VERSION "HNNBNNNYNNNNNNNNNNNNNNNNNNNNNNNNNNNNNNNNNN/4/%%%/4/'%**4NNN///"

NS_ :

BS_:

BU_: AWC BAP_Tester BMC_MLBevo BMS_MV BMS_NV DCDC_800V_PAG DCDC_HV DCDC_HV_02 DCDC_IHEV FCU_MLBevo_FCEV Gateway Gateway_PAG Ladegeraet_2 Ladegeraet_Konzern LE1 LE2 LE2_3_MLBevo_LB LE_MLBevo LE_MLBevo_LB Sub_Gateway TME

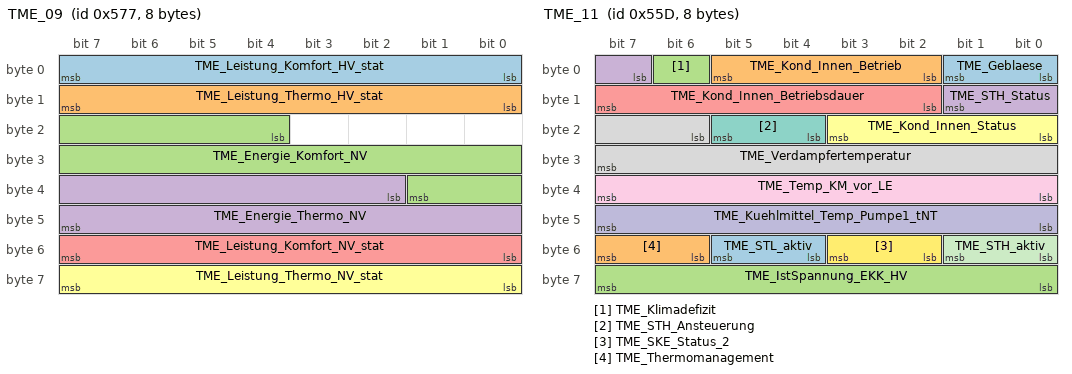
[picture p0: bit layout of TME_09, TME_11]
BO_ 1399 TME_09: 8 TME
 SG_ TME_Leistung_Komfort_HV_stat : 0|8@1+ (50,0) [0|12650] "Unit_Watt"  Ladegeraet_Konzern
 SG_ TME_Leistung_Thermo_HV_stat : 8|8@1+ (50,0) [0|12650] "Unit_Watt"  Ladegeraet_Konzern
 SG_ TME_Energie_Komfort_NV : 20|14@1+ (5,0) [0|63250] "Unit_WattHour"  Ladegeraet_Konzern
 SG_ TME_Energie_Thermo_NV : 34|14@1+ (5,0) [0|63250] "Unit_WattHour"  Ladegeraet_Konzern
 SG_ TME_Leistung_Komfort_NV_stat : 48|8@1+ (10,0) [0|2530] "Unit_Watt"  Ladegeraet_Konzern
 SG_ TME_Leistung_Thermo_NV_stat : 56|8@1+ (10,0) [0|2530] "Unit_Watt"  Ladegeraet_Konzern

BO_ 1375 TME_10: 8 TME
 SG_ TME_VoKo_Strategie_Anzeige : 2|4@1+ (1,0) [0|15] ""  Gateway,Gateway_PAG,Ladegeraet_Konzern
 SG_ TME_Zuheizer_Freigabe : 6|1@1+ (1,0) [0|1] ""  Gateway,Gateway_PAG
 SG_ TME_AC_LED : 7|1@1+ (1,0) [0|1] ""  Gateway,Gateway_PAG
 SG_ TME_Heizstrategie : 8|4@1+ (1,0) [0|15] ""  Gateway,Gateway_PAG,Ladegeraet_Konzern
 SG_ TME_Systemstatus : 12|2@1+ (1,0) [0|3] ""  Gateway,Gateway_PAG
 SG_ TME_Kbr_Innenraum : 14|1@1+ (1,0) [0|1] ""  Gateway,Gateway_PAG
 SG_ TME_Freigabe_Vorkond : 15|1@1+ (1,0) [0|1] ""  Gateway,Gateway_PAG,Ladegeraet_Konzern
 SG_ TME_Verdampfer_Status : 16|1@1+ (1,0) [0|1] ""  Gateway,Gateway_PAG
 SG_ TME_Kuehlmittel_Sensor : 17|1@1+ (1,0) [0|1] ""  BMC_MLBevo,Gateway,Gateway_PAG
 SG_ TME_AC_Rueckmeldung : 18|2@1+ (1,0) [0|3] ""  Gateway,Gateway_PAG
 SG_ TME_Heizungspumpen_Anst : 20|4@1+ (10,0) [0|100] "Unit_PerCent"  FCU_MLBevo_FCEV,Gateway,Gateway_PAG
 SG_ TME_Frischluftklappe_Soll : 24|7@1+ (1,0) [0|100] "Unit_PerCent"  Gateway,Gateway_PAG
 SG_ TME_Freigabe_Luft_PTC : 31|1@1+ (1,0) [0|1] ""  Gateway,Gateway_PAG
 SG_ TME_Umluftklappe_Soll : 32|7@1+ (1,0) [0|100] "Unit_PerCent"  Gateway,Gateway_PAG
 SG_ TME_Waermepumpe_aktiv : 39|1@1+ (1,0) [0|1] ""  Gateway,Gateway_PAG
 SG_ TME_Nachlaufzeit_Heizp : 40|6@1+ (15,0) [0|945] "Unit_Secon"  Gateway,Gateway_PAG
 SG_ TME_Absperrventil1_oeffnen : 46|2@1+ (1,0) [0|3] ""  Gateway,Gateway_PAG
 SG_ TME_Klima_Defizit : 48|8@1+ (40,0) [0|10000] "Unit_Watt"  Gateway,Gateway_PAG
 SG_ TME_Temp_KM_vor_HWT : 56|8@1+ (0.75,-40) [-40|149.75] "Unit_DegreCelsi"  Gateway,Gateway_PAG

BO_ 1373 TME_11: 8 TME
 SG_ TME_Geblaese : 0|2@1+ (1,0) [0|3] ""  Gateway,Gateway_PAG
 SG_ TME_Kond_Innen_Betrieb : 2|4@1+ (1,0) [0|15] ""  Gateway,Gateway_PAG,Ladegeraet_Konzern
 SG_ TME_Klimadefizit : 6|1@1+ (1,0) [0|1] ""  Gateway,Gateway_PAG
 SG_ TME_STH_Status : 7|3@1+ (1,0) [0|7] ""  Gateway,Gateway_PAG,Ladegeraet_Konzern
 SG_ TME_Kond_Innen_Betriebsdauer : 10|6@1+ (1,0) [0|60] "Unit_Minut"  Gateway,Gateway_PAG,Ladegeraet_Konzern
 SG_ TME_Kond_Innen_Status : 16|4@1+ (1,0) [0|15] ""  Gateway,Gateway_PAG,Ladegeraet_Konzern
 SG_ TME_STH_Ansteuerung : 20|2@1+ (1,0) [0|3] ""  Gateway,Gateway_PAG
 SG_ TME_Verdampfertemperatur : 22|10@1+ (0.1,-20) [-20|70] "Unit_DegreCelsi"  Gateway,Gateway_PAG
 SG_ TME_Temp_KM_vor_LE : 32|8@1+ (0.75,-48) [-48|141.75] "Unit_DegreCelsi"  Gateway,Gateway_PAG,LE1,LE2,LE_MLBevo
 SG_ TME_Kuehlmittel_Temp_Pumpe1_tNT : 40|8@1+ (1,-40) [-40|213] "Unit_DegreCelsi"  BMC_MLBevo,Gateway,Gateway_PAG
 SG_ TME_STH_aktiv : 48|2@1+ (1,0) [0|3] ""  Gateway,Gateway_PAG
 SG_ TME_SKE_Status_2 : 50|2@1+ (1,0) [0|3] ""  Gateway,Gateway_PAG
 SG_ TME_STL_aktiv : 52|2@1+ (1,0) [0|3] ""  Gateway,Gateway_PAG
 SG_ TME_Thermomanagement : 54|2@1+ (1,0) [0|3] ""  Gateway,Gateway_PAG
 SG_ TME_IstSpannung_EKK_HV : 56|8@1+ (2,0) [0|508] "Unit_Volt"  BMC_MLBevo,DCDC_800V_PAG,Gateway,Gateway_PAG

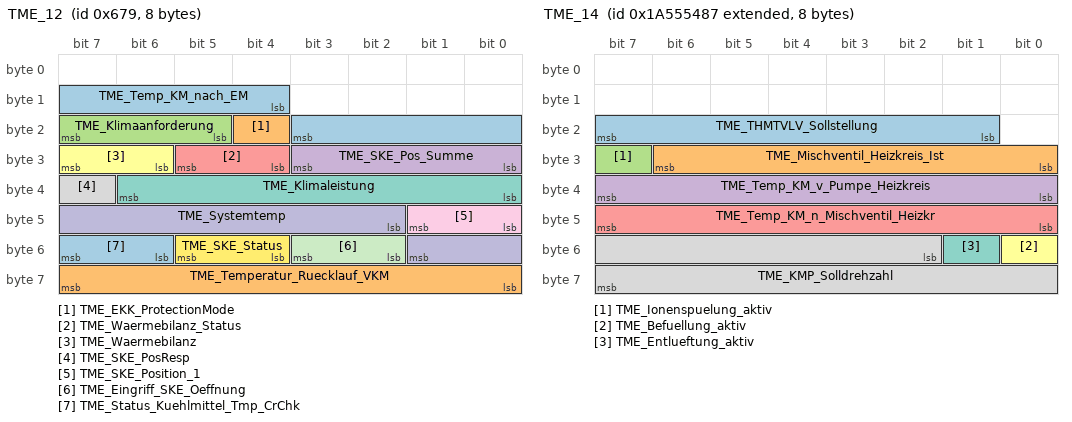
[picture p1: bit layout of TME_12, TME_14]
BO_ 1657 TME_12: 8 TME
 SG_ TME_Temp_KM_nach_EM : 12|8@1+ (0.75,-48) [-48|141] "Unit_DegreCelsi"  Gateway,Gateway_PAG
 SG_ TME_EKK_ProtectionMode : 20|1@1+ (1,0) [0|1] ""  Gateway,Gateway_PAG
 SG_ TME_Klimaanforderung : 21|3@1+ (1,0) [0|7] ""  Gateway,Gateway_PAG
 SG_ TME_SKE_Pos_Summe : 24|4@1+ (10,0) [0|100] "Unit_PerCent"  Gateway,Gateway_PAG
 SG_ TME_Waermebilanz_Status : 28|2@1+ (1,0) [0|3] ""  Gateway,Gateway_PAG
 SG_ TME_Waermebilanz : 30|2@1+ (1,0) [0|3] ""  Gateway,Gateway_PAG
 SG_ TME_Klimaleistung : 32|7@1+ (0.04,0) [0|5] "Unit_KiloWatt"  Gateway,Gateway_PAG
 SG_ TME_SKE_PosResp : 39|1@1+ (1,0) [0|1] ""  Gateway,Gateway_PAG
 SG_ TME_SKE_Position_1 : 40|2@1+ (1,0) [0|3] ""  Gateway,Gateway_PAG
 SG_ TME_Systemtemp : 42|8@1+ (0.75,-48) [-48|141.75] "Unit_DegreCelsi"  Gateway,Gateway_PAG
 SG_ TME_Eingriff_SKE_Oeffnung : 50|2@1+ (1,0) [0|3] ""  Gateway,Gateway_PAG
 SG_ TME_SKE_Status : 52|2@1+ (1,0) [0|3] ""  Gateway,Gateway_PAG
 SG_ TME_Status_Kuehlmittel_Tmp_CrChk : 54|2@1+ (1,0) [0|3] ""  Gateway,Gateway_PAG
 SG_ TME_Temperatur_Ruecklauf_VKM : 56|8@1+ (0.75,-40) [-40|149.75] "Unit_DegreCelsi"  Gateway,Gateway_PAG

BO_ 2463978655 TME_13: 8 TME
 SG_ TME_Senkenleistung_verfuegbar : 55|9@1+ (0.1,0) [0|50.9] "Unit_KiloWatt"  FCU_MLBevo_FCEV,Gateway

BO_ 2589283463 TME_14: 8 TME
 SG_ TME_THMTVLV_Sollstellung : 17|7@1+ (1,0) [0|100] "Unit_PerCent"  FCU_MLBevo_FCEV
 SG_ TME_Mischventil_Heizkreis_Ist : 24|7@1+ (1,0) [0|100] "Unit_PerCent"  FCU_MLBevo_FCEV
 SG_ TME_Ionenspuelung_aktiv : 31|1@1+ (1,0) [0|1] ""  FCU_MLBevo_FCEV
 SG_ TME_Temp_KM_v_Pumpe_Heizkreis : 32|8@1+ (0.75,-48) [-48|141.75] "Unit_DegreCelsi"  FCU_MLBevo_FCEV
 SG_ TME_Temp_KM_n_Mischventil_Heizkr : 40|8@1+ (0.75,-48) [-48|141.75] "Unit_DegreCelsi"  FCU_MLBevo_FCEV
 SG_ TME_Befuellung_aktiv : 48|1@1+ (1,0) [0|1] ""  FCU_MLBevo_FCEV
 SG_ TME_Entlueftung_aktiv : 49|1@1+ (1,0) [0|1] ""  FCU_MLBevo_FCEV
 SG_ TME_KMP_Solldrehzahl : 50|14@1+ (1,0) [0|16381] "Unit_RevPerMinute"  FCU_MLBevo_FCEV

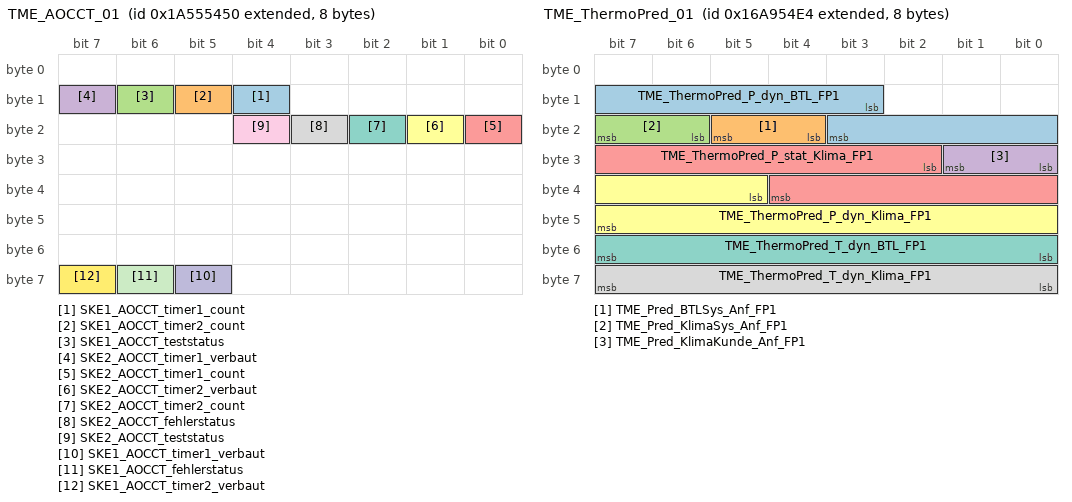
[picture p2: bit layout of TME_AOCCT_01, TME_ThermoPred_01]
BO_ 2589283408 TME_AOCCT_01: 8 TME
 SG_ SKE1_AOCCT_timer1_count : 12|1@1+ (1,0) [0|1] ""  Gateway,Gateway_PAG
 SG_ SKE1_AOCCT_timer2_count : 13|1@1+ (1,0) [0|1] ""  Gateway,Gateway_PAG
 SG_ SKE1_AOCCT_teststatus : 14|1@1+ (1,0) [0|1] ""  Gateway,Gateway_PAG
 SG_ SKE2_AOCCT_timer1_verbaut : 15|1@1+ (1,0) [0|1] ""  Gateway,Gateway_PAG
 SG_ SKE2_AOCCT_timer1_count : 16|1@1+ (1,0) [0|1] ""  Gateway,Gateway_PAG
 SG_ SKE2_AOCCT_timer2_verbaut : 17|1@1+ (1,0) [0|1] ""  Gateway,Gateway_PAG
 SG_ SKE2_AOCCT_timer2_count : 18|1@1+ (1,0) [0|1] ""  Gateway,Gateway_PAG
 SG_ SKE2_AOCCT_fehlerstatus : 19|1@1+ (1,0) [0|1] ""  Gateway,Gateway_PAG
 SG_ SKE2_AOCCT_teststatus : 20|1@1+ (1,0) [0|1] ""  Gateway,Gateway_PAG
 SG_ SKE1_AOCCT_timer1_verbaut : 61|1@1+ (1,0) [0|1] ""  Gateway,Gateway_PAG
 SG_ SKE1_AOCCT_fehlerstatus : 62|1@1+ (1,0) [0|1] ""  Gateway,Gateway_PAG
 SG_ SKE1_AOCCT_timer2_verbaut : 63|1@1+ (1,0) [0|1] ""  Gateway,Gateway_PAG

BO_ 2527679716 TME_ThermoPred_01: 8 TME
 SG_ TME_ThermoPred_P_dyn_BTL_FP1 : 11|9@1+ (50,0) [0|20450] "Unit_Watt"  Gateway,Gateway_PAG
 SG_ TME_Pred_BTLSys_Anf_FP1 : 20|2@1+ (1,0) [0|3] ""  Gateway,Gateway_PAG
 SG_ TME_Pred_KlimaSys_Anf_FP1 : 22|2@1+ (1,0) [0|3] ""  Gateway,Gateway_PAG
 SG_ TME_Pred_KlimaKunde_Anf_FP1 : 24|2@1+ (1,0) [0|3] ""  Gateway,Gateway_PAG
 SG_ TME_ThermoPred_P_stat_Klima_FP1 : 26|11@1+ (10,0) [0|20450] "Unit_Watt"  Gateway,Gateway_PAG
 SG_ TME_ThermoPred_P_dyn_Klima_FP1 : 37|11@1+ (10,0) [0|20450] "Unit_Watt"  Gateway,Gateway_PAG
 SG_ TME_ThermoPred_T_dyn_BTL_FP1 : 48|8@1+ (1,0) [0|253] "Unit_Minut"  Gateway,Gateway_PAG
 SG_ TME_ThermoPred_T_dyn_Klima_FP1 : 56|8@1+ (1,0) [0|253] "Unit_Minut"  Gateway,Gateway_PAG

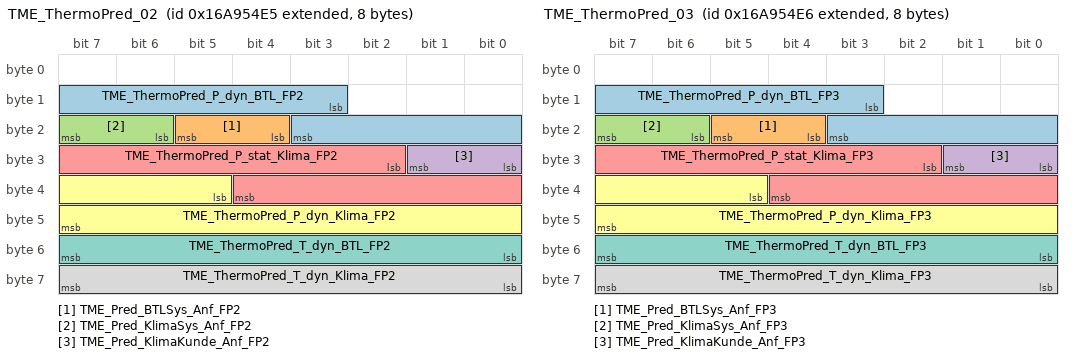
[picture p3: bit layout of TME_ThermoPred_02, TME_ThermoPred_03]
BO_ 2527679717 TME_ThermoPred_02: 8 TME
 SG_ TME_ThermoPred_P_dyn_BTL_FP2 : 11|9@1+ (50,0) [0|20450] "Unit_Watt"  Gateway,Gateway_PAG
 SG_ TME_Pred_BTLSys_Anf_FP2 : 20|2@1+ (1,0) [0|3] ""  Gateway,Gateway_PAG
 SG_ TME_Pred_KlimaSys_Anf_FP2 : 22|2@1+ (1,0) [0|3] ""  Gateway,Gateway_PAG
 SG_ TME_Pred_KlimaKunde_Anf_FP2 : 24|2@1+ (1,0) [0|3] ""  Gateway,Gateway_PAG
 SG_ TME_ThermoPred_P_stat_Klima_FP2 : 26|11@1+ (10,0) [0|20450] "Unit_Watt"  Gateway,Gateway_PAG
 SG_ TME_ThermoPred_P_dyn_Klima_FP2 : 37|11@1+ (10,0) [0|20450] "Unit_Watt"  Gateway,Gateway_PAG
 SG_ TME_ThermoPred_T_dyn_BTL_FP2 : 48|8@1+ (1,0) [0|253] "Unit_Minut"  Gateway,Gateway_PAG
 SG_ TME_ThermoPred_T_dyn_Klima_FP2 : 56|8@1+ (1,0) [0|253] "Unit_Minut"  Gateway,Gateway_PAG

BO_ 2527679718 TME_ThermoPred_03: 8 TME
 SG_ TME_ThermoPred_P_dyn_BTL_FP3 : 11|9@1+ (50,0) [0|20450] "Unit_Watt"  Gateway,Gateway_PAG
 SG_ TME_Pred_BTLSys_Anf_FP3 : 20|2@1+ (1,0) [0|3] ""  Gateway,Gateway_PAG
 SG_ TME_Pred_KlimaSys_Anf_FP3 : 22|2@1+ (1,0) [0|3] ""  Gateway,Gateway_PAG
 SG_ TME_Pred_KlimaKunde_Anf_FP3 : 24|2@1+ (1,0) [0|3] ""  Gateway,Gateway_PAG
 SG_ TME_ThermoPred_P_stat_Klima_FP3 : 26|11@1+ (10,0) [0|20450] "Unit_Watt"  Gateway,Gateway_PAG
 SG_ TME_ThermoPred_P_dyn_Klima_FP3 : 37|11@1+ (10,0) [0|20450] "Unit_Watt"  Gateway,Gateway_PAG
 SG_ TME_ThermoPred_T_dyn_BTL_FP3 : 48|8@1+ (1,0) [0|253] "Unit_Minut"  Gateway,Gateway_PAG
 SG_ TME_ThermoPred_T_dyn_Klima_FP3 : 56|8@1+ (1,0) [0|253] "Unit_Minut"  Gateway,Gateway_PAG

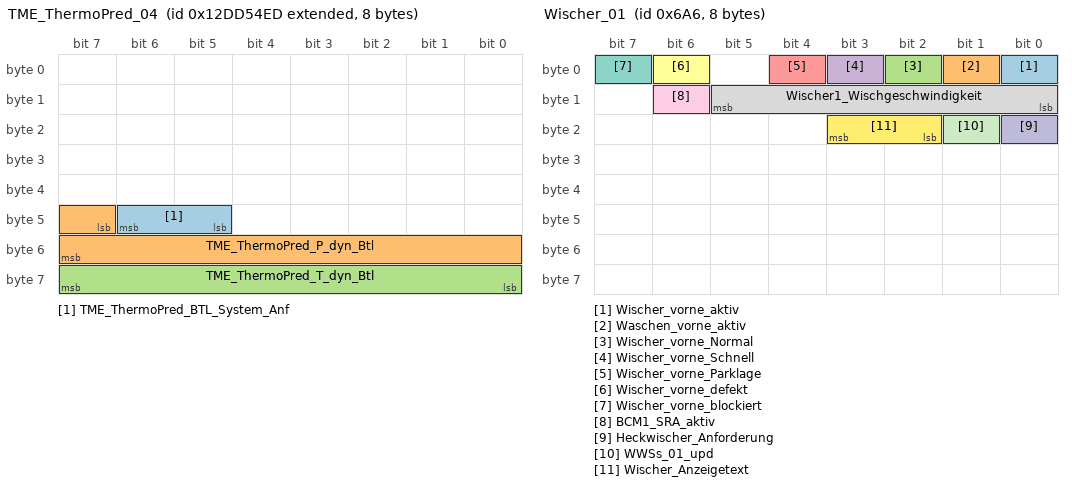
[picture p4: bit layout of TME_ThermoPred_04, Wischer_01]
BO_ 2463978733 TME_ThermoPred_04: 8 TME
 SG_ TME_ThermoPred_BTL_System_Anf : 45|2@1+ (1,0) [0|3] ""  Gateway,Gateway_PAG
 SG_ TME_ThermoPred_P_dyn_Btl : 47|9@1+ (50,0) [0|20450] "Unit_Watt"  Gateway,Gateway_PAG
 SG_ TME_ThermoPred_T_dyn_Btl : 56|8@1+ (1,0) [0|255] ""  Gateway,Gateway_PAG

BO_ 977 TSG_BT_01: 8 Gateway
 SG_ BT_Tuer_geoeffnet : 0|1@1+ (1,0) [0|1] ""  Ladegeraet_Konzern,TME
 SG_ BT_verriegelt : 1|1@1+ (1,0) [0|1] "" Vector__XXX
 SG_ BT_gesafet : 2|1@1+ (1,0) [0|1] "" Vector__XXX
 SG_ BT_Schluesselschalter_auf : 3|1@1+ (1,0) [0|1] "" Vector__XXX
 SG_ BT_Schluesselschalter_zu : 4|1@1+ (1,0) [0|1] "" Vector__XXX
 SG_ BT_Unlock_Taster : 5|1@1+ (1,0) [0|1] "" Vector__XXX
 SG_ BT_Lock_Taster : 6|1@1+ (1,0) [0|1] "" Vector__XXX
 SG_ BT_Sperrklinke : 7|1@1+ (1,0) [0|1] "" Vector__XXX
 SG_ BT_TAG_betaetigt : 8|1@1+ (1,0) [0|1] "" Vector__XXX
 SG_ BT_TIG_betaetigt : 9|1@1+ (1,0) [0|1] "" Vector__XXX
 SG_ BT_EC_Spiegel_Helligkeit : 10|5@1+ (3.125,0) [0|96.875] "Unit_PerCent" Vector__XXX
 SG_ BT_Sp_Heizung_Anf : 15|1@1+ (100,0) [0|100] "Unit_PerCent" Vector__XXX
 SG_ BT_Tuer_Status : 16|2@1+ (1,0) [0|3] "" Vector__XXX
 SG_ BT_TSG_hinten_verbaut : 18|1@1+ (1,0) [0|1] "" Vector__XXX
 SG_ BT_Sp_Blk_def : 19|1@1+ (1,0) [0|1] "" Vector__XXX
 SG_ BT_FH_S_ManHoch : 20|1@1+ (1,0) [0|1] "" Vector__XXX
 SG_ BT_FH_S_AutoHoch : 21|1@1+ (1,0) [0|1] "" Vector__XXX
 SG_ BT_FH_S_ManTief : 22|1@1+ (1,0) [0|1] "" Vector__XXX
 SG_ BT_FH_S_AutoTief : 23|1@1+ (1,0) [0|1] "" Vector__XXX
 SG_ BT_FH_Oeffnung : 24|8@1+ (0.5,0) [0|100] "Unit_PerCent"  TME
 SG_ BT_FH_Bew_hoch : 32|1@1+ (1,0) [0|1] "" Vector__XXX
 SG_ BT_FH_Bew_tief : 33|1@1+ (1,0) [0|1] "" Vector__XXX
 SG_ BT_FH_Fang : 34|1@1+ (1,0) [0|1] "" Vector__XXX
 SG_ BT_FH_Block : 35|1@1+ (1,0) [0|1] "" Vector__XXX
 SG_ BT_FH_Thermo : 36|1@1+ (1,0) [0|1] "" Vector__XXX
 SG_ BT_UEKB_aktiviert : 37|1@1+ (1,0) [0|1] "" Vector__XXX
 SG_ BT_Kisi_Fehler : 38|1@1+ (1,0) [0|1] "" Vector__XXX
 SG_ BT_FH_normiert : 39|1@1+ (1,0) [0|1] "" Vector__XXX
 SG_ BT_Schliesstaster : 40|1@1+ (1,0) [0|1] "" Vector__XXX
 SG_ BT_Zuziehhilfe_aktiv : 41|1@1+ (1,0) [0|1] "" Vector__XXX
 SG_ BT_SP_ausgerastet : 42|1@1+ (1,0) [0|1] "" Vector__XXX
 SG_ BT_SP_lr_aktiv : 43|1@1+ (1,0) [0|1] "" Vector__XXX
 SG_ BT_SP_ht_aktiv : 44|1@1+ (1,0) [0|1] "" Vector__XXX
 SG_ BT_SP_Heizung_aktiv : 45|1@1+ (1,0) [0|1] "" Vector__XXX
 SG_ BT_Oben_Block_erw : 46|1@1+ (1,0) [0|1] "" Vector__XXX
 SG_ BT_Unten_Block_erw : 47|1@1+ (1,0) [0|1] "" Vector__XXX
 SG_ BT_Tuer_Status_QBit : 48|1@1+ (1,0) [0|1] "" Vector__XXX
 SG_ BFS_Status_eTAG : 49|2@1+ (1,0) [0|3] "" Vector__XXX
 SG_ BT_TCR_Mode_aktiv : 51|1@1+ (1,0) [0|1] "" Vector__XXX
 SG_ BT_SP_Heizung_Status : 55|1@1+ (1,0) [0|1] "" Vector__XXX
 SG_ ASW_Warnung_aktiv_BFS : 56|1@1+ (1,0) [0|1] "" Vector__XXX
 SG_ BT_FH_Pos_oben : 57|1@1+ (1,0) [0|1] "" Vector__XXX
 SG_ BT_Tuerschloss_defekt : 58|1@1+ (1,0) [0|1] "" Vector__XXX
 SG_ BT_Tueroeffnen_Warnung : 59|1@1+ (1,0) [0|1] "" Vector__XXX
 SG_ BT_Lock_Taster_inv : 60|1@1+ (1,0) [0|1] "" Vector__XXX
 SG_ BT_Schluesselschalter_zu_inv : 61|1@1+ (1,0) [0|1] "" Vector__XXX
 SG_ BT_SWA_HMI_defekt : 62|1@1+ (1,0) [0|1] "" Vector__XXX
 SG_ BT_ASW_HMI_defekt : 63|1@1+ (1,0) [0|1] "" Vector__XXX

BO_ 976 TSG_FT_01: 8 Gateway
 SG_ FT_Tuer_geoeffnet : 0|1@1+ (1,0) [0|1] ""  Ladegeraet_Konzern,TME
 SG_ FT_verriegelt : 1|1@1+ (1,0) [0|1] "" Vector__XXX
 SG_ FT_gesafet : 2|1@1+ (1,0) [0|1] "" Vector__XXX
 SG_ FT_Schluesselschalter_auf : 3|1@1+ (1,0) [0|1] ""  FCU_MLBevo_FCEV
 SG_ FT_Schluesselschalter_zu : 4|1@1+ (1,0) [0|1] ""  FCU_MLBevo_FCEV
 SG_ FT_Unlock_Taster : 5|1@1+ (1,0) [0|1] "" Vector__XXX
 SG_ FT_Lock_Taster : 6|1@1+ (1,0) [0|1] "" Vector__XXX
 SG_ FT_Sperrklinke : 7|1@1+ (1,0) [0|1] "" Vector__XXX
 SG_ FT_TAG_betaetigt : 8|1@1+ (1,0) [0|1] "" Vector__XXX
 SG_ FT_TIG_betaetigt : 9|1@1+ (1,0) [0|1] "" Vector__XXX
 SG_ FT_IRUE_Taste : 10|1@1+ (1,0) [0|1] "" Vector__XXX
 SG_ FT_HD_Taste : 11|1@1+ (1,0) [0|1] "" Vector__XXX
 SG_ FT_TD_Taste_Fehler : 12|1@1+ (1,0) [0|1] ""  Ladegeraet_Konzern
 SG_ FT_TD_Taste : 13|1@1+ (1,0) [0|1] ""  FCU_MLBevo_FCEV,Ladegeraet_Konzern
 SG_ SSR_Temp_Freigabe : 14|1@1+ (1,0) [0|1] "" Vector__XXX
 SG_ FT_Sp_Heizung_Anf : 15|1@1+ (100,0) [0|100] "Unit_PerCent" Vector__XXX
 SG_ FT_HD_Taste_2 : 16|1@1+ (1,0) [0|1] "" Vector__XXX
 SG_ FT_TSG_hinten_verbaut : 18|1@1+ (1,0) [0|1] "" Vector__XXX
 SG_ FT_Sp_Blk_def : 19|1@1+ (1,0) [0|1] "" Vector__XXX
 SG_ FT_FH_S_ManHoch : 20|1@1+ (1,0) [0|1] "" Vector__XXX
 SG_ FT_FH_S_AutoHoch : 21|1@1+ (1,0) [0|1] "" Vector__XXX
 SG_ FT_FH_S_ManTief : 22|1@1+ (1,0) [0|1] "" Vector__XXX
 SG_ FT_FH_S_AutoTief : 23|1@1+ (1,0) [0|1] "" Vector__XXX
 SG_ FT_FH_Oeffnung : 24|8@1+ (0.5,0) [0|100] "Unit_PerCent"  TME
 SG_ FT_FH_Bew_hoch : 32|1@1+ (1,0) [0|1] "" Vector__XXX
 SG_ FT_FH_Bew_tief : 33|1@1+ (1,0) [0|1] "" Vector__XXX
 SG_ FT_FH_Fang : 34|1@1+ (1,0) [0|1] "" Vector__XXX
 SG_ FT_FH_Block : 35|1@1+ (1,0) [0|1] "" Vector__XXX
 SG_ FT_FH_Thermo : 36|1@1+ (1,0) [0|1] "" Vector__XXX
 SG_ FT_UEKB_aktiviert : 37|1@1+ (1,0) [0|1] "" Vector__XXX
 SG_ ASW_HMI_defekt : 38|1@1+ (1,0) [0|1] "" Vector__XXX
 SG_ FT_FH_normiert : 39|1@1+ (1,0) [0|1] "" Vector__XXX
 SG_ FT_Schliesstaster : 40|1@1+ (1,0) [0|1] "" Vector__XXX
 SG_ FT_Zuziehhilfe_aktiv : 41|1@1+ (1,0) [0|1] "" Vector__XXX
 SG_ FT_SP_ausgerastet : 42|1@1+ (1,0) [0|1] "" Vector__XXX
 SG_ FT_SP_lr_aktiv : 43|1@1+ (1,0) [0|1] "" Vector__XXX
 SG_ FT_SP_ht_aktiv : 44|1@1+ (1,0) [0|1] "" Vector__XXX
 SG_ ASW_wakeup : 45|1@1+ (1,0) [0|1] "" Vector__XXX
 SG_ FT_Oben_Block_erw : 46|1@1+ (1,0) [0|1] "" Vector__XXX
 SG_ FT_Unten_Block_erw : 47|1@1+ (1,0) [0|1] "" Vector__XXX
 SG_ FT_Kisi_li_aktiv : 48|1@1+ (1,0) [0|1] "" Vector__XXX
 SG_ FT_Kisi_re_aktiv : 49|1@1+ (1,0) [0|1] "" Vector__XXX
 SG_ FT_Kisi_Taster_li : 50|1@1+ (1,0) [0|1] "" Vector__XXX
 SG_ FT_Kisi_Taster_re : 51|1@1+ (1,0) [0|1] "" Vector__XXX
 SG_ FT_BFS_Fond_Freigabe : 52|1@1+ (1,0) [0|1] "" Vector__XXX
 SG_ FT_Kisi_Fehler : 53|1@1+ (1,0) [0|1] "" Vector__XXX
 SG_ FT_Daemmglas : 54|1@1+ (1,0) [0|1] "" Vector__XXX
 SG_ FT_SP_Heizung_Status : 55|1@1+ (1,0) [0|1] "" Vector__XXX
 SG_ ASW_Warnung_aktiv_FS : 56|1@1+ (1,0) [0|1] "" Vector__XXX
 SG_ FT_FH_Pos_oben : 57|1@1+ (1,0) [0|1] "" Vector__XXX
 SG_ FT_Tuerschloss_defekt : 58|1@1+ (1,0) [0|1] "" Vector__XXX
 SG_ FT_SWA_Taster : 59|1@1+ (1,0) [0|1] "" Vector__XXX
 SG_ SWA_HMI_Diagnose : 60|2@1+ (1,0) [0|3] "" Vector__XXX
 SG_ FS_Status_eTAG : 62|2@1+ (1,0) [0|3] "" Vector__XXX

BO_ 975 TSG_HBFS_01: 8 Gateway
 SG_ HBFS_Tuer_geoeffnet : 0|1@1+ (1,0) [0|1] "" Vector__XXX
 SG_ HBFS_verriegelt : 1|1@1+ (1,0) [0|1] "" Vector__XXX
 SG_ HBFS_gesafet : 2|1@1+ (1,0) [0|1] "" Vector__XXX
 SG_ HBFS_Heckrollotaster_betaetigt : 3|1@1+ (1,0) [0|1] "" Vector__XXX
 SG_ HBFS_Tuerschloss_defekt : 4|1@1+ (1,0) [0|1] "" Vector__XXX
 SG_ HBFS_Unlock_Taster : 5|1@1+ (1,0) [0|1] "" Vector__XXX
 SG_ HBFS_Lock_Taster : 6|1@1+ (1,0) [0|1] "" Vector__XXX
 SG_ HBFS_Sperrklinke : 7|1@1+ (1,0) [0|1] "" Vector__XXX
 SG_ HBFS_TAG_betaetigt : 8|1@1+ (1,0) [0|1] "" Vector__XXX
 SG_ HBFS_TIG_betaetigt : 9|1@1+ (1,0) [0|1] "" Vector__XXX
 SG_ HBFS_FH_S_HFS_AutoHoch : 10|1@1+ (1,0) [0|1] "" Vector__XXX
 SG_ HBFS_FH_S_HFS_AutoTief : 11|1@1+ (1,0) [0|1] "" Vector__XXX
 SG_ HBFS_FH_S_HFS_ManHoch : 12|1@1+ (1,0) [0|1] "" Vector__XXX
 SG_ HBFS_FH_S_HFS_ManTief : 13|1@1+ (1,0) [0|1] "" Vector__XXX
 SG_ HBFS_Tuer_Status : 14|2@1+ (1,0) [0|3] "" Vector__XXX
 SG_ HBFS_SAD_Schalter : 16|4@1+ (1,0) [0|15] "" Vector__XXX
 SG_ HBFS_FH_S_ManHoch : 20|1@1+ (1,0) [0|1] "" Vector__XXX
 SG_ HBFS_FH_S_AutoHoch : 21|1@1+ (1,0) [0|1] "" Vector__XXX
 SG_ HBFS_FH_S_ManTief : 22|1@1+ (1,0) [0|1] "" Vector__XXX
 SG_ HBFS_FH_S_AutoTief : 23|1@1+ (1,0) [0|1] "" Vector__XXX
 SG_ HBFS_FH_Oeffnung : 24|8@1+ (0.5,0) [0|100] "Unit_PerCent" Vector__XXX
 SG_ HBFS_FH_Bew_hoch : 32|1@1+ (1,0) [0|1] "" Vector__XXX
 SG_ HBFS_FH_Bew_tief : 33|1@1+ (1,0) [0|1] "" Vector__XXX
 SG_ HBFS_FH_Fang : 34|1@1+ (1,0) [0|1] "" Vector__XXX
 SG_ HBFS_FH_Block : 35|1@1+ (1,0) [0|1] "" Vector__XXX
 SG_ HBFS_FH_Thermo : 36|1@1+ (1,0) [0|1] "" Vector__XXX
 SG_ HBFS_UEKB_aktiviert : 37|1@1+ (1,0) [0|1] "" Vector__XXX
 SG_ HBFS_Tueroeffnen_Warnung : 38|1@1+ (1,0) [0|1] "" Vector__XXX
 SG_ HBFS_FH_normiert : 39|1@1+ (1,0) [0|1] "" Vector__XXX
 SG_ ASW_Warnung_aktiv_HBFS : 40|1@1+ (1,0) [0|1] "" Vector__XXX
 SG_ HBFS_Zuziehhilfe_aktiv : 41|1@1+ (1,0) [0|1] "" Vector__XXX
 SG_ HBFS_Seitenrollo_hoch : 42|1@1+ (1,0) [0|1] ""  TME
 SG_ HBFS_Seitenrollo_tief : 43|1@1+ (1,0) [0|1] ""  TME
 SG_ HBFS_Status_KiSi : 44|1@1+ (1,0) [0|1] "" Vector__XXX
 SG_ SSR_HBFS_Pos_Unten : 45|1@1+ (1,0) [0|1] "" Vector__XXX
 SG_ HBFS_Oben_Block_erw : 46|1@1+ (1,0) [0|1] "" Vector__XXX
 SG_ HBFS_Unten_Block_erw : 47|1@1+ (1,0) [0|1] "" Vector__XXX
 SG_ MTHBFS_M_Taste : 48|1@1+ (1,0) [0|1] "" Vector__XXX
 SG_ MTHBFS_Pos1 : 49|1@1+ (1,0) [0|1] "" Vector__XXX
 SG_ MTHBFS_Pos2 : 50|1@1+ (1,0) [0|1] "" Vector__XXX
 SG_ MTHBFS_Pos3 : 51|1@1+ (1,0) [0|1] "" Vector__XXX
 SG_ HBFS_MRollo_Schalter : 52|3@1+ (1,0) [0|7] "" Vector__XXX
 SG_ HBFS_Lock_Taster_inv : 55|1@1+ (1,0) [0|1] "" Vector__XXX
 SG_ HBFS_Status_KiSi_inv : 56|1@1+ (1,0) [0|1] "" Vector__XXX
 SG_ HBFS_Status_eTAG : 57|2@1+ (1,0) [0|3] "" Vector__XXX
 SG_ HBFS_Tuer_Status_QBit : 59|1@1+ (1,0) [0|1] "" Vector__XXX
 SG_ HBFS_TIG_betaetigt_schliessen : 60|1@1+ (1,0) [0|1] "" Vector__XXX

BO_ 974 TSG_HFS_01: 8 Gateway
 SG_ HFS_Tuer_geoeffnet : 0|1@1+ (1,0) [0|1] "" Vector__XXX
 SG_ HFS_verriegelt : 1|1@1+ (1,0) [0|1] "" Vector__XXX
 SG_ HFS_gesafet : 2|1@1+ (1,0) [0|1] "" Vector__XXX
 SG_ HFS_Heckrollotaster_betaetigt : 3|1@1+ (1,0) [0|1] "" Vector__XXX
 SG_ HFS_Tuerschloss_defekt : 4|1@1+ (1,0) [0|1] "" Vector__XXX
 SG_ HFS_Unlock_Taster : 5|1@1+ (1,0) [0|1] "" Vector__XXX
 SG_ HFS_Lock_Taster : 6|1@1+ (1,0) [0|1] "" Vector__XXX
 SG_ HFS_Sperrklinke : 7|1@1+ (1,0) [0|1] "" Vector__XXX
 SG_ HFS_TAG_betaetigt : 8|1@1+ (1,0) [0|1] "" Vector__XXX
 SG_ HFS_TIG_betaetigt : 9|1@1+ (1,0) [0|1] "" Vector__XXX
 SG_ HFS_FH_S_HBFS_AutoHoch : 10|1@1+ (1,0) [0|1] "" Vector__XXX
 SG_ HFS_FH_S_HBFS_AutoTief : 11|1@1+ (1,0) [0|1] "" Vector__XXX
 SG_ HFS_FH_S_HBFS_ManHoch : 12|1@1+ (1,0) [0|1] "" Vector__XXX
 SG_ HFS_FH_S_HBFS_ManTief : 13|1@1+ (1,0) [0|1] "" Vector__XXX
 SG_ HFS_Tuer_Status : 14|2@1+ (1,0) [0|3] "" Vector__XXX
 SG_ HFS_SAD_Schalter : 16|4@1+ (1,0) [0|15] "" Vector__XXX
 SG_ HFS_FH_S_ManHoch : 20|1@1+ (1,0) [0|1] "" Vector__XXX
 SG_ HFS_FH_S_AutoHoch : 21|1@1+ (1,0) [0|1] "" Vector__XXX
 SG_ HFS_FH_S_ManTief : 22|1@1+ (1,0) [0|1] "" Vector__XXX
 SG_ HFS_FH_S_AutoTief : 23|1@1+ (1,0) [0|1] "" Vector__XXX
 SG_ HFS_FH_Oeffnung : 24|8@1+ (0.5,0) [0|100] "Unit_PerCent" Vector__XXX
 SG_ HFS_FH_Bew_hoch : 32|1@1+ (1,0) [0|1] "" Vector__XXX
 SG_ HFS_FH_Bew_tief : 33|1@1+ (1,0) [0|1] "" Vector__XXX
 SG_ HFS_FH_Fang : 34|1@1+ (1,0) [0|1] "" Vector__XXX
 SG_ HFS_FH_Block : 35|1@1+ (1,0) [0|1] "" Vector__XXX
 SG_ HFS_FH_Thermo : 36|1@1+ (1,0) [0|1] "" Vector__XXX
 SG_ HFS_UEKB_aktiviert : 37|1@1+ (1,0) [0|1] "" Vector__XXX
 SG_ HFS_Tueroeffnen_Warnung : 38|1@1+ (1,0) [0|1] "" Vector__XXX
 SG_ HFS_FH_normiert : 39|1@1+ (1,0) [0|1] "" Vector__XXX
 SG_ ASW_Warnung_aktiv_HFS : 40|1@1+ (1,0) [0|1] "" Vector__XXX
 SG_ HFS_Zuziehhilfe_aktiv : 41|1@1+ (1,0) [0|1] "" Vector__XXX
 SG_ HFS_Seitenrollo_hoch : 42|1@1+ (1,0) [0|1] ""  TME
 SG_ HFS_Seitenrollo_tief : 43|1@1+ (1,0) [0|1] ""  TME
 SG_ HFS_Status_KiSi : 44|1@1+ (1,0) [0|1] "" Vector__XXX
 SG_ SSR_HFS_Pos_Unten : 45|1@1+ (1,0) [0|1] "" Vector__XXX
 SG_ HFS_Oben_Block_erw : 46|1@1+ (1,0) [0|1] "" Vector__XXX
 SG_ HFS_Unten_Block_erw : 47|1@1+ (1,0) [0|1] "" Vector__XXX
 SG_ MTHFS_M_Taste : 48|1@1+ (1,0) [0|1] "" Vector__XXX
 SG_ MTHFS_Pos1 : 49|1@1+ (1,0) [0|1] "" Vector__XXX
 SG_ MTHFS_Pos2 : 50|1@1+ (1,0) [0|1] "" Vector__XXX
 SG_ MTHFS_Pos3 : 51|1@1+ (1,0) [0|1] "" Vector__XXX
 SG_ HFS_MRollo_Schalter : 52|3@1+ (1,0) [0|7] "" Vector__XXX
 SG_ HFS_Lock_Taster_inv : 55|1@1+ (1,0) [0|1] "" Vector__XXX
 SG_ HFS_Status_eTAG : 56|2@1+ (1,0) [0|3] "" Vector__XXX
 SG_ HFS_Tuer_Status_QBit : 58|1@1+ (1,0) [0|1] "" Vector__XXX
 SG_ HFS_TCR_Mode_aktiv : 59|1@1+ (1,0) [0|1] "" Vector__XXX

BO_ 1716 VIN_01: 8 Gateway
 SG_ VIN_01_MUX M : 0|2@1+ (1,0) [0|3] ""  AWC,Ladegeraet_Konzern,Sub_Gateway,TME
 SG_ KS_Geheimnis_1 m0 : 8|8@1+ (1,0) [0|255] ""  Sub_Gateway
 SG_ VIN_4 m1 : 8|8@1+ (1,0) [0|255] ""  AWC,Ladegeraet_Konzern,Sub_Gateway,TME
 SG_ VIN_11 m2 : 8|8@1+ (1,0) [0|255] ""  AWC,Ladegeraet_Konzern,Sub_Gateway,TME
 SG_ KS_Geheimnis_2 m0 : 16|8@1+ (1,0) [0|255] ""  Sub_Gateway
 SG_ VIN_5 m1 : 16|8@1+ (1,0) [0|255] ""  AWC,Ladegeraet_Konzern,Sub_Gateway,TME
 SG_ VIN_12 m2 : 16|8@1+ (1,0) [0|255] ""  AWC,Ladegeraet_Konzern,Sub_Gateway,TME
 SG_ KS_Geheimnis_3 m0 : 24|8@1+ (1,0) [0|255] ""  Sub_Gateway
 SG_ VIN_6 m1 : 24|8@1+ (1,0) [0|255] ""  AWC,Ladegeraet_Konzern,Sub_Gateway,TME
 SG_ VIN_13 m2 : 24|8@1+ (1,0) [0|255] ""  AWC,Ladegeraet_Konzern,Sub_Gateway,TME
 SG_ KS_Geheimnis_4 m0 : 32|8@1+ (1,0) [0|255] ""  Sub_Gateway
 SG_ VIN_7 m1 : 32|8@1+ (1,0) [0|255] ""  AWC,Ladegeraet_Konzern,Sub_Gateway,TME
 SG_ VIN_14 m2 : 32|8@1+ (1,0) [0|255] ""  AWC,Ladegeraet_Konzern,Sub_Gateway,TME
 SG_ VIN_1 m0 : 40|8@1+ (1,0) [0|255] ""  AWC,Ladegeraet_Konzern,Sub_Gateway,TME
 SG_ VIN_8 m1 : 40|8@1+ (1,0) [0|255] ""  AWC,Ladegeraet_Konzern,Sub_Gateway,TME
 SG_ VIN_15 m2 : 40|8@1+ (1,0) [0|255] ""  AWC,Ladegeraet_Konzern,Sub_Gateway,TME
 SG_ VIN_2 m0 : 48|8@1+ (1,0) [0|255] ""  AWC,Ladegeraet_Konzern,Sub_Gateway,TME
 SG_ VIN_9 m1 : 48|8@1+ (1,0) [0|255] ""  AWC,Ladegeraet_Konzern,Sub_Gateway,TME
 SG_ VIN_16 m2 : 48|8@1+ (1,0) [0|255] ""  AWC,Ladegeraet_Konzern,Sub_Gateway,TME
 SG_ VIN_3 m0 : 56|8@1+ (1,0) [0|255] ""  AWC,Ladegeraet_Konzern,Sub_Gateway,TME
 SG_ VIN_10 m1 : 56|8@1+ (1,0) [0|255] ""  AWC,Ladegeraet_Konzern,Sub_Gateway,TME
 SG_ VIN_17 m2 : 56|8@1+ (1,0) [0|255] ""  AWC,Ladegeraet_Konzern,Sub_Gateway,TME

BO_ 916 WBA_03: 8 Gateway
 SG_ WBA_03_CRC : 0|8@1+ (1,0) [0|255] ""  Sub_Gateway
 SG_ WBA_03_BZ : 8|4@1+ (1,0) [0|15] ""  Sub_Gateway
 SG_ WBA_Fahrstufe_02 : 12|4@1+ (1,0) [0|15] ""  Sub_Gateway
 SG_ WBA_ZielFahrstufe : 16|4@1+ (1,0) [0|15] ""  Sub_Gateway
 SG_ WBA_GE_Warnung_02 : 20|4@1+ (1,0) [0|15] ""  Sub_Gateway
 SG_ WBA_eing_Gang_02 : 24|4@1+ (1,0) [0|15] ""  Sub_Gateway
 SG_ WBA_GE_Texte : 28|3@1+ (1,0) [0|7] ""  Sub_Gateway
 SG_ WBA_Segeln_aktiv : 31|1@1+ (1,0) [0|1] ""  Sub_Gateway
 SG_ WBA_Schaltschema : 32|5@1+ (1,0) [0|31] ""  Sub_Gateway
 SG_ WBA_GE_Zusatzwarnungen : 37|3@1+ (1,0) [0|7] ""  Sub_Gateway
 SG_ GE_Sollgang : 40|4@1+ (1,0) [0|15] ""  Sub_Gateway
 SG_ GE_Tipschaltempf_verfuegbar : 44|1@1+ (1,0) [0|1] ""  Sub_Gateway
 SG_ WBA_GE_Texte_02 : 45|3@1+ (1,0) [0|7] ""  Sub_Gateway
 SG_ WBA_GE_Texte_03 : 48|4@1+ (1,0) [0|15] ""  Sub_Gateway
 SG_ WBA_Blinken : 54|1@1+ (1,0) [0|1] ""  Sub_Gateway
 SG_ GE_Wiederstart_Anz_Std : 55|1@1+ (1,0) [0|1] ""  Sub_Gateway
 SG_ GE_Stoppverbot_Anz_01 : 56|1@1+ (1,0) [0|1] ""  Sub_Gateway
 SG_ GE_Stoppverbot_Anz_02 : 57|1@1+ (1,0) [0|1] ""  Sub_Gateway
 SG_ GE_Stoppverbot_Anz_03 : 58|1@1+ (1,0) [0|1] ""  Sub_Gateway
 SG_ GE_Stoppverbot_Anz_04 : 59|1@1+ (1,0) [0|1] ""  Sub_Gateway
 SG_ GE_Stoppverbot_Anz_05 : 60|1@1+ (1,0) [0|1] ""  Sub_Gateway
 SG_ GE_Stoppverbot_Anz_06 : 61|1@1+ (1,0) [0|1] ""  Sub_Gateway
 SG_ GE_Stoppverbot_Anz_07 : 62|1@1+ (1,0) [0|1] ""  Sub_Gateway
 SG_ GE_Stoppverbot_Anz_Std : 63|1@1+ (1,0) [0|1] ""  Sub_Gateway

BO_ 1702 Wischer_01: 8 Gateway
 SG_ Wischer_vorne_aktiv : 0|1@1+ (1,0) [0|1] ""  TME
 SG_ Waschen_vorne_aktiv : 1|1@1+ (1,0) [0|1] ""  TME
 SG_ Wischer_vorne_Normal : 2|1@1+ (1,0) [0|1] "" Vector__XXX
 SG_ Wischer_vorne_Schnell : 3|1@1+ (1,0) [0|1] "" Vector__XXX
 SG_ Wischer_vorne_Parklage : 4|1@1+ (1,0) [0|1] "" Vector__XXX
 SG_ Wischer_vorne_defekt : 6|1@1+ (1,0) [0|1] "" Vector__XXX
 SG_ Wischer_vorne_blockiert : 7|1@1+ (1,0) [0|1] "" Vector__XXX
 SG_ Wischer1_Wischgeschwindigkeit : 8|6@1+ (1,9) [10|70] "Unit_MinutInver" Vector__XXX
 SG_ BCM1_SRA_aktiv : 14|1@1+ (1,0) [0|1] "" Vector__XXX
 SG_ Heckwischer_Anforderung : 16|1@1+ (1,0) [0|1] "" Vector__XXX
 SG_ WWSs_01_upd : 17|1@1+ (1,0) [0|1] "" Vector__XXX
 SG_ Wischer_Anzeigetext : 18|2@1+ (1,0) [0|3] "" Vector__XXX

BO_ 2617016064 XCP_AWC_CRO_01: 8 Vector__XXX
 SG_ XCP_AWC_CRO_01_Data : 0|64@1+ (1,0) [0|1] ""  AWC

BO_ 2617016065 XCP_AWC_DTO_01: 8 AWC
 SG_ XCP_AWC_DTO_01_Data : 0|64@1+ (1,0) [0|1] "" Vector__XXX

BO_ 2617079552 XCP_BattRegelung_CRO_01: 8 Vector__XXX
 SG_ XCP_BattRegelung_CRO_01_Data : 0|64@1+ (1,0) [0|1] ""  BMS_NV

BO_ 2617079553 XCP_BattRegelung_DTO_01: 8 BMS_NV
 SG_ XCP_BattRegelung_DTO_01_Data : 0|64@1+ (1,0) [0|1] "" Vector__XXX

BO_ 2617042689 XCP_BMS_MV_DTO_01: 8 Vector__XXX
 SG_ XCP_BMS_MV_DTO_01_Data : 0|64@1+ (1,0) [0|1] "" Vector__XXX

BO_ 2617118208 XCP_DCDC_CRO_01: 8 Vector__XXX
 SG_ XCP_DCDC_CRO_01_Data : 0|64@1+ (1,0) [0|1.84467440737096E+019] ""  DCDC_IHEV

BO_ 2617118209 XCP_DCDC_DTO_01: 8 DCDC_IHEV
 SG_ XCP_DCDC_DTO_01_Data : 0|64@1+ (1,0) [0|1.84467440737096E+019] "" Vector__XXX

BO_ 2617097984 XCP_DCDC_HV_CRO_01: 8 Vector__XXX
 SG_ XCP_DCDC_HV_CRO_01_Data : 0|64@1+ (1,0) [0|1.84467440737096E+019] ""  DCDC_800V_PAG,DCDC_HV

BO_ 2617097985 XCP_DCDC_HV_DTO_01: 8 DCDC_800V_PAG
 SG_ XCP_DCDC_HV_DTO_01_Data : 0|64@1+ (1,0) [0|1.84467440737096E+019] "" Vector__XXX

BO_ 2617093888 XCP_FCU_CRO_01: 8 Vector__XXX
 SG_ XCP_FCU_CRO_01_Data : 0|64@1+ (1,0) [0|1.84467440737096E+019] ""  FCU_MLBevo_FCEV

BO_ 2617093889 XCP_FCU_DTO_01: 8 FCU_MLBevo_FCEV
 SG_ XCP_FCU_DTO_01_Data : 0|64@1+ (1,0) [0|1.84467440737096E+019] "" Vector__XXX

BO_ 2617120256 XCP_TME_CRO_01: 8 Vector__XXX
 SG_ XCP_TME_CRO_01_Data : 0|64@1+ (1,0) [0|1] ""  TME

BO_ 2617120257 XCP_TME_DTO_01: 8 TME
 SG_ XCP_TME_DTO_01_Data : 0|64@1+ (1,0) [0|1] "" Vector__XXX

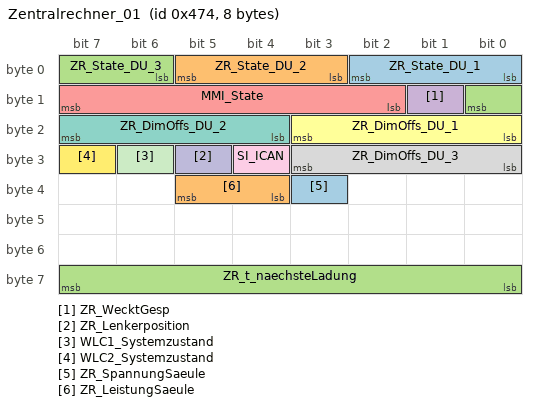
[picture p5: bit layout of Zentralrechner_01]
BO_ 1140 Zentralrechner_01: 8 Gateway
 SG_ ZR_State_DU_1 : 0|3@1+ (1,0) [0|7] "" Vector__XXX
 SG_ ZR_State_DU_2 : 3|3@1+ (1,0) [0|7] "" Vector__XXX
 SG_ ZR_State_DU_3 : 6|3@1+ (1,0) [0|7] "" Vector__XXX
 SG_ ZR_WecktGesp : 9|1@1+ (1,0) [0|1] "" Vector__XXX
 SG_ MMI_State : 10|6@1+ (1,0) [0|63] "" Vector__XXX
 SG_ ZR_DimOffs_DU_1 : 16|4@1+ (1,-5) [-5|5] "Unit_None" Vector__XXX
 SG_ ZR_DimOffs_DU_2 : 20|4@1+ (1,-5) [-5|5] "Unit_None" Vector__XXX
 SG_ ZR_DimOffs_DU_3 : 24|4@1+ (1,-5) [-5|5] "Unit_None" Vector__XXX
 SG_ SI_ICAN : 28|1@1+ (1,0) [0|1] "" Vector__XXX
 SG_ ZR_Lenkerposition : 29|1@1+ (1,0) [0|1] "" Vector__XXX
 SG_ WLC1_Systemzustand : 30|1@1+ (1,0) [0|1] "" Vector__XXX
 SG_ WLC2_Systemzustand : 31|1@1+ (1,0) [0|1] "" Vector__XXX
 SG_ ZR_SpannungSaeule : 35|1@1+ (1,0) [0|1] ""  TME
 SG_ ZR_LeistungSaeule : 36|2@1+ (1,0) [0|3] ""  TME
 SG_ ZR_t_naechsteLadung : 56|8@1+ (1,0) [0|255] "Unit_Minut"  TME

BO_ 388 ZV_01: 8 Gateway
 SG_ ZV_01_CRC : 0|8@1+ (1,0) [0|255] "" Vector__XXX
 SG_ ZV_01_BZ : 8|4@1+ (1,0) [0|15] "" Vector__XXX
 SG_ ZV_FT_verriegeln : 12|1@1+ (1,0) [0|1] ""  Ladegeraet_Konzern
 SG_ ZV_FT_entriegeln : 13|1@1+ (1,0) [0|1] ""  FCU_MLBevo_FCEV,Ladegeraet_Konzern
 SG_ ZV_BT_verriegeln : 14|1@1+ (1,0) [0|1] ""  Ladegeraet_Konzern
 SG_ ZV_BT_entriegeln : 15|1@1+ (1,0) [0|1] ""  Ladegeraet_Konzern
 SG_ ZV_HFS_verriegeln : 16|1@1+ (1,0) [0|1] "" Vector__XXX
 SG_ ZV_HFS_entriegeln : 17|1@1+ (1,0) [0|1] "" Vector__XXX
 SG_ ZV_HBFS_verriegeln : 18|1@1+ (1,0) [0|1] "" Vector__XXX
 SG_ ZV_HBFS_entriegeln : 19|1@1+ (1,0) [0|1] "" Vector__XXX
 SG_ ZV_zentral_safen : 20|1@1+ (1,0) [0|1] "" Vector__XXX
 SG_ ZV_zentral_entsafen : 21|1@1+ (1,0) [0|1] "" Vector__XXX
 SG_ ZV_Spg_Anklappen : 22|1@1+ (1,0) [0|1] "" Vector__XXX
 SG_ ZV_Softtouch_betaetigt : 23|1@1+ (1,0) [0|1] "" Vector__XXX
 SG_ ZV_LED_Steuerung : 24|1@1+ (1,0) [0|1] "" Vector__XXX
 SG_ ZV_LED_Uebernahme : 25|1@1+ (1,0) [0|1] "" Vector__XXX
 SG_ ZV_auf_FT : 26|1@1+ (1,0) [0|1] "" Vector__XXX
 SG_ ZV_zu_FT : 27|1@1+ (1,0) [0|1] "" Vector__XXX
 SG_ ZV_auf_BT : 28|1@1+ (1,0) [0|1] "" Vector__XXX
 SG_ ZV_zu_BT : 29|1@1+ (1,0) [0|1] "" Vector__XXX
 SG_ ZV_auf_Kessy : 30|1@1+ (1,0) [0|1] "" Vector__XXX
 SG_ ZV_zu_Kessy : 31|1@1+ (1,0) [0|1] "" Vector__XXX
 SG_ ZV_auf_Funk : 32|1@1+ (1,0) [0|1] "" Vector__XXX
 SG_ ZV_zu_Funk : 33|1@1+ (1,0) [0|1] "" Vector__XXX
 SG_ VIP_Sensor_betaetigt : 34|1@1+ (1,0) [0|1] "" Vector__XXX
 SG_ VIP_Freigabe : 35|1@1+ (1,0) [0|1] "" Vector__XXX
 SG_ ZV_zu_Zeitl_Nachverr : 36|1@1+ (1,0) [0|1] "" Vector__XXX
 SG_ ZV_HSK_entriegeln : 37|1@1+ (1,0) [0|1] "" Vector__XXX
 SG_ ZV_HSK_verriegeln : 38|1@1+ (1,0) [0|1] "" Vector__XXX
 SG_ ZV_Verdeck_zu : 39|1@1+ (1,0) [0|1] "" Vector__XXX
 SG_ ZV_Verdeck_auf : 40|1@1+ (1,0) [0|1] "" Vector__XXX
 SG_ FH_FT_hoch : 41|1@1+ (1,0) [0|1] "" Vector__XXX
 SG_ FH_FT_tief : 42|1@1+ (1,0) [0|1] "" Vector__XXX
 SG_ FH_BT_hoch : 43|1@1+ (1,0) [0|1] "" Vector__XXX
 SG_ FH_BT_tief : 44|1@1+ (1,0) [0|1] "" Vector__XXX
 SG_ FH_HFS_hoch : 45|1@1+ (1,0) [0|1] "" Vector__XXX
 SG_ FH_HFS_tief : 46|1@1+ (1,0) [0|1] "" Vector__XXX
 SG_ FH_HBFS_hoch : 47|1@1+ (1,0) [0|1] "" Vector__XXX
 SG_ FH_HBFS_tief : 48|1@1+ (1,0) [0|1] "" Vector__XXX
 SG_ BCM_Spg_Synchron : 49|1@1+ (1,0) [0|1] "" Vector__XXX
 SG_ BCM_BF_Spg_Absenkung : 50|1@1+ (1,0) [0|1] "" Vector__XXX
 SG_ ZV_Signatur : 51|11@1+ (1,0) [0|2047] "" Vector__XXX
 SG_ ZV_entriegeln_Anf : 62|1@1+ (1,0) [0|1] "" Vector__XXX
 SG_ ZV_auto_Ansteuerung : 63|1@1+ (1,0) [0|1] "" Vector__XXX

BO_ 1411 ZV_02: 8 Gateway
 SG_ BCM_FH_Freigabe : 12|1@1+ (1,0) [0|1] "" Vector__XXX
 SG_ BCM_Komfortfkt_Freigabe : 13|1@1+ (1,0) [0|1] "" Vector__XXX
 SG_ BCM_HSK_Freigabe : 14|1@1+ (1,0) [0|1] "" Vector__XXX
 SG_ BCM_Verdeck_Freigabe : 15|1@1+ (1,0) [0|1] "" Vector__XXX
 SG_ ZV_verriegelt_intern_ist : 16|1@1+ (1,0) [0|1] ""  Ladegeraet_Konzern
 SG_ ZV_verriegelt_extern_ist : 17|1@1+ (1,0) [0|1] ""  Ladegeraet_Konzern
 SG_ ZV_verriegelt_intern_soll : 18|1@1+ (1,0) [0|1] ""  Ladegeraet_Konzern
 SG_ ZV_verriegelt_extern_soll : 19|1@1+ (1,0) [0|1] ""  Ladegeraet_Konzern
 SG_ ZV_gesafet_extern_ist : 20|1@1+ (1,0) [0|1] "" Vector__XXX
 SG_ ZV_gesafet_extern_soll : 21|1@1+ (1,0) [0|1] "" Vector__XXX
 SG_ ZV_Einzeltuerentriegelung : 22|1@1+ (1,0) [0|1] "" Vector__XXX
 SG_ ZV_Heckeinzelentriegelung : 23|1@1+ (1,0) [0|1] "" Vector__XXX
 SG_ ZV_FT_offen : 24|1@1+ (1,0) [0|1] "" Vector__XXX
 SG_ ZV_BT_offen : 25|1@1+ (1,0) [0|1] "" Vector__XXX
 SG_ ZV_HFS_offen : 26|1@1+ (1,0) [0|1] "" Vector__XXX
 SG_ ZV_HBFS_offen : 27|1@1+ (1,0) [0|1] "" Vector__XXX
 SG_ ZV_HD_offen : 28|1@1+ (1,0) [0|1] "" Vector__XXX
 SG_ ZV_HS_offen : 29|1@1+ (1,0) [0|1] "" Vector__XXX
 SG_ IRUE_aktiv : 30|1@1+ (1,0) [0|1] "" Vector__XXX
 SG_ DWA_aktiv : 31|1@1+ (1,0) [0|1] "" Vector__XXX
 SG_ HD_Hauptraste : 32|1@1+ (1,0) [0|1] "" Vector__XXX
 SG_ HD_Vorraste : 33|1@1+ (1,0) [0|1] "" Vector__XXX
 SG_ FFB_CarFinder : 38|1@1+ (1,0) [0|1] "" Vector__XXX
 SG_ FFB_Komfortoeffnen : 39|1@1+ (1,0) [0|1] "" Vector__XXX
 SG_ FFB_Komfortschliessen : 40|1@1+ (1,0) [0|1] "" Vector__XXX
 SG_ ZV_Schluessel_Zugang : 42|4@1+ (1,0) [0|15] "" Vector__XXX
 SG_ ZV_SafeFunktion_aktiv : 46|1@1+ (1,0) [0|1] "" Vector__XXX
 SG_ FBS_Warn_Schluessel_Batt : 47|1@1+ (1,0) [0|1] "" Vector__XXX
 SG_ ZV_Oeffnungsmodus : 48|2@1+ (1,0) [0|3] "" Vector__XXX
 SG_ HFS_verriegelt : 50|1@1+ (1,0) [0|1] "" Vector__XXX
 SG_ HFS_gesafet : 51|1@1+ (1,0) [0|1] "" Vector__XXX
 SG_ HBFS_verriegelt : 52|1@1+ (1,0) [0|1] "" Vector__XXX
 SG_ HBFS_gesafet : 53|1@1+ (1,0) [0|1] "" Vector__XXX
 SG_ ZV_ist_Zustand_verfuegbar : 54|1@1+ (1,0) [0|1] "" Vector__XXX
 SG_ IRUE_Taster_Fkts_LED : 55|1@1+ (1,0) [0|1] "" Vector__XXX
 SG_ ZV_Tankklappe_offen : 56|1@1+ (1,0) [0|1] "" Vector__XXX
 SG_ ZV_Rollo_auf : 57|1@1+ (1,0) [0|1] "" Vector__XXX
 SG_ ZV_Rollo_zu : 58|1@1+ (1,0) [0|1] "" Vector__XXX
 SG_ ZV_SAD_auf : 59|1@1+ (1,0) [0|1] "" Vector__XXX
 SG_ ZV_SAD_zu : 60|1@1+ (1,0) [0|1] "" Vector__XXX
 SG_ BCM_Tankklappensteller_Fehler : 61|1@1+ (1,0) [0|1] "" Vector__XXX
 SG_ ZV_verriegelt_soll : 62|2@1+ (1,0) [0|3] "" Vector__XXX

BO_TX_BU_ 977 : Gateway,Gateway_PAG;
BO_TX_BU_ 976 : Gateway,Gateway_PAG;
BO_TX_BU_ 975 : Gateway,Gateway_PAG;
BO_TX_BU_ 974 : Gateway,Gateway_PAG;
BO_TX_BU_ 1716 : Gateway,Gateway_PAG;
BO_TX_BU_ 916 : Gateway,Gateway_PAG;
BO_TX_BU_ 1702 : Gateway,Gateway_PAG;
BO_TX_BU_ 2617097985 : DCDC_800V_PAG,DCDC_HV;
BO_TX_BU_ 1140 : Gateway,Gateway_PAG;
BO_TX_BU_ 388 : Gateway,Gateway_PAG;
BO_TX_BU_ 1411 : Gateway,Gateway_PAG;
CM_ SG_ 1399 TME_Leistung_Komfort_HV_stat "HV-Leistungsaufnahme Thermomanagement im stationären Fall für die Innenraumklimatisierung";
CM_ SG_ 1399 TME_Leistung_Thermo_HV_stat "HV-Leistungsaufnahme Thermomanagement im stationären Fall für das Kühlen/Heizen von Bauteilen";
CM_ SG_ 1399 TME_Energie_Komfort_NV "Energieverbrauch/-bedarf der 12V-Komponenten für die Innenraumklimatisierung ";
CM_ SG_ 1399 TME_Energie_Thermo_NV "Energieverbrauch/-bedarf der 12V-Komponenten für das Kühlen/Heizen von der Batterie";
CM_ SG_ 1399 TME_Leistung_Komfort_NV_stat "12V-Leistungsaufnahme Thermomanagement im stationären Fall für die Innenraumklimatisierung";
CM_ SG_ 1399 TME_Leistung_Thermo_NV_stat "12V-Leistungsaufnahme Thermomanagement im stationären Fall für das Kühlen/Heizen von Bauteilen";
CM_ SG_ 1375 TME_VoKo_Strategie_Anzeige "rueckgemeldete VoKo-Strategie fuer Anzeige
";
CM_ SG_ 1375 TME_Zuheizer_Freigabe "Freigabe-Signal für Verbrennungszuheizfunktion";
CM_ SG_ 1375 TME_AC_LED "Steuerung der LED in der AC-Taste des KBTs";
CM_ SG_ 1375 TME_Heizstrategie "Info über aktuelle Heizstrategie an KBT";
CM_ SG_ 1375 TME_Systemstatus "Systemstatus der TME";
CM_ SG_ 1375 TME_Kbr_Innenraum "Vorhandensein der Klimabereitschaft für Innenraum";
CM_ SG_ 1375 TME_Freigabe_Vorkond "Freigabe an das KBT, mit dem Innenraumkonditionieren zu beginnen.";
CM_ SG_ 1375 TME_Verdampfer_Status "Verdampfer wird vom Kältemittel durchströmt";
CM_ SG_ 1375 TME_Kuehlmittel_Sensor "Signal der Sensorelektroden für die Kühlmittelreserve aktuell, entstört, bewertet (OK/Mangel)
Signalaenderung BEV: Zusaetzlich zum Kuehlmittelsensor werden Fehler an Wasserpumpe des Kuehlsystems auf das Fehlerbit gemappt.";
CM_ SG_ 1375 TME_AC_Rueckmeldung "Status des Elektrischen Klimakompressors";
CM_ SG_ 1375 TME_Heizungspumpen_Anst "Anforderung Heizungspumpenansteuerung";
CM_ SG_ 1375 TME_Frischluftklappe_Soll "Sollvorgabe der Frischluftklappenstellung bei speziellem Heizbetrieb, z.B. Wärmepumpe";
CM_ SG_ 1375 TME_Freigabe_Luft_PTC "Freigabe des Zuheizers im Klimagerät";
CM_ SG_ 1375 TME_Umluftklappe_Soll "Sollvorgabe der Umluftklappenstellung bei speziellem Heizbetrieb, z.B. Wärmepumpe";
CM_ SG_ 1375 TME_Waermepumpe_aktiv "Aktivierungszustand der Wärmepumpe für Innenraumheizen";
CM_ SG_ 1375 TME_Nachlaufzeit_Heizp "Nachlaufzeit für Heizungspumpe";
CM_ SG_ 1375 TME_Absperrventil1_oeffnen "Signal an Standheizungs-SG das Absperrrventil anzusteuern";
CM_ SG_ 1375 TME_Klima_Defizit "Für Innennraumklimatisierung aktuell nicht verfügbare  Leistung (Defizit = Istleistung - Solleistung)";
CM_ SG_ 1375 TME_Temp_KM_vor_HWT "Kühlmitteltemperatur vor HWT";
CM_ SG_ 1373 TME_Geblaese "Aktivierung des Klimagebläses für Innenraumkonditionierung";
CM_ SG_ 1373 TME_Kond_Innen_Betrieb "Funktionsrückmeldung über Betriebsstatus (an/aus) als Anzeige bzw  Kundenrückmeldung.";
CM_ SG_ 1373 TME_Klimadefizit "Erkanntes Leistungsdefizit für die Klimatisierung";
CM_ SG_ 1373 TME_STH_Status "Verfügbarkeitsinformation über den Standheizungsbetrieb.
Information für MMI-Lade-Menü-bedienbarkeit";
CM_ SG_ 1373 TME_Kond_Innen_Betriebsdauer "Signal beeinhaltet die Zeitdauer welche vom TME_Steuergerät für die entsprechende Konditionierungsmaßnahme des Innenraumes errechnet wurde.
Die Dauer dient zur Aktivierung der entsrpechenden Komponenten und zur Anzeige im HMI.";
CM_ SG_ 1373 TME_Kond_Innen_Status "Innenraumkonditionierung ist möglich/n.möglich (wegen Komponentendefekt bzw-einschränkung)
Information wird zwecks Einschränkung/Freigabe der  Menübedienbarkeit im MMI benötigt.";
CM_ SG_ 1373 TME_STH_Ansteuerung "Einschaltbefehl an die Standheizung seitens TME/Wärmepumpensteuergerät ";
CM_ SG_ 1373 TME_Verdampfertemperatur "Istwert der Verdampfertemperatur  (Verdampfer hängt am TME C7PHEV)";
CM_ SG_ 1373 TME_Temp_KM_vor_LE "Kuehlmittelvorlauftemperatur vor der Leistungselektronik";
CM_ SG_ 1373 TME_Kuehlmittel_Temp_Pumpe1_tNT "Kühlwassertemperatur nach Batteriekreispumpe";
CM_ SG_ 1373 TME_STH_aktiv "Funktionsrückmeldung für Standheizung aktiv";
CM_ SG_ 1373 TME_SKE_Status_2 "Statusinformation über den Zustand der Kühlerjalousie 2";
CM_ SG_ 1373 TME_STL_aktiv "Funktionsrückmeldung Standlüftung aktiv ";
CM_ SG_ 1373 TME_Thermomanagement "Stufen des Thermomanagement";
CM_ SG_ 1373 TME_IstSpannung_EKK_HV "Vom EKV gemessene HV-Spannung";
CM_ SG_ 1657 TME_Temp_KM_nach_EM "Momentanwert Kuehlmitteltemperatur nach E-Maschine";
CM_ SG_ 1657 TME_EKK_ProtectionMode "Bei akuter Ueberhitzungsgefahr des elektrischen Klimakompressors wird der ProtectionMode aktiviert.";
CM_ SG_ 1657 TME_Klimaanforderung "Anforderungsgrund der Klimaapplikation durch die TME";
CM_ SG_ 1657 TME_SKE_Pos_Summe "Aerodynamisch wirksamer Gesamtöffnungswinkel der am TME angeschlossenen Kühlerjalousiesteller.";
CM_ SG_ 1657 TME_Waermebilanz_Status "Diagnosestatus zur Wärmebilanz. OBDI berücksichtigt die elektrischen Diagnosen. OBDII berücksichtigt die funktionalen Diagnosen bzw. Sensorwertplausibilisierung.";
CM_ SG_ 1657 TME_Waermebilanz "TME bilanziert die Wärmeentnahme aus VKM";
CM_ SG_ 1657 TME_Klimaleistung "Leistung des elektrischen Klimakompressors";
CM_ SG_ 1657 TME_SKE_PosResp "Rückmeldung SKE Position erreicht";
CM_ SG_ 1657 TME_SKE_Position_1 "Position der SKE 1

0 => Geöffnet
1 => Teilgeschlossen
2 => Geschlossen
3 => Init / Anforderung Initialisierung / Anforderung Referenzierung / Fehler heilen";
CM_ SG_ 1657 TME_Systemtemp "Systemtemperatur Antriebe für Kombi";
CM_ SG_ 1657 TME_Eingriff_SKE_Oeffnung "TME Anforderung zur Öffnung der SKE";
CM_ SG_ 1657 TME_SKE_Status "Status Information über den Zustand der SKE";
CM_ SG_ 1657 TME_Status_Kuehlmittel_Tmp_CrChk "Status des Cross Checks der Kuehlmitteltemperaturen von TME und MSG";
CM_ SG_ 1657 TME_Temperatur_Ruecklauf_VKM "Kühlmitteltemperatur Rücklauf VKM";
CM_ SG_ 2463978655 TME_Senkenleistung_verfuegbar "aktuell verfuegbare Senkenleistung des TME_SG";
CM_ SG_ 2589283463 TME_THMTVLV_Sollstellung "Angeforderte Sollstellung des Mischventils der FCU";
CM_ SG_ 2589283463 TME_Mischventil_Heizkreis_Ist "Aktuelle Ventilstellung des MVW1";
CM_ SG_ 2589283463 TME_Ionenspuelung_aktiv "Signalisiert den aktiven bzw. inaktiven Status der Ionenspülfunktion";
CM_ SG_ 2589283463 TME_Temp_KM_v_Pumpe_Heizkreis "Temperatur des Kühlmediums vor der Heizkreispumpe P5";
CM_ SG_ 2589283463 TME_Temp_KM_n_Mischventil_Heizkr "Temperatur des Kühlmediums nach MVW1 bei Verbindung von Heizkreis und HT-Kreis";
CM_ SG_ 2589283463 TME_Befuellung_aktiv "Signalisiert den aktiven bzw. inaktiven Status der Befüllroutine";
CM_ SG_ 2589283463 TME_Entlueftung_aktiv "Signalisiert den aktiven bzw. inaktiven Status der Entlüftungsroutine";
CM_ SG_ 2589283463 TME_KMP_Solldrehzahl "Angeforderte Solldrehzahl der Kühlmittelpumpe der FCU";
CM_ SG_ 2589283408 SKE1_AOCCT_timer1_count "Berechnung ActiveOffCycleCreditTechnology: Timer 1 für SKE1 Position <75%";
CM_ SG_ 2589283408 SKE1_AOCCT_timer2_count "Berechnung ActiveOffCycleCreditTechnology: Timer 2 für SKE2 Position >=75%";
CM_ SG_ 2589283408 SKE1_AOCCT_teststatus "Berechnung ActiveOffCycleCreditTechnology: SKE1 Diagnose durchgeführt";
CM_ SG_ 2589283408 SKE2_AOCCT_timer1_verbaut "Berechnung ActiveOffCycleCreditTechnology: Timer 1 für SKE2 verbaut und codiert";
CM_ SG_ 2589283408 SKE2_AOCCT_timer1_count "Berechnung ActiveOffCycleCreditTechnology: Timer 1 für SKE2 Position <75%";
CM_ SG_ 2589283408 SKE2_AOCCT_timer2_verbaut "Berechnung ActiveOffCycleCreditTechnology: Timer 2 für SKE2 verbaut und codiert";
CM_ SG_ 2589283408 SKE2_AOCCT_timer2_count "Berechnung ActiveOffCycleCreditTechnology: Timer 2 für SKE2 >=75%";
CM_ SG_ 2589283408 SKE2_AOCCT_fehlerstatus "Berechnung ActiveOffCycleCreditTechnology: SKE2 Fehler";
CM_ SG_ 2589283408 SKE2_AOCCT_teststatus "Berechnung ActiveOffCycleCreditTechnology: SKE2 Diagnose gelaufen";
CM_ SG_ 2589283408 SKE1_AOCCT_timer1_verbaut "Berechnung ActiveOffCycleCreditTechnology: Timer 1 für SKE1 verbaut und codiert";
CM_ SG_ 2589283408 SKE1_AOCCT_fehlerstatus "Berechnung ActiveOffCycleCreditTechnology: SKE1 Fehler";
CM_ SG_ 2589283408 SKE1_AOCCT_timer2_verbaut "Berechnung ActiveOffCycleCreditTechnology: Timer 2 für SKE1 verbaut und codiert";
CM_ SG_ 2527679716 TME_ThermoPred_P_dyn_BTL_FP1 "Prädizierte Leistung der dynamischen Phase der Bauteilkonditionierung im Fahrprogramm 1";
CM_ SG_ 2527679716 TME_Pred_BTLSys_Anf_FP1 "Systemtrigger, dimensionslose Größe, wird hochgezählt sobald das Fahrprogramm 1 gewählt wird um im GW die Restreichweitenberechnung zu triggern";
CM_ SG_ 2527679716 TME_Pred_KlimaSys_Anf_FP1 "Systemtrigger, dimensionslose Größe, wird hochgezählt sobald das Fahrprogramm 1 gewählt wird um im GW die Restreichweitenberechnung zu triggern";
CM_ SG_ 2527679716 TME_Pred_KlimaKunde_Anf_FP1 "Systemtrigger, dimensionslose Größe, wird hochgezählt sobald das Fahrprogramm 1 gewählt wird um im GW die Restreichweitenberechnung zu triggern";
CM_ SG_ 2527679716 TME_ThermoPred_P_stat_Klima_FP1 "Prädizierte Leistung der statischen Phase der Innenraumklimatisierung im Fahrprogramm 1";
CM_ SG_ 2527679716 TME_ThermoPred_P_dyn_Klima_FP1 "Prädizierte Leistung der dynamischen Phase der Innenraumklimatisierung im Fahrprogramm 1";
CM_ SG_ 2527679716 TME_ThermoPred_T_dyn_BTL_FP1 "Prädizierte Zeit der dynamischen Phase der Bauteilkonditionierung im Fahrprogramm 1";
CM_ SG_ 2527679716 TME_ThermoPred_T_dyn_Klima_FP1 "Prädizierte Zeit der dynamischen Phase der Innenraumklimatisierung im Fahrprogramm 1";
CM_ SG_ 2527679717 TME_ThermoPred_P_dyn_BTL_FP2 "Prädizierte Leistung der dynamischen Phase der Bauteilkonditionierung im Fahrprogramm 2";
CM_ SG_ 2527679717 TME_Pred_BTLSys_Anf_FP2 "Systemtrigger, dimensionslose Größe, wird hochgezählt sobald das Fahrprogramm 2 gewählt wird um im GW die Restreichweitenberechnung zu triggern";
CM_ SG_ 2527679717 TME_Pred_KlimaSys_Anf_FP2 "Systemtrigger, dimensionslose Größe, wird hochgezählt sobald das Fahrprogramm 2 gewählt wird um im GW die Restreichweitenberechnung zu triggern";
CM_ SG_ 2527679717 TME_Pred_KlimaKunde_Anf_FP2 "Systemtrigger, dimensionslose Größe, wird hochgezählt sobald das Fahrprogramm 2 gewählt wird um im GW die Restreichweitenberechnung zu triggern";
CM_ SG_ 2527679717 TME_ThermoPred_P_stat_Klima_FP2 "Prädizierte Leistung der statischen Phase der Innenraumklimatisierung im Fahrprogramm 2";
CM_ SG_ 2527679717 TME_ThermoPred_P_dyn_Klima_FP2 "Prädizierte Leistung der dynamischen Phase der Innenraumklimatisierung im Fahrprogramm 2";
CM_ SG_ 2527679717 TME_ThermoPred_T_dyn_BTL_FP2 "Prädizierte Zeit der dynamischen Phase der Bauteilkonditionierung im Fahrprogramm 2";
CM_ SG_ 2527679717 TME_ThermoPred_T_dyn_Klima_FP2 "Prädizierte Zeit der dynamischen Phase der Innenraumklimatisierung im Fahrprogramm 2";
CM_ SG_ 2527679718 TME_ThermoPred_P_dyn_BTL_FP3 "Prädizierte Leistung der dynamischen Phase der Bauteilkonditionierung im Fahrprogramm 3";
CM_ SG_ 2527679718 TME_Pred_BTLSys_Anf_FP3 "Systemtrigger, dimensionslose Größe, wird hochgezählt sobald das Fahrprogramm 3 gewählt wird um im GW die Restreichweitenberechnung zu triggern";
CM_ SG_ 2527679718 TME_Pred_KlimaSys_Anf_FP3 "Systemtrigger, dimensionslose Größe, wird hochgezählt sobald das Fahrprogramm 3 gewählt wird um im GW die Restreichweitenberechnung zu triggern";
CM_ SG_ 2527679718 TME_Pred_KlimaKunde_Anf_FP3 "Systemtrigger, dimensionslose Größe, wird hochgezählt sobald das Fahrprogramm 3 gewählt wird um im GW die Restreichweitenberechnung zu triggern";
CM_ SG_ 2527679718 TME_ThermoPred_P_stat_Klima_FP3 "Prädizierte Leistung der statischen Phase der Innenraumklimatisierung im Fahrprogramm 3";
CM_ SG_ 2527679718 TME_ThermoPred_P_dyn_Klima_FP3 "Prädizierte Leistung der dynamischen Phase der Innenraumklimatisierung im Fahrprogramm 3";
CM_ SG_ 2527679718 TME_ThermoPred_T_dyn_BTL_FP3 "Prädizierte Zeit der dynamischen Phase der Bauteilkonditionierung im Fahrprogramm 3";
CM_ SG_ 2527679718 TME_ThermoPred_T_dyn_Klima_FP3 "Prädizierte Zeit der dynamischen Phase der Innenraumklimatisierung im Fahrprogramm 3";
CM_ SG_ 2463978733 TME_ThermoPred_BTL_System_Anf "Systemtrigger, dimensionslose Größe, wird hochgezählt sobald einen Systemanforderung einen Neuberechnung der Restreichweite im Gateway Triggern muss";
CM_ SG_ 2463978733 TME_ThermoPred_P_dyn_Btl "Prädizierte Leistung der dynamischen Phase für Bauteilkonditionierung";
CM_ SG_ 2463978733 TME_ThermoPred_T_dyn_Btl "Prädizierte Zeit der dynamischen Phase für Bauteilkonditionierung";
CM_ BO_ 977 "ab MQB 7.05";
CM_ SG_ 977 BT_Tuer_geoeffnet "
";
CM_ SG_ 977 BT_gesafet "Im Zustand Safe wird auch das Signal BT_verriegelt = 1 gesendet";
CM_ SG_ 977 BT_Sperrklinke "Vorraste für Schloß

zwischen Vor- und Hauptraste Signal kurz auf 1, danach wieder auf 0 wenn Tür in Hauptraste (Tür ist sicher zu wenn Sperrklinke und Türkontakt auf 0 sind)";
CM_ SG_ 977 BT_TAG_betaetigt "Türaussengriff";
CM_ SG_ 977 BT_TIG_betaetigt "Türinnengriff";
CM_ SG_ 977 BT_EC_Spiegel_Helligkeit "Dimmung für den Aussenspiegel in %";
CM_ SG_ 977 BT_Sp_Heizung_Anf "Kundenanforderung der Außenspiegelheizung Beifahrertür";
CM_ SG_ 977 BT_Tuer_Status "Türstatus mit Fehler und Initwert";
CM_ SG_ 977 BT_FH_S_ManHoch "Fehlende Beschreibung (Import)";
CM_ SG_ 977 BT_FH_S_AutoHoch "Fehlende Beschreibung (Import)";
CM_ SG_ 977 BT_FH_S_ManTief "Fehlende Beschreibung (Import)";
CM_ SG_ 977 BT_FH_S_AutoTief "Fehlende Beschreibung (Import)";
CM_ SG_ 977 BT_FH_Oeffnung "Gibt den Fensteröffnungswert in % an.";
CM_ SG_ 977 BT_FH_Bew_hoch "Fehlende Beschreibung (Import)";
CM_ SG_ 977 BT_FH_Bew_tief "Fehlende Beschreibung (Import)";
CM_ SG_ 977 BT_FH_Fang "Fangbereich ist 4mm von oberer Lippendichtung";
CM_ SG_ 977 BT_FH_Block "Fensterscheibe befindet sich im mechanischen Block (oben oder unten)";
CM_ SG_ 977 BT_FH_Thermo "gibt an ob Fensterheber im Thermoschutz ist";
CM_ SG_ 977 BT_UEKB_aktiviert "Überschutzbegrenzungskraft bei Reversieren";
CM_ SG_ 977 BT_Kisi_Fehler "Fehlerstatus Kindersicherungsfunktion";
CM_ SG_ 977 BT_SP_lr_aktiv "Fehlende Beschreibung (Import)";
CM_ SG_ 977 BT_SP_ht_aktiv "Fehlende Beschreibung (Import)";
CM_ SG_ 977 BT_Unten_Block_erw "Fehlende Beschreibung (Import)";
CM_ SG_ 977 BT_Tuer_Status_QBit "Dieses Bit gibt die Zuverlässigkeit des Türkontakts an.";
CM_ SG_ 977 BFS_Status_eTAG "Status des elektrischen Tueraussengriffes Beifahrertuer";
CM_ SG_ 977 BT_TCR_Mode_aktiv "Signal zeigt eine aktive mechanische Redundanz am Türschloss an.";
CM_ SG_ 977 BT_SP_Heizung_Status "Status der Spiegelheizung";
CM_ SG_ 977 ASW_Warnung_aktiv_BFS "Abschaltung der Ambientefunktion Beifahrertür bei aktiver ASW Warnung an der Fahrertür";
CM_ SG_ 977 BT_Tuerschloss_defekt "Das Beifahrertürschloss ist nicht mehr funktionsfähig.";
CM_ SG_ 977 BT_Tueroeffnen_Warnung "Bit wird gesetzt, wenn Tür während der Fahrt geoeffnet werden soll.";
CM_ SG_ 977 BT_Lock_Taster_inv "Lock Taster nicht betätigt";
CM_ SG_ 977 BT_Schluesselschalter_zu_inv "Schluesselschalter zu nicht betaetigt";
CM_ SG_ 977 BT_SWA_HMI_defekt "Zeigt an, ob die SWA-Anzeige defekt ist.";
CM_ SG_ 977 BT_ASW_HMI_defekt "Zeigt an, ob die ASW-Anzeige defekt ist.";
CM_ BO_ 976 "ab MQB 7.05";
CM_ SG_ 976 FT_Tuer_geoeffnet "Fehlende Beschreibung (Import)";
CM_ SG_ 976 FT_gesafet "Im Zustand Safe wird auch das Signal FT_verriegelt = 1 gesendet";
CM_ SG_ 976 FT_Sperrklinke "Vorraste für Schloß

zwischen Vor- und Hauptraste Signal kurz auf 1, danach wieder auf 0 wenn Tür in Hauptraste (Tür ist sicher zu wenn Sperrklinke und Türkontakt auf 0 sind)";
CM_ SG_ 976 FT_TAG_betaetigt "Türaussengriff

wird nicht im MLB-B8 verwendet";
CM_ SG_ 976 FT_TIG_betaetigt "Türinnengriff

wird nicht im MLB-B8 verwendet";
CM_ SG_ 976 FT_IRUE_Taste "Betätigung IRUE-Taster (Innenraumüberwachung)
MQB: Bei Verbau eines einzelnen Taster zur Deaktivierung von IRUE und NGS wird dieses Signal als Deaktivierungsanforderung beider DWA-Alarmquellen gesendet.";
CM_ SG_ 976 FT_TD_Taste_Fehler "Fehlerstatus des Tankdeckelentriegelungstasters. Wird bei Drucktankkonzepten vom MSG zusammen mit dem Signal FT_TD_Taste ausgewertet, um Tankbereitschaft herzustellen.
Der Fehler beschreibt einen hängenden TD_Taster. Ein Kurzschluss oder Leitungsunterbre";
CM_ SG_ 976 SSR_Temp_Freigabe "Freigabe des Seitenscheibenrollos. Bit wird  für die Deaktivierung des SSR bei Innenraumtemperaturen kleiner -10 Grad verwendet.";
CM_ SG_ 976 FT_Sp_Heizung_Anf "Kundenanforderung der Außenspiegelheizung Fahrertür";
CM_ SG_ 976 FT_HD_Taste_2 "2. HD-Taste im Bedienfeld 
Funktion: Heckdeckel schließen";
CM_ SG_ 976 FT_FH_S_ManHoch "Fehlende Beschreibung (Import)";
CM_ SG_ 976 FT_FH_S_AutoHoch "Fehlende Beschreibung (Import)";
CM_ SG_ 976 FT_FH_S_ManTief "Fehlende Beschreibung (Import)";
CM_ SG_ 976 FT_FH_S_AutoTief "Fehlende Beschreibung (Import)";
CM_ SG_ 976 FT_FH_Oeffnung "Gibt den Fensteröffnungswert in % an.";
CM_ SG_ 976 FT_FH_Bew_hoch "Fehlende Beschreibung (Import)";
CM_ SG_ 976 FT_FH_Bew_tief "Fehlende Beschreibung (Import)";
CM_ SG_ 976 FT_FH_Fang "Fangbereich ist 4mm von oberer Lippendichtung";
CM_ SG_ 976 FT_FH_Block "Fensterscheibe befindet sich im mechanischen Block (oben oder unten)";
CM_ SG_ 976 FT_FH_Thermo "gibt an ob Fensterheber im Thermoschutz ist";
CM_ SG_ 976 FT_UEKB_aktiviert "Überschutzbegrenzungskraft bei Reversieren";
CM_ SG_ 976 ASW_HMI_defekt "HMI Status der Funktion AusstiegsWarnung (ASW). HMI wird durch das TSG angesteuert.";
CM_ SG_ 976 FT_Schliesstaster "Vorhalt";
CM_ SG_ 976 FT_Zuziehhilfe_aktiv "Fehlende Beschreibung (Import)";
CM_ SG_ 976 FT_SP_lr_aktiv "Fehlende Beschreibung (Import)";
CM_ SG_ 976 FT_SP_ht_aktiv "Fehlende Beschreibung (Import)";
CM_ SG_ 976 ASW_wakeup "Trigger Start Nachlaufzeit t_1 für die Funktion Ausstieswarnung (ASW)";
CM_ SG_ 976 FT_Kisi_li_aktiv "Aktivierungsstatus der Kindersicherung links";
CM_ SG_ 976 FT_Kisi_re_aktiv "Aktivierungsstatus der Kindersicherung rechts";
CM_ SG_ 976 FT_Kisi_Taster_li "Linker Kisi Taster betaetigt";
CM_ SG_ 976 FT_Kisi_Taster_re "Rechter Kisi Taster betaetigt";
CM_ SG_ 976 FT_Kisi_Fehler "Fehlerstatus Kindersicherungsfunktion";
CM_ SG_ 976 FT_Daemmglas "Fehlende Beschreibung (Import)";
CM_ SG_ 976 FT_SP_Heizung_Status "Status der Spiegelheizung";
CM_ SG_ 976 ASW_Warnung_aktiv_FS "Abschaltung der Ambientefunktion Fahrertür bei aktiver ASW Warnung an der Fahrertür";
CM_ SG_ 976 FT_Tuerschloss_defekt "Das Fahrertürschloss ist nicht mehr funktionsfähig.";
CM_ SG_ 976 FT_SWA_Taster "SWA/ASW Taster Fahrertür";
CM_ SG_ 976 SWA_HMI_Diagnose "SWA HMI Diagnose beim TSG";
CM_ SG_ 976 FS_Status_eTAG "Status des elektrischen Tueraussengriffes Fahrertuer";
CM_ SG_ 975 HBFS_Tuer_geoeffnet "HBFS Tuer geoeffnet";
CM_ SG_ 975 HBFS_verriegelt "Verriegelungsstatus Tür";
CM_ SG_ 975 HBFS_gesafet "HBFS Tuer gesafet.
Im Zustand Safe wird auch das Signal HBFS_verriegelt = 1 gesendet.";
CM_ SG_ 975 HBFS_Heckrollotaster_betaetigt "Verfahren des Heckrollos in Richtung Hoch

Bei Einfachtaster wird Bit als Togglebit verwendet (Heckrollo hoch, tief)";
CM_ SG_ 975 HBFS_Tuerschloss_defekt "Das hintere Tuerschloss auf der Beifahrerseite ist nicht mehr funktionsfähig.";
CM_ SG_ 975 HBFS_Unlock_Taster "Betaetigung Unlock Taster";
CM_ SG_ 975 HBFS_Lock_Taster "Betaetigung Lock-Taster";
CM_ SG_ 975 HBFS_Sperrklinke "Vorraste für Schloß

zwischen Vor- und Hauptraste Signal kurz auf 1, danach wieder auf 0 wenn Tür in Hauptraste (Tür ist sicher zu wenn Sperrklinke und Türkontakt auf 0 sind)";
CM_ SG_ 975 HBFS_TAG_betaetigt "Betaetigung Türaussengriff";
CM_ SG_ 975 HBFS_TIG_betaetigt "Betaetigung Tuerinnengriff";
CM_ SG_ 975 HBFS_FH_S_HFS_AutoHoch "Automatisches Hochfahren der Seitenscheibe HFS";
CM_ SG_ 975 HBFS_FH_S_HFS_AutoTief "Automatisches Absenken der Seitenscheibe HFS";
CM_ SG_ 975 HBFS_FH_S_HFS_ManHoch "Manuelles Hochfahren der Seitenscheibe HFS";
CM_ SG_ 975 HBFS_FH_S_HFS_ManTief "Manuelles Absenken der Seitenscheibe HFS";
CM_ SG_ 975 HBFS_Tuer_Status "Türstatus mit Fehler und Initwert";
CM_ SG_ 975 HBFS_SAD_Schalter "  |   Ausstelldach MD3
-----------------------------
0 | nicht_betaetigt
1 |
2 |
3 |
4 |
5 | (m) Auf
6 | (a) Auf
7 | (m) Zu
8 | (a) Zu
13| Schalter nicht verfuegbar
14| Init
15| Fehlerfall";
CM_ SG_ 975 HBFS_FH_S_ManHoch "Betaetigung FH Schalter man hoch ";
CM_ SG_ 975 HBFS_FH_S_AutoHoch "Betaetigung FH Schalter auto tief ";
CM_ SG_ 975 HBFS_FH_S_ManTief "Betaetigung FH Schalter man tief";
CM_ SG_ 975 HBFS_FH_S_AutoTief "Betaetigung FH Schalter auto hoch";
CM_ SG_ 975 HBFS_FH_Oeffnung "Gibt den Fensteröffnungswert in % an.";
CM_ SG_ 975 HBFS_FH_Bew_hoch "HBFS Fenster bewegt sich in Richtung hoch";
CM_ SG_ 975 HBFS_FH_Bew_tief "HFS Fenster bewegt sich in Richtung tief";
CM_ SG_ 975 HBFS_FH_Fang "Fangbereich ist 4mm von oberer Lippendichtung";
CM_ SG_ 975 HBFS_FH_Block "Fensterscheibe befindet sich im mechanischen Block (oben oder unten)";
CM_ SG_ 975 HBFS_FH_Thermo "gibt an ob Fensterheber im Thermoschutz ist";
CM_ SG_ 975 HBFS_UEKB_aktiviert "Überschutzbegrenzungskraft bei Reversieren";
CM_ SG_ 975 HBFS_Tueroeffnen_Warnung "Bit wird gesetzt, wenn Tür während der Fahrt geoeffnet werden soll.";
CM_ SG_ 975 ASW_Warnung_aktiv_HBFS "Abschaltung der Ambientefunktion Tür hinten der Beifahrerseite bei aktiver ASW Warnung an der Fahrertür";
CM_ SG_ 975 HBFS_Zuziehhilfe_aktiv "Fehlende Beschreibung (Import)";
CM_ SG_ 975 HBFS_Status_KiSi "Status Kindersicherung HBFS
";
CM_ SG_ 975 SSR_HBFS_Pos_Unten "Signal für die 'Global Close'. Über dieses Bit wissen die anderen TSGs, ob der SSR oder der FH verfahren werden darf.";
CM_ SG_ 975 HBFS_Oben_Block_erw "Fensterheber in Blockerwartung oben";
CM_ SG_ 975 HBFS_Unten_Block_erw "Fensterheber in Blockerwartung unten";
CM_ SG_ 975 MTHBFS_M_Taste "Betätigung M-Taste HBFS";
CM_ SG_ 975 MTHBFS_Pos1 "Betätigung Postionstaste 1 HBFS";
CM_ SG_ 975 MTHBFS_Pos2 "Betätigung Postionstaste 2 HBFS
";
CM_ SG_ 975 MTHBFS_Pos3 "Betätigung Postionstaste 3 HBFS";
CM_ SG_ 975 HBFS_MRollo_Schalter "  | MRollo2
-----------------------------
0 | nicht_betaetigt
1 | (m) Zu
2 | (a) Zu
3 | (m) Auf
4 | (a) Auf
5 | Schalter nicht verfuegbar
6 | Init
7 | Fehlerfall";
CM_ SG_ 975 HBFS_Lock_Taster_inv "Lock Taster nicht betätigt";
CM_ SG_ 975 HBFS_Status_KiSi_inv "Inverser Status der elektrischen Kindersicherung Beifahrerseite hinten";
CM_ SG_ 975 HBFS_Status_eTAG "Status des elektrischen Tueraussengriffes Tuer Beifahrerseite hinten";
CM_ SG_ 975 HBFS_Tuer_Status_QBit "Dieses Bit gibt die Zuverlässigkeit des Türkontakts an.";
CM_ SG_ 975 HBFS_TIG_betaetigt_schliessen "Türinnenbetätigung, Taster Tür schließen.";
CM_ SG_ 974 HFS_Tuer_geoeffnet "HFS Tuer geoeffnet";
CM_ SG_ 974 HFS_verriegelt "HFS Tuer verriegelt";
CM_ SG_ 974 HFS_gesafet "HFS Tuer gesafet.
Im Zustand Safe wird auch das Signal HFS_verriegelt = 1 gesendet.";
CM_ SG_ 974 HFS_Heckrollotaster_betaetigt "Verfahren des Heckrollos in Richtung Hoch

Bei Einfachtaster wird Bit als Togglebit verwendet (Heckrollo hoch, tief)";
CM_ SG_ 974 HFS_Tuerschloss_defekt "Das hintere Tuerschloss auf der Fahrerseite ist nicht mehr funktionsfähig.";
CM_ SG_ 974 HFS_Unlock_Taster "Betaetigung Unlock Taster";
CM_ SG_ 974 HFS_Lock_Taster "Betätigung Lock-Taster";
CM_ SG_ 974 HFS_Sperrklinke "Vorraste für Schloß

zwischen Vor- und Hauptraste Signal kurz auf 1, danach wieder auf 0 wenn Tür in Hauptraste (Tür ist sicher zu wenn Sperrklinke und Türkontakt auf 0 sind)";
CM_ SG_ 974 HFS_TAG_betaetigt "Betaetigung Türaussengriff";
CM_ SG_ 974 HFS_TIG_betaetigt "Betaetigung Türinnengriff";
CM_ SG_ 974 HFS_FH_S_HBFS_AutoHoch "Automatisches Hochfahren der Seitenscheibe HBFS";
CM_ SG_ 974 HFS_FH_S_HBFS_AutoTief "Automatisches Absenken der Seitenscheibe HBFS";
CM_ SG_ 974 HFS_FH_S_HBFS_ManHoch "Manuelles Hochfahren der Seitenscheibe HBFS";
CM_ SG_ 974 HFS_FH_S_HBFS_ManTief "Manuelles Absenken der Seitenscheibe HBFS";
CM_ SG_ 974 HFS_Tuer_Status "Türstatus mit Fehler und Initwert";
CM_ SG_ 974 HFS_SAD_Schalter "  |   Ausstelldach MD3
-----------------------------
0 | nicht_betaetigt
1 |
2 |
3 |
4 |
5 | (m) Auf
6 | (a) Auf
7 | (m) Zu
8 | (a) Zu
13| Schalter nicht verfuegbar
14| Init
15| Fehlerfall";
CM_ SG_ 974 HFS_FH_S_ManHoch "Betaetigung FH Schalter man hoch ";
CM_ SG_ 974 HFS_FH_S_AutoHoch "Betaetigung FH Schalter auto hoch";
CM_ SG_ 974 HFS_FH_S_ManTief "Betaetigung FH Schalter man tief";
CM_ SG_ 974 HFS_FH_S_AutoTief "Betaetigung FH Schalter auto tief ";
CM_ SG_ 974 HFS_FH_Oeffnung "Gibt den Fensteröffnungswert in % an.";
CM_ SG_ 974 HFS_FH_Bew_hoch "HFS Fenster bewegt sich in Richtung hoch";
CM_ SG_ 974 HFS_FH_Bew_tief "HFS Fenster bewegt sich in Richtung tief";
CM_ SG_ 974 HFS_FH_Fang "Fangbereich ist 4mm von oberer Lippendichtung";
CM_ SG_ 974 HFS_FH_Block "Fensterscheibe befindet sich im mechanischen Block (oben oder unten)";
CM_ SG_ 974 HFS_FH_Thermo "gibt an ob Fensterheber im Thermoschutz ist";
CM_ SG_ 974 HFS_UEKB_aktiviert "Überschutzbegrenzungskraft bei Reversieren";
CM_ SG_ 974 HFS_Tueroeffnen_Warnung "Bit wird gesetzt, wenn Tür während der Fahrt geoeffnet werden soll.";
CM_ SG_ 974 ASW_Warnung_aktiv_HFS "Abschaltung der Ambientefunktion Tür hinten der Fahrerseite bei aktiver ASW Warnung an der Fahrertür";
CM_ SG_ 974 HFS_Zuziehhilfe_aktiv "Fehlende Beschreibung (Import)";
CM_ SG_ 974 HFS_Status_KiSi "Status Kindersicherung hinten Fahrerseite";
CM_ SG_ 974 SSR_HFS_Pos_Unten "Signal für die 'Global Close'. Über dieses Bit wissen die anderen TSGs, ob der SSR oder der FH verfahren werden darf.";
CM_ SG_ 974 HFS_Oben_Block_erw "Fensterheber in Blockerwartung oben";
CM_ SG_ 974 HFS_Unten_Block_erw "Fensterheber in Blockerwartung unten";
CM_ SG_ 974 MTHFS_M_Taste "Betätigung M-Taste HFS";
CM_ SG_ 974 MTHFS_Pos1 "Betätigung Postionstaste 1 HFS";
CM_ SG_ 974 MTHFS_Pos2 "Betätigung Postionstaste 2 HFS
";
CM_ SG_ 974 MTHFS_Pos3 "Betätigung Postionstaste 3 HFS";
CM_ SG_ 974 HFS_MRollo_Schalter "  | MRollo2
-----------------------------
0 | nicht_betaetigt
1 | (m) Zu
2 | (a) Zu
3 | (m) Auf
4 | (a) Auf
5 | Schalter nicht verfuegbar
6 | Init
7 | Fehlerfall";
CM_ SG_ 974 HFS_Lock_Taster_inv "Lock Taster nicht betätigt";
CM_ SG_ 974 HFS_Status_eTAG "Status des elektrischen Tueraussengriffes Tuer Fahrerseite hinten";
CM_ SG_ 974 HFS_Tuer_Status_QBit "Dieses Bit gibt die Zuverlässigkeit des Türkontakts an.";
CM_ SG_ 974 HFS_TCR_Mode_aktiv "Signal zeigt eine aktive mechanische Redundanz am Türschloss an.";
CM_ BO_ 1716 "200ms bei D4 und folgende";
CM_ SG_ 1716 VIN_01_MUX "Achtung:
Die Botschaft ist nicht linear gemultiplext!!!
Sondern 0,1,0,2,0, usw.";
CM_ SG_ 1716 VIN_4 "Initwert:
0x2D bei Fahrzeugen mit Wegfahrsperrengeneration >= 5 
0x58 bei Fahrzeugen mit Wegfahrsperrengeneration < 5 (z.B. WFS-4)";
CM_ SG_ 1716 VIN_11 "Initwert:
0x2D bei Fahrzeugen mit Wegfahrsperrengeneration >= 5 
0x58 bei Fahrzeugen mit Wegfahrsperrengeneration < 5 (z.B. WFS-4)";
CM_ SG_ 1716 VIN_5 "Initwert:
0x2D bei Fahrzeugen mit Wegfahrsperrengeneration >= 5 
0x58 bei Fahrzeugen mit Wegfahrsperrengeneration < 5 (z.B. WFS-4)";
CM_ SG_ 1716 VIN_12 "Initwert:
0x2D bei Fahrzeugen mit Wegfahrsperrengeneration >= 5 
0x58 bei Fahrzeugen mit Wegfahrsperrengeneration < 5 (z.B. WFS-4)";
CM_ SG_ 1716 VIN_6 "Initwert:
0x2D bei Fahrzeugen mit Wegfahrsperrengeneration >= 5 
0x58 bei Fahrzeugen mit Wegfahrsperrengeneration < 5 (z.B. WFS-4)";
CM_ SG_ 1716 VIN_13 "Initwert:
0x2D bei Fahrzeugen mit Wegfahrsperrengeneration >= 5 
0x58 bei Fahrzeugen mit Wegfahrsperrengeneration < 5 (z.B. WFS-4)";
CM_ SG_ 1716 VIN_7 "Initwert:
0x2D bei Fahrzeugen mit Wegfahrsperrengeneration >= 5 
0x58 bei Fahrzeugen mit Wegfahrsperrengeneration < 5 (z.B. WFS-4)";
CM_ SG_ 1716 VIN_14 "Initwert:
0x2D bei Fahrzeugen mit Wegfahrsperrengeneration >= 5 
0x58 bei Fahrzeugen mit Wegfahrsperrengeneration < 5 (z.B. WFS-4)";
CM_ SG_ 1716 VIN_1 "Initwert:
0x2D bei Fahrzeugen mit Wegfahrsperrengeneration >= 5 
0x58 bei Fahrzeugen mit Wegfahrsperrengeneration < 5 (z.B. WFS-4)";
CM_ SG_ 1716 VIN_8 "Initwert:
0x2D bei Fahrzeugen mit Wegfahrsperrengeneration >= 5 
0x58 bei Fahrzeugen mit Wegfahrsperrengeneration < 5 (z.B. WFS-4)";
CM_ SG_ 1716 VIN_15 "Initwert:
0x2D bei Fahrzeugen mit Wegfahrsperrengeneration >= 5 
0x58 bei Fahrzeugen mit Wegfahrsperrengeneration < 5 (z.B. WFS-4)";
CM_ SG_ 1716 VIN_2 "Initwert:
0x2D bei Fahrzeugen mit Wegfahrsperrengeneration >= 5 
0x58 bei Fahrzeugen mit Wegfahrsperrengeneration < 5 (z.B. WFS-4)";
CM_ SG_ 1716 VIN_9 "Initwert:
0x2D bei Fahrzeugen mit Wegfahrsperrengeneration >= 5 
0x58 bei Fahrzeugen mit Wegfahrsperrengeneration < 5 (z.B. WFS-4)";
CM_ SG_ 1716 VIN_16 "Initwert:
0x2D bei Fahrzeugen mit Wegfahrsperrengeneration >= 5 
0x58 bei Fahrzeugen mit Wegfahrsperrengeneration < 5 (z.B. WFS-4)";
CM_ SG_ 1716 VIN_3 "Initwert:
0x2D bei Fahrzeugen mit Wegfahrsperrengeneration >= 5 
0x58 bei Fahrzeugen mit Wegfahrsperrengeneration < 5 (z.B. WFS-4)";
CM_ SG_ 1716 VIN_10 "Initwert:
0x2D bei Fahrzeugen mit Wegfahrsperrengeneration >= 5 
0x58 bei Fahrzeugen mit Wegfahrsperrengeneration < 5 (z.B. WFS-4)";
CM_ SG_ 1716 VIN_17 "Initwert:
0x2D bei Fahrzeugen mit Wegfahrsperrengeneration >= 5 
0x58 bei Fahrzeugen mit Wegfahrsperrengeneration < 5 (z.B. WFS-4)";
CM_ BO_ 916 "ersetzt WBA_02";
CM_ SG_ 916 WBA_03_CRC "Für MLB:
'Berechnung siehe Lastenheft 'Kommunikationsabsicherung für FlexRay und CAN''

Ab MQB und MLBevo:
'Berechnung siehe Lastenheft 'End-to-End Kommunikationsabsicherung''

Endwerte siehe Begleitdokument 'S-PDU Kennungsfolgen'";
CM_ SG_ 916 WBA_Fahrstufe_02 "Bei Automatgetrieben wird in diesem Signal die aktuelle anzuzeigende Fahrstufe ausgegeben.

Die Signalkodierungen 0x9, 0xA und 0xB werden im MSS-R8NF und MQB-A1/B/A2 verwendet.

Die Signalkodierungen 0xC und 0xD werden nur im MQB-A1/B/A2 verwendet.
";
CM_ SG_ 916 WBA_ZielFahrstufe "Zielfahrprogramm (Darstellung), für getipptes S/E/M mit neuem Wählhebel im MQB";
CM_ SG_ 916 WBA_GE_Warnung_02 "Prioritätswarnungen Getriebe";
CM_ SG_ 916 WBA_eing_Gang_02 "Das Automatikgetriebe gibt den aktuell eingelegten Gang aus.
Besonderheiten:
0x0 = marktabhängig wird auf Ganganzeige zur Fahrstufe komplett verzichtet
0xA = kurzzeitige Unterdrückung der Ganganzeige (z. B. Segeln, Zwischenstellung, etc.)";
CM_ SG_ 916 WBA_GE_Texte "Fahrerhinweise für das Kombi";
CM_ SG_ 916 WBA_Segeln_aktiv "Getriebe geht in den Segelbetrieb";
CM_ SG_ 916 WBA_Schaltschema "Bei Automatikgetrieben wird in diesem Signal die aktuelle, eingelegte Fahrstufe (=Wählhebelposition) ausgegeben.";
CM_ SG_ 916 WBA_GE_Zusatzwarnungen "Prioritaetswarnungen Getriebe an Kombi
Audi MLB Wertebereich 0 bis 3
VW MQB Projekte verwenden nur den Wertebereich 0 bis 2
VW MQB Getriebefehler werden über das Signal  GE_Warnungen_02 gesendet.";
CM_ SG_ 916 GE_Sollgang "Signalisiert den Sollgang, in den getippt werden soll. Abhängig vom Signal 'WBA_eing_Gang_02' und dem Sollgang kann dann das Kombi die Hochschaltempfehlung in Tip darstellen.";
CM_ SG_ 916 GE_Tipschaltempf_verfuegbar "Signalisierung, ob eine Hochschaltempfehlung im Tipmodus verfügbar ist oder nicht.";
CM_ SG_ 916 WBA_GE_Texte_02 "Fahrerhinweise für das Kombi";
CM_ SG_ 916 WBA_GE_Texte_03 "Launch control functionality stauts (performance strategy and smoke stratgey)";
CM_ SG_ 916 WBA_Blinken "Dieses Bit steuert die Fehlerlampe an oder wird zum Blinken der WBA-Anzeige genutzt - nur falls WBA_Senderkennung = 00 (GSG)
";
CM_ SG_ 916 GE_Wiederstart_Anz_Std "Dieses Signal gibt die detaillierte Begründung für einen Wiederstart vom Getriebesteuergerät an. ";
CM_ SG_ 916 GE_Stoppverbot_Anz_01 "Dieses Signal gibt die detaillierte Begründung für ein Stoppverbot vom Getriebesteuergerät an.";
CM_ SG_ 916 GE_Stoppverbot_Anz_02 "Dieses Signal gibt die detaillierte Begründung für ein Stoppverbot vom Getriebesteuergerät an.";
CM_ SG_ 916 GE_Stoppverbot_Anz_03 "Dieses Signal gibt die detaillierte Begründung für ein Stoppverbot vom Getriebesteuergerät an.";
CM_ SG_ 916 GE_Stoppverbot_Anz_04 "Dieses Signal gibt die detaillierte Begründung für ein Stoppverbot vom Getriebesteuergerät an.";
CM_ SG_ 916 GE_Stoppverbot_Anz_05 "Dieses Signal gibt die detaillierte Begründung für ein Stoppverbot vom Getriebesteuergerät an.";
CM_ SG_ 916 GE_Stoppverbot_Anz_06 "Dieses Signal gibt die detaillierte Begründung für ein Stoppverbot vom Getriebesteuergerät an.";
CM_ SG_ 916 GE_Stoppverbot_Anz_07 "Dieses Signal gibt die detaillierte Begründung für ein Stoppverbot vom Getriebesteuergerät an.";
CM_ SG_ 916 GE_Stoppverbot_Anz_Std "Dieses Signal gibt die detaillierte Begründung für ein Stoppverbot vom Getriebesteuergerät an.";
CM_ BO_ 1702 "MLBevo";
CM_ SG_ 1702 Wischer_vorne_aktiv "Status: Wischer vorne ";
CM_ SG_ 1702 Waschen_vorne_aktiv "Status: Waschen vorne aktiv 
";
CM_ SG_ 1702 Wischer_vorne_Normal "Wischer Front normal aktiv";
CM_ SG_ 1702 Wischer_vorne_Schnell "Wischer vorne schnell aktiv";
CM_ SG_ 1702 Wischer_vorne_Parklage "Wischer Front in Parklage";
CM_ SG_ 1702 Wischer_vorne_defekt "Fehlerstatus Wischer vorne (Anzeige im Kombi)";
CM_ SG_ 1702 Wischer_vorne_blockiert "Blockade Wischer vorne (z.B. durch Schnee)";
CM_ SG_ 1702 Wischer1_Wischgeschwindigkeit "aktuelle, durch Sensorik gemessene Wischgeschwindigkeit";
CM_ SG_ 1702 BCM1_SRA_aktiv "Status Scheinwerferreinigungsanlage";
CM_ SG_ 1702 Heckwischer_Anforderung "Das Signal beschreibt die Anforderung an den Signalausgang im BCM2 zur Ansteuerung des Heckwischers.";
CM_ SG_ 1702 WWSs_01_upd "Update-Bit für die LIN-Botschaft WWSs_01.

Betroffene Signale:

Wischer_vorne_aktiv
Wischer1_Wischgeschwindigkeit";
CM_ SG_ 1702 Wischer_Anzeigetext "Das Signal fordert einen Kombi-Pop-Up mit entsprechenden Texten an";
CM_ SG_ 1140 ZR_State_DU_1 "Kontrollbit für Display, Hintergrundbeleuchtung aus, Hintergrundbeleuchtung an, Energiesparmodus.
";
CM_ SG_ 1140 ZR_State_DU_2 "Kontrollbit für Display, Hintergrundbeleuchtung aus, Hintergrundbeleuchtung an, Energiesparmodus.
";
CM_ SG_ 1140 ZR_State_DU_3 "Kontrollbit für Display, Hintergrundbeleuchtung aus, Hintergrundbeleuchtung an, Energiesparmodus.
";
CM_ SG_ 1140 ZR_WecktGesp "Befehl zum Sperren der Wecktasten am Bedienteil.";
CM_ SG_ 1140 MMI_State "Powerstate des Zentralrechners. MMI_Off wird im Zustand dead mode gesendet.";
CM_ SG_ 1140 ZR_DimOffs_DU_1 "Dimmungs-Offset der Display Unit.";
CM_ SG_ 1140 ZR_DimOffs_DU_2 "Dimmungs-Offset der Display Unit.";
CM_ SG_ 1140 ZR_DimOffs_DU_3 "Dimmungs-Offset der Display Unit.";
CM_ SG_ 1140 SI_ICAN "Busruhe ICAN.";
CM_ SG_ 1140 ZR_Lenkerposition "Ueber Diagnose (Codierung) im Zentralrechner eingespeicherte Lenkerposition
  ";
CM_ SG_ 1140 WLC1_Systemzustand "0 = Wireless Charger off
1 = Wireless Charger on";
CM_ SG_ 1140 WLC2_Systemzustand "0 = Wireless Charger off
1 = Wireless Charger on";
CM_ SG_ 1140 ZR_SpannungSaeule "Ladespannung an der Ladesäule am nächsten geplanten Ladestopp";
CM_ SG_ 1140 ZR_LeistungSaeule "Ladeleistung der geplanten Ladesäule";
CM_ SG_ 1140 ZR_t_naechsteLadung "Dauer bis zur nächsten Schnellladung in Minuten";
CM_ SG_ 388 ZV_01_CRC "Für MLB:
'Berechnung siehe Lastenheft 'Kommunikationsabsicherung für FlexRay und CAN''

Ab MQB und MLBevo:
'Berechnung siehe Lastenheft 'End-to-End Kommunikationsabsicherung''

Endwerte siehe Begleitdokument 'S-PDU Kennungsfolgen'";
CM_ SG_ 388 ZV_FT_verriegeln "Verriegelungsanforderung ZV für FT
";
CM_ SG_ 388 ZV_FT_entriegeln "Entriegelungsanforderung ZV für FT
";
CM_ SG_ 388 ZV_BT_verriegeln "Verriegelungsanforderung ZV für BT";
CM_ SG_ 388 ZV_BT_entriegeln "Beifahrertür entriegeln (Anforderung ZV)
";
CM_ SG_ 388 ZV_HFS_verriegeln "Verriegelungsanforderung ZV für HFS
";
CM_ SG_ 388 ZV_HFS_entriegeln "Entriegelungsanforderung ZV für HFS
";
CM_ SG_ 388 ZV_HBFS_verriegeln "Verriegelungsanforderung ZV für HBFS
";
CM_ SG_ 388 ZV_HBFS_entriegeln "Entriegelungsanforderung ZV für HBFS
";
CM_ SG_ 388 ZV_zentral_safen "Zentral safen

";
CM_ SG_ 388 ZV_zentral_entsafen "Zentral entsafen";
CM_ SG_ 388 ZV_Spg_Anklappen "Anforderung über ZV: Spiegel sind anzuklappen";
CM_ SG_ 388 ZV_Softtouch_betaetigt "Betätigung Softtouch
";
CM_ SG_ 388 ZV_LED_Steuerung "Ansteuerung der LED's in den Tueren; BAF gilt nicht für dieses Bit";
CM_ SG_ 388 ZV_LED_Uebernahme "Uebernahme der LED Steuerung durch das TSG FT
";
CM_ SG_ 388 ZV_auf_FT "ZV Schliessstelle";
CM_ SG_ 388 ZV_zu_FT "ZV Schliessstelle";
CM_ SG_ 388 ZV_auf_BT "ZV Schliessstelle";
CM_ SG_ 388 ZV_zu_BT "ZV Schliessstelle";
CM_ SG_ 388 ZV_auf_Kessy "ZV Schliessstelle";
CM_ SG_ 388 ZV_zu_Kessy "ZV Schliessstelle";
CM_ SG_ 388 ZV_auf_Funk "ZV Schliessstelle";
CM_ SG_ 388 ZV_zu_Funk "ZV Schliessstelle";
CM_ SG_ 388 VIP_Sensor_betaetigt "Heckentriegelung durch die Bedienstelle Virtuelles Pedal(VIP) erkannt. Der VIP Sensor hat eine Fusskickbewegung erkannt und es wurde ein Kessy - Schlüssel im Heckaussenbereich erkannt.";
CM_ SG_ 388 VIP_Freigabe "Vituelles Pedal ist über HMI freigeschaltet.";
CM_ SG_ 388 ZV_zu_Zeitl_Nachverr "ZV Schliessstelle";
CM_ SG_ 388 ZV_HSK_entriegeln "Anforderungssignal zur Ansteuerung des Handschuhkastenmotors in Richtung Entriegeln. ";
CM_ SG_ 388 ZV_HSK_verriegeln "Anforderungssignal zur Ansteuerung des Handschuhkastenmotors in Richtung Verriegeln. ";
CM_ SG_ 388 ZV_Verdeck_zu "Anforderungssignal für ein Komfortschließen des Verdecks. 
Signal wird angefordert wenn  SKontakt = 0 und eine Doppelbetätigung Schließzylinder_Zu oder Funkfernbedienung_Taste_zu  innerhalb zwei Sekunden empfangen wird. Signal wird auch angefordert wenn ";
CM_ SG_ 388 ZV_Verdeck_auf "Anforderungssignal für ein Komfortöffnen des Verdecks. 
Signal wird angefordert wenn  SKontakt = 0 und eine Doppelbetätigung Schließzylinder_auf oder Funkfernbedienung_Taste_auf  innerhalb zwei Sekunden empfangen wird. Signal wird auch angefordert wenn S";
CM_ SG_ 388 FH_FT_hoch "Freigabeinformation fuer die FH-Komfortfunktion";
CM_ SG_ 388 FH_FT_tief "Freigabeinformation fuer die FH-Komfortfunktion";
CM_ SG_ 388 FH_BT_hoch "Freigabeinformation fuer die FH-Komfortfunktion";
CM_ SG_ 388 FH_BT_tief "Freigabeinformation fuer die FH-Komfortfunktion";
CM_ SG_ 388 FH_HFS_hoch "Freigabeinformation fuer die FH-Komfortfunktion";
CM_ SG_ 388 FH_HFS_tief "Freigabeinformation fuer die FH-Komfortfunktion";
CM_ SG_ 388 FH_HBFS_hoch "Freigabeinformation fuer die FH-Komfortfunktion";
CM_ SG_ 388 FH_HBFS_tief "Freigabeinformation fuer die FH-Komfortfunktion";
CM_ SG_ 388 BCM_Spg_Synchron "Anforderung zur Aktivierung der synchronen Spiegelverstellung";
CM_ SG_ 388 BCM_BF_Spg_Absenkung "Spiegelabsenkung Beifahrerseite";
CM_ SG_ 388 ZV_Signatur "Signatur der ZV";
CM_ SG_ 388 ZV_entriegeln_Anf "Bei ZV Anforderung erfolgt die Entriegelung des Ladesteckers";
CM_ SG_ 388 ZV_auto_Ansteuerung "Kennung für die automatische Ansteuerung der Zentralverriegelung (Autolock/Autounlock)";
CM_ SG_ 1411 BCM_FH_Freigabe "Funktionsfreigabe Fensterheber";
CM_ SG_ 1411 BCM_Komfortfkt_Freigabe "globale Freigabe der Komfortfunktion";
CM_ SG_ 1411 BCM_HSK_Freigabe "Handschuhkastenfreigabe";
CM_ SG_ 1411 BCM_Verdeck_Freigabe "Freigabe Verdeckbetrieb
";
CM_ SG_ 1411 ZV_verriegelt_intern_ist "Istzustand: Verriegelung Fahrzeug innen
";
CM_ SG_ 1411 ZV_verriegelt_extern_ist "Istzustand: Verriegelung Fahrzeug aussen
";
CM_ SG_ 1411 ZV_verriegelt_intern_soll "Sollzustand: Verriegelung Fahrzeug innen
";
CM_ SG_ 1411 ZV_verriegelt_extern_soll "Sollzustand: Verriegelung Fahrzeug aussen
";
CM_ SG_ 1411 ZV_gesafet_extern_ist "Istzustand: Fahrzeug aussen gesafet
";
CM_ SG_ 1411 ZV_gesafet_extern_soll "Sollzustand: Fahrzeug gesafet extern
";
CM_ SG_ 1411 ZV_Einzeltuerentriegelung "Einzeltürentriegelung ZV
";
CM_ SG_ 1411 ZV_Heckeinzelentriegelung "Heckdeckeleinzelentriegelung";
CM_ SG_ 1411 ZV_FT_offen "gespiegeltes Bit FT_Tuer_geoeffnet TSG_FT_1 Botschaft";
CM_ SG_ 1411 ZV_BT_offen "gespiegeltes Bit BT_Tuer_geoeffnet TSG_BT_1 Botschaft";
CM_ SG_ 1411 ZV_HFS_offen "gespiegeltes Bit HFS_Tuer_geoeffnet TSG_HFS_1 Botschaft";
CM_ SG_ 1411 ZV_HBFS_offen "gespiegeltes Bit HBFS_Tuer_geoeffnet TSG_HBFS_1 Botschaft";
CM_ SG_ 1411 ZV_HD_offen "Status Heckdeckel
";
CM_ SG_ 1411 ZV_HS_offen "Status Heckscheibe
";
CM_ SG_ 1411 IRUE_aktiv "Status Innenraumüberwachung
";
CM_ SG_ 1411 DWA_aktiv "Status DWA
";
CM_ SG_ 1411 HD_Hauptraste "SBL-Schloss (MQB/MLBevo): Drehfalle Heckdeckel
sonst (MQB): Hauptraste Heckdeckel";
CM_ SG_ 1411 HD_Vorraste "SBL_Schloss (MQB/MLBevo): Sperrklinke Heckdeckel
sonst (MQB): Vorraste Heckdeckel";
CM_ SG_ 1411 FFB_CarFinder "Car Finder Funktion (Blinken ohne zu entriegeln)";
CM_ SG_ 1411 FFB_Komfortoeffnen "Komfortoeffnen Funk
";
CM_ SG_ 1411 FFB_Komfortschliessen "Komfortschliessen Funk
";
CM_ SG_ 1411 ZV_Schluessel_Zugang "aktuelle Funkschlüsselnummer";
CM_ SG_ 1411 ZV_SafeFunktion_aktiv "Statusübermittlung ob die Safe Funktion im Fzg. aktiv ist. Das Kombi benötigt das Signal, um den Text Safelock aktiv anzuzeigen. ";
CM_ SG_ 1411 FBS_Warn_Schluessel_Batt "Kombi Prio Warnung Schluessel Batterie
'Bitte Schlüsselbatterie wechseln!'";
CM_ SG_ 1411 ZV_Oeffnungsmodus "Konfigurierter Oeffnungsmodus fuer ZV:
0 = globale Oeffnung (alle Tueren)
1 = ZV mit Einzeltuerentriegelung (FFB - nur Fahrertuer, Kessy - nur bediente Tuer)
2 = ZV individuell selektive Oeffnung (FFB - Fahrerseite, Kessy - bediente Tuer + Fahrertuer)";
CM_ SG_ 1411 HFS_verriegelt "HFS Tuer verriegelt";
CM_ SG_ 1411 HFS_gesafet "HFS Tuer gesafet.
Im Zustand Safe wird auch das Signal HFS_verriegelt = 1 gesendet.";
CM_ SG_ 1411 HBFS_verriegelt "Verriegelungsstatus Tür";
CM_ SG_ 1411 HBFS_gesafet "HBFS Tuer gesafet.
Im Zustand Safe wird auch das Signal HBFS_verriegelt = 1 gesendet.";
CM_ SG_ 1411 ZV_ist_Zustand_verfuegbar "Verfügbarkeit IST-Zustand ZV

";
CM_ SG_ 1411 IRUE_Taster_Fkts_LED "Anforderung Funktions-LED IRUE-Taster (LED wird vom TSG angesteuert)
MQB: Bei Verbau eines einzelnen Taster zur Deaktivierung von IRUE und NGS wird dieses Signal zur Ansteuerung der Funktions-LED gesendet.";
CM_ SG_ 1411 ZV_Tankklappe_offen "Öffnungsstatus der Tankklappe";
CM_ SG_ 1411 ZV_Rollo_auf "Komfortöffnen des Dachrollos";
CM_ SG_ 1411 ZV_Rollo_zu "Komfortschließen des Dachrollos";
CM_ SG_ 1411 ZV_SAD_auf "Komfortöffnen des Schiebeausstelldaches";
CM_ SG_ 1411 ZV_SAD_zu "Komfortschließen des Schiebeausstelldaches";
CM_ SG_ 1411 BCM_Tankklappensteller_Fehler "Fehler: nicht Funktionalität des Tankklappenstellers";
CM_ SG_ 1411 ZV_verriegelt_soll "Fahrzeug Gesamtverriegelungsstatus Sollzustand für Ladestecker- und Ladeklappenverriegelung. ";
BA_DEF_ BO_  "DiagRequest" ENUM  "No","Yes";
BA_DEF_ BO_  "DiagResponse" ENUM  "No","Yes";
BA_DEF_ BO_  "DiagState" ENUM  "No","Yes";
BA_DEF_ BO_  "GenMsgChkConstant" HEX 0 4095;
BA_DEF_ BO_  "GenMsgCycleTime" INT 0 65535;
BA_DEF_ BO_  "GenMsgCycleTimeFast" INT 0 65535;
BA_DEF_ BO_  "GenMsgDelayTime" INT 0 100000;
BA_DEF_ BO_  "GenMsgILSupport" ENUM  "No","Yes";
BA_DEF_ BO_  "GenMsgNrOfRepetition" INT 0 100;
BA_DEF_ BO_  "GenMsgPDUConstants" STRING ;
BA_DEF_ BO_  "GenMsgSendType" ENUM  "Cyclic","not_used","not_used","not_used","not_used","not_used","not_used","IfActive","NoMsgSendType";
BA_DEF_ BO_  "GenMsgStartDelayTime" INT 0 100000;
BA_DEF_ BO_  "NmMessage" ENUM  "No","Yes";
BA_DEF_ BO_  "NmhMessage" ENUM  "No","Yes";
BA_DEF_ BO_  "MsgType" ENUM  "Application","NM ","NMH","TP2.0","ISO-TP ","BAP","EID","KS","XCP_PRE_CONFIGURED","XCP_RUNTIME_CONFIGURED";
BA_DEF_ BO_  "VAGTP20_API" HEX 0 255;
BA_DEF_ BO_  "VAGTP20_DynConnection" ENUM  "No","Yes";
BA_DEF_ BO_  "VAGTP20_DynSetup" ENUM  "No","Yes";
BA_DEF_ BO_  "VAGTP20_StatConnection" ENUM  "No","Yes";
BA_DEF_ SG_  "GenSigActiveRepetitions" INT -2147483648 2147483647;
BA_DEF_ SG_  "GenSigInactiveValue" INT -2147483648 2147483647;
BA_DEF_ SG_  "GenSigSendType" ENUM  "Cyclic","OnWrite","OnWriteWithRepetition","OnChange","OnChangeWithRepetition","IfActive","IfActiveWithRepetition","NoSigSendType","OnChangeAndIfActive","OnChangeAndIfActiveWithRepetition";
BA_DEF_ SG_  "GenSigStartValue" INT -2147483648 2147483647;
BA_DEF_ SG_  "NWM-WakeupAllowed" ENUM  "No","Yes";
BA_DEF_ SG_  "GenSigFuncType" ENUM  "NoFunction","MsgCounter","CRC-8","XOR","XOR-2","DatedBit","SW-Kl15","CHK","Constant","Protocol","CRC-8-SAE_J1850","CRC-32","DataLength","DataID","MsgCounter16","SOK-Signatur","Cluster";
BA_DEF_ SG_  "GenSigSwitchedByIgnition" ENUM  "No","Yes";
BA_DEF_ SG_  "Fehlerwert" HEX 0 2147483647;
BA_DEF_ SG_  "GenSigMissingSourceValue" HEX 0 2147483647;
BA_DEF_REL_ BU_SG_REL_  "GenSigTimeoutTime" INT 0 65535;
BA_DEF_DEF_REL_ "GenSigTimeoutTime" 0;
BA_DEF_DEF_  "DiagRequest" "No";
BA_DEF_DEF_  "DiagResponse" "No";
BA_DEF_DEF_  "DiagState" "No";
BA_DEF_DEF_  "GenMsgChkConstant" 0;
BA_DEF_DEF_  "GenMsgCycleTime" 0;
BA_DEF_DEF_  "GenMsgCycleTimeFast" 0;
BA_DEF_DEF_  "GenMsgDelayTime" 0;
BA_DEF_DEF_  "GenMsgILSupport" "No";
BA_DEF_DEF_  "GenMsgNrOfRepetition" 0;
BA_DEF_DEF_  "GenMsgPDUConstants" "";
BA_DEF_DEF_  "GenMsgSendType" "NoMsgSendType";
BA_DEF_DEF_  "GenMsgStartDelayTime" 0;
BA_DEF_DEF_  "NmMessage" "No";
BA_DEF_DEF_  "NmhMessage" "No";
BA_DEF_DEF_  "MsgType" "Application";
BA_DEF_DEF_  "VAGTP20_API" 0;
BA_DEF_DEF_  "VAGTP20_DynConnection" "No";
BA_DEF_DEF_  "VAGTP20_DynSetup" "No";
BA_DEF_DEF_  "VAGTP20_StatConnection" "No";
BA_DEF_DEF_  "GenSigActiveRepetitions" 0;
BA_DEF_DEF_  "GenSigInactiveValue" 0;
BA_DEF_DEF_  "GenSigSendType" "NoSigSendType";
BA_DEF_DEF_  "GenSigStartValue" 0;
BA_DEF_DEF_  "NWM-WakeupAllowed" "No";
BA_DEF_DEF_  "GenSigFuncType" "NoFunction";
BA_DEF_DEF_  "GenSigSwitchedByIgnition" "Yes";
BA_DEF_DEF_  "Fehlerwert" 0;
BA_DEF_DEF_  "GenSigMissingSourceValue" 0;
BA_ "GenMsgSendType" BO_ 1399 0;
BA_ "GenMsgILSupport" BO_ 1399 1;
BA_ "GenMsgCycleTime" BO_ 1399 320;
BA_ "GenMsgSendType" BO_ 1375 0;
BA_ "GenMsgILSupport" BO_ 1375 1;
BA_ "GenMsgDelayTime" BO_ 1375 20;
BA_ "GenMsgCycleTime" BO_ 1375 500;
BA_ "GenMsgSendType" BO_ 1373 0;
BA_ "GenMsgILSupport" BO_ 1373 1;
BA_ "GenMsgDelayTime" BO_ 1373 200;
BA_ "GenMsgCycleTime" BO_ 1373 500;
BA_ "GenMsgSendType" BO_ 1657 0;
BA_ "GenMsgILSupport" BO_ 1657 1;
BA_ "GenMsgCycleTime" BO_ 1657 500;
BA_ "GenMsgSendType" BO_ 2463978655 0;
BA_ "GenMsgILSupport" BO_ 2463978655 1;
BA_ "GenMsgCycleTime" BO_ 2463978655 100;
BA_ "GenMsgSendType" BO_ 2589283463 0;
BA_ "GenMsgILSupport" BO_ 2589283463 1;
BA_ "GenMsgCycleTime" BO_ 2589283463 500;
BA_ "GenMsgSendType" BO_ 2589283408 0;
BA_ "GenMsgILSupport" BO_ 2589283408 1;
BA_ "GenMsgCycleTime" BO_ 2589283408 500;
BA_ "GenMsgSendType" BO_ 2527679716 0;
BA_ "GenMsgILSupport" BO_ 2527679716 1;
BA_ "GenMsgCycleTime" BO_ 2527679716 200;
BA_ "GenMsgSendType" BO_ 2527679717 0;
BA_ "GenMsgILSupport" BO_ 2527679717 1;
BA_ "GenMsgCycleTime" BO_ 2527679717 200;
BA_ "GenMsgSendType" BO_ 2527679718 0;
BA_ "GenMsgILSupport" BO_ 2527679718 1;
BA_ "GenMsgCycleTime" BO_ 2527679718 200;
BA_ "GenMsgSendType" BO_ 2463978733 0;
BA_ "GenMsgILSupport" BO_ 2463978733 1;
BA_ "GenMsgCycleTime" BO_ 2463978733 100;
BA_ "GenMsgSendType" BO_ 977 0;
BA_ "GenMsgILSupport" BO_ 977 1;
BA_ "GenMsgDelayTime" BO_ 977 20;
BA_ "GenMsgCycleTime" BO_ 977 100;
BA_ "GenMsgSendType" BO_ 976 0;
BA_ "GenMsgILSupport" BO_ 976 1;
BA_ "GenMsgDelayTime" BO_ 976 20;
BA_ "GenMsgCycleTime" BO_ 976 100;
BA_ "GenMsgSendType" BO_ 975 0;
BA_ "GenMsgILSupport" BO_ 975 1;
BA_ "GenMsgDelayTime" BO_ 975 20;
BA_ "GenMsgCycleTime" BO_ 975 100;
BA_ "GenMsgSendType" BO_ 974 0;
BA_ "GenMsgILSupport" BO_ 974 1;
BA_ "GenMsgDelayTime" BO_ 974 20;
BA_ "GenMsgCycleTime" BO_ 974 100;
BA_ "GenMsgSendType" BO_ 1716 0;
BA_ "GenMsgILSupport" BO_ 1716 1;
BA_ "GenMsgCycleTime" BO_ 1716 200;
BA_ "GenMsgSendType" BO_ 916 0;
BA_ "GenMsgPDUConstants" BO_ 916 "0x47,0x94,0x92,0x6a,0x67,0xb5,0x0d,0x38,0xe3,0x8a,0x5d,0xb4,0x54,0xab,0xae,0x27";
BA_ "GenMsgILSupport" BO_ 916 1;
BA_ "GenMsgDelayTime" BO_ 916 10;
BA_ "GenMsgCycleTime" BO_ 916 160;
BA_ "GenMsgSendType" BO_ 1702 0;
BA_ "GenMsgNrOfRepetition" BO_ 1702 3;
BA_ "GenMsgILSupport" BO_ 1702 1;
BA_ "GenMsgDelayTime" BO_ 1702 50;
BA_ "GenMsgCycleTimeFast" BO_ 1702 100;
BA_ "GenMsgCycleTime" BO_ 1702 500;
BA_ "MsgType" BO_ 2617016064 6;
BA_ "MsgType" BO_ 2617016065 6;
BA_ "MsgType" BO_ 2617079552 6;
BA_ "MsgType" BO_ 2617079553 6;
BA_ "MsgType" BO_ 2617042689 6;
BA_ "MsgType" BO_ 2617118208 6;
BA_ "MsgType" BO_ 2617118209 6;
BA_ "MsgType" BO_ 2617097984 6;
BA_ "MsgType" BO_ 2617097985 6;
BA_ "MsgType" BO_ 2617093888 6;
BA_ "MsgType" BO_ 2617093889 6;
BA_ "MsgType" BO_ 2617120256 8;
BA_ "MsgType" BO_ 2617120257 9;
BA_ "GenMsgSendType" BO_ 1140 0;
BA_ "GenMsgILSupport" BO_ 1140 1;
BA_ "GenMsgDelayTime" BO_ 1140 40;
BA_ "GenMsgCycleTime" BO_ 1140 1000;
BA_ "GenMsgSendType" BO_ 388 0;
BA_ "GenMsgPDUConstants" BO_ 388 "0xe3,0xe8,0xc4,0x7f,0xf1,0x95,0xd8,0xb0,0xc7,0xa3,0xf4,0x6c,0xe7,0xc3,0x5a,0xf7";
BA_ "GenMsgNrOfRepetition" BO_ 388 11;
BA_ "GenMsgILSupport" BO_ 388 1;
BA_ "GenMsgCycleTimeFast" BO_ 388 20;
BA_ "GenMsgCycleTime" BO_ 388 1000;
BA_ "GenMsgSendType" BO_ 1411 0;
BA_ "GenMsgNrOfRepetition" BO_ 1411 5;
BA_ "GenMsgILSupport" BO_ 1411 1;
BA_ "GenMsgDelayTime" BO_ 1411 50;
BA_ "GenMsgCycleTimeFast" BO_ 1411 50;
BA_ "GenMsgCycleTime" BO_ 1411 200;
BA_ "Fehlerwert" SG_ 1399 TME_Leistung_Komfort_HV_stat 255;
BA_ "GenSigSwitchedByIgnition" SG_ 1399 TME_Leistung_Komfort_HV_stat 0;
BA_ "GenSigStartValue" SG_ 1399 TME_Leistung_Komfort_HV_stat 254;
BA_ "GenSigSendType" SG_ 1399 TME_Leistung_Komfort_HV_stat 0;
BA_ "Fehlerwert" SG_ 1399 TME_Leistung_Thermo_HV_stat 255;
BA_ "GenSigSwitchedByIgnition" SG_ 1399 TME_Leistung_Thermo_HV_stat 0;
BA_ "GenSigStartValue" SG_ 1399 TME_Leistung_Thermo_HV_stat 254;
BA_ "GenSigSendType" SG_ 1399 TME_Leistung_Thermo_HV_stat 0;
BA_ "Fehlerwert" SG_ 1399 TME_Energie_Komfort_NV 16383;
BA_ "GenSigSwitchedByIgnition" SG_ 1399 TME_Energie_Komfort_NV 0;
BA_ "GenSigStartValue" SG_ 1399 TME_Energie_Komfort_NV 16382;
BA_ "GenSigSendType" SG_ 1399 TME_Energie_Komfort_NV 0;
BA_ "Fehlerwert" SG_ 1399 TME_Energie_Thermo_NV 16383;
BA_ "GenSigSwitchedByIgnition" SG_ 1399 TME_Energie_Thermo_NV 0;
BA_ "GenSigStartValue" SG_ 1399 TME_Energie_Thermo_NV 16382;
BA_ "GenSigSendType" SG_ 1399 TME_Energie_Thermo_NV 0;
BA_ "Fehlerwert" SG_ 1399 TME_Leistung_Komfort_NV_stat 255;
BA_ "GenSigSwitchedByIgnition" SG_ 1399 TME_Leistung_Komfort_NV_stat 0;
BA_ "GenSigStartValue" SG_ 1399 TME_Leistung_Komfort_NV_stat 254;
BA_ "GenSigSendType" SG_ 1399 TME_Leistung_Komfort_NV_stat 0;
BA_ "Fehlerwert" SG_ 1399 TME_Leistung_Thermo_NV_stat 255;
BA_ "GenSigSwitchedByIgnition" SG_ 1399 TME_Leistung_Thermo_NV_stat 0;
BA_ "GenSigStartValue" SG_ 1399 TME_Leistung_Thermo_NV_stat 254;
BA_ "GenSigSendType" SG_ 1399 TME_Leistung_Thermo_NV_stat 0;
BA_ "Fehlerwert" SG_ 1375 TME_VoKo_Strategie_Anzeige 15;
BA_ "GenSigSwitchedByIgnition" SG_ 1375 TME_VoKo_Strategie_Anzeige 0;
BA_ "GenSigStartValue" SG_ 1375 TME_VoKo_Strategie_Anzeige 14;
BA_ "GenSigSendType" SG_ 1375 TME_VoKo_Strategie_Anzeige 3;
BA_ "GenSigSwitchedByIgnition" SG_ 1375 TME_Zuheizer_Freigabe 0;
BA_ "GenSigSendType" SG_ 1375 TME_Zuheizer_Freigabe 3;
BA_ "GenSigSwitchedByIgnition" SG_ 1375 TME_AC_LED 0;
BA_ "GenSigSendType" SG_ 1375 TME_AC_LED 3;
BA_ "Fehlerwert" SG_ 1375 TME_Heizstrategie 15;
BA_ "GenSigSwitchedByIgnition" SG_ 1375 TME_Heizstrategie 0;
BA_ "GenSigSendType" SG_ 1375 TME_Heizstrategie 3;
BA_ "Fehlerwert" SG_ 1375 TME_Systemstatus 3;
BA_ "GenSigSwitchedByIgnition" SG_ 1375 TME_Systemstatus 0;
BA_ "GenSigSendType" SG_ 1375 TME_Systemstatus 3;
BA_ "GenSigSwitchedByIgnition" SG_ 1375 TME_Kbr_Innenraum 0;
BA_ "GenSigSendType" SG_ 1375 TME_Kbr_Innenraum 3;
BA_ "GenSigSwitchedByIgnition" SG_ 1375 TME_Freigabe_Vorkond 0;
BA_ "GenSigSendType" SG_ 1375 TME_Freigabe_Vorkond 3;
BA_ "GenSigSwitchedByIgnition" SG_ 1375 TME_Verdampfer_Status 0;
BA_ "GenSigSendType" SG_ 1375 TME_Verdampfer_Status 3;
BA_ "GenSigSwitchedByIgnition" SG_ 1375 TME_Kuehlmittel_Sensor 0;
BA_ "GenSigSendType" SG_ 1375 TME_Kuehlmittel_Sensor 0;
BA_ "Fehlerwert" SG_ 1375 TME_AC_Rueckmeldung 3;
BA_ "GenSigSwitchedByIgnition" SG_ 1375 TME_AC_Rueckmeldung 0;
BA_ "GenSigSendType" SG_ 1375 TME_AC_Rueckmeldung 0;
BA_ "Fehlerwert" SG_ 1375 TME_Heizungspumpen_Anst 13;
BA_ "GenSigSwitchedByIgnition" SG_ 1375 TME_Heizungspumpen_Anst 0;
BA_ "GenSigStartValue" SG_ 1375 TME_Heizungspumpen_Anst 14;
BA_ "GenSigSendType" SG_ 1375 TME_Heizungspumpen_Anst 0;
BA_ "Fehlerwert" SG_ 1375 TME_Frischluftklappe_Soll 127;
BA_ "GenSigSwitchedByIgnition" SG_ 1375 TME_Frischluftklappe_Soll 0;
BA_ "GenSigStartValue" SG_ 1375 TME_Frischluftklappe_Soll 126;
BA_ "GenSigSendType" SG_ 1375 TME_Frischluftklappe_Soll 0;
BA_ "GenSigSwitchedByIgnition" SG_ 1375 TME_Freigabe_Luft_PTC 0;
BA_ "GenSigSendType" SG_ 1375 TME_Freigabe_Luft_PTC 0;
BA_ "Fehlerwert" SG_ 1375 TME_Umluftklappe_Soll 127;
BA_ "GenSigSwitchedByIgnition" SG_ 1375 TME_Umluftklappe_Soll 0;
BA_ "GenSigSendType" SG_ 1375 TME_Umluftklappe_Soll 0;
BA_ "GenSigSwitchedByIgnition" SG_ 1375 TME_Waermepumpe_aktiv 0;
BA_ "GenSigSendType" SG_ 1375 TME_Waermepumpe_aktiv 0;
BA_ "GenSigSwitchedByIgnition" SG_ 1375 TME_Nachlaufzeit_Heizp 0;
BA_ "GenSigSendType" SG_ 1375 TME_Nachlaufzeit_Heizp 0;
BA_ "GenSigSwitchedByIgnition" SG_ 1375 TME_Absperrventil1_oeffnen 0;
BA_ "GenSigSendType" SG_ 1375 TME_Absperrventil1_oeffnen 0;
BA_ "Fehlerwert" SG_ 1375 TME_Klima_Defizit 255;
BA_ "GenSigSwitchedByIgnition" SG_ 1375 TME_Klima_Defizit 0;
BA_ "GenSigStartValue" SG_ 1375 TME_Klima_Defizit 254;
BA_ "GenSigSendType" SG_ 1375 TME_Klima_Defizit 0;
BA_ "Fehlerwert" SG_ 1375 TME_Temp_KM_vor_HWT 255;
BA_ "GenSigSwitchedByIgnition" SG_ 1375 TME_Temp_KM_vor_HWT 0;
BA_ "GenSigStartValue" SG_ 1375 TME_Temp_KM_vor_HWT 254;
BA_ "GenSigSendType" SG_ 1375 TME_Temp_KM_vor_HWT 0;
BA_ "GenSigSendType" SG_ 1373 TME_Geblaese 0;
BA_ "GenSigSwitchedByIgnition" SG_ 1373 TME_Kond_Innen_Betrieb 0;
BA_ "GenSigSendType" SG_ 1373 TME_Kond_Innen_Betrieb 3;
BA_ "GenSigSwitchedByIgnition" SG_ 1373 TME_Klimadefizit 0;
BA_ "GenSigSendType" SG_ 1373 TME_Klimadefizit 0;
BA_ "Fehlerwert" SG_ 1373 TME_STH_Status 7;
BA_ "GenSigSwitchedByIgnition" SG_ 1373 TME_STH_Status 0;
BA_ "GenSigSendType" SG_ 1373 TME_STH_Status 3;
BA_ "GenSigSwitchedByIgnition" SG_ 1373 TME_Kond_Innen_Betriebsdauer 0;
BA_ "GenSigSendType" SG_ 1373 TME_Kond_Innen_Betriebsdauer 3;
BA_ "GenSigSwitchedByIgnition" SG_ 1373 TME_Kond_Innen_Status 0;
BA_ "GenSigSendType" SG_ 1373 TME_Kond_Innen_Status 3;
BA_ "GenSigSwitchedByIgnition" SG_ 1373 TME_STH_Ansteuerung 0;
BA_ "GenSigSendType" SG_ 1373 TME_STH_Ansteuerung 3;
BA_ "Fehlerwert" SG_ 1373 TME_Verdampfertemperatur 1023;
BA_ "GenSigStartValue" SG_ 1373 TME_Verdampfertemperatur 1022;
BA_ "GenSigSendType" SG_ 1373 TME_Verdampfertemperatur 0;
BA_ "Fehlerwert" SG_ 1373 TME_Temp_KM_vor_LE 255;
BA_ "GenSigSwitchedByIgnition" SG_ 1373 TME_Temp_KM_vor_LE 0;
BA_ "GenSigStartValue" SG_ 1373 TME_Temp_KM_vor_LE 254;
BA_ "GenSigSendType" SG_ 1373 TME_Temp_KM_vor_LE 0;
BA_ "Fehlerwert" SG_ 1373 TME_Kuehlmittel_Temp_Pumpe1_tNT 255;
BA_ "GenSigSwitchedByIgnition" SG_ 1373 TME_Kuehlmittel_Temp_Pumpe1_tNT 0;
BA_ "GenSigStartValue" SG_ 1373 TME_Kuehlmittel_Temp_Pumpe1_tNT 254;
BA_ "GenSigSendType" SG_ 1373 TME_Kuehlmittel_Temp_Pumpe1_tNT 0;
BA_ "Fehlerwert" SG_ 1373 TME_STH_aktiv 3;
BA_ "GenSigSwitchedByIgnition" SG_ 1373 TME_STH_aktiv 0;
BA_ "GenSigSendType" SG_ 1373 TME_STH_aktiv 3;
BA_ "Fehlerwert" SG_ 1373 TME_SKE_Status_2 3;
BA_ "GenSigSwitchedByIgnition" SG_ 1373 TME_SKE_Status_2 0;
BA_ "GenSigSendType" SG_ 1373 TME_SKE_Status_2 0;
BA_ "Fehlerwert" SG_ 1373 TME_STL_aktiv 3;
BA_ "GenSigSwitchedByIgnition" SG_ 1373 TME_STL_aktiv 0;
BA_ "GenSigSendType" SG_ 1373 TME_STL_aktiv 3;
BA_ "GenSigSwitchedByIgnition" SG_ 1373 TME_Thermomanagement 0;
BA_ "GenSigSendType" SG_ 1373 TME_Thermomanagement 0;
BA_ "GenSigSwitchedByIgnition" SG_ 1373 TME_IstSpannung_EKK_HV 0;
BA_ "GenSigStartValue" SG_ 1373 TME_IstSpannung_EKK_HV 255;
BA_ "GenSigSendType" SG_ 1373 TME_IstSpannung_EKK_HV 0;
BA_ "Fehlerwert" SG_ 1657 TME_Temp_KM_nach_EM 255;
BA_ "GenSigSwitchedByIgnition" SG_ 1657 TME_Temp_KM_nach_EM 0;
BA_ "GenSigStartValue" SG_ 1657 TME_Temp_KM_nach_EM 254;
BA_ "GenSigSendType" SG_ 1657 TME_Temp_KM_nach_EM 0;
BA_ "GenSigSwitchedByIgnition" SG_ 1657 TME_EKK_ProtectionMode 0;
BA_ "GenSigSendType" SG_ 1657 TME_EKK_ProtectionMode 0;
BA_ "GenSigSwitchedByIgnition" SG_ 1657 TME_Klimaanforderung 0;
BA_ "GenSigSendType" SG_ 1657 TME_Klimaanforderung 0;
BA_ "GenSigSwitchedByIgnition" SG_ 1657 TME_SKE_Pos_Summe 0;
BA_ "GenSigStartValue" SG_ 1657 TME_SKE_Pos_Summe 14;
BA_ "GenSigSendType" SG_ 1657 TME_SKE_Pos_Summe 0;
BA_ "Fehlerwert" SG_ 1657 TME_Waermebilanz_Status 3;
BA_ "GenSigSwitchedByIgnition" SG_ 1657 TME_Waermebilanz_Status 0;
BA_ "GenSigSendType" SG_ 1657 TME_Waermebilanz_Status 0;
BA_ "GenSigSwitchedByIgnition" SG_ 1657 TME_Waermebilanz 0;
BA_ "GenSigSendType" SG_ 1657 TME_Waermebilanz 0;
BA_ "GenSigSwitchedByIgnition" SG_ 1657 TME_Klimaleistung 0;
BA_ "GenSigStartValue" SG_ 1657 TME_Klimaleistung 126;
BA_ "GenSigSendType" SG_ 1657 TME_Klimaleistung 0;
BA_ "GenSigSwitchedByIgnition" SG_ 1657 TME_SKE_PosResp 0;
BA_ "GenSigStartValue" SG_ 1657 TME_SKE_PosResp 1;
BA_ "GenSigSendType" SG_ 1657 TME_SKE_PosResp 0;
BA_ "GenSigSwitchedByIgnition" SG_ 1657 TME_SKE_Position_1 0;
BA_ "GenSigStartValue" SG_ 1657 TME_SKE_Position_1 3;
BA_ "GenSigSendType" SG_ 1657 TME_SKE_Position_1 0;
BA_ "Fehlerwert" SG_ 1657 TME_Systemtemp 255;
BA_ "GenSigSwitchedByIgnition" SG_ 1657 TME_Systemtemp 0;
BA_ "GenSigStartValue" SG_ 1657 TME_Systemtemp 254;
BA_ "GenSigSendType" SG_ 1657 TME_Systemtemp 0;
BA_ "GenSigSwitchedByIgnition" SG_ 1657 TME_Eingriff_SKE_Oeffnung 0;
BA_ "GenSigSendType" SG_ 1657 TME_Eingriff_SKE_Oeffnung 0;
BA_ "Fehlerwert" SG_ 1657 TME_SKE_Status 3;
BA_ "GenSigSwitchedByIgnition" SG_ 1657 TME_SKE_Status 0;
BA_ "GenSigSendType" SG_ 1657 TME_SKE_Status 0;
BA_ "GenSigSwitchedByIgnition" SG_ 1657 TME_Status_Kuehlmittel_Tmp_CrChk 0;
BA_ "GenSigSendType" SG_ 1657 TME_Status_Kuehlmittel_Tmp_CrChk 0;
BA_ "Fehlerwert" SG_ 1657 TME_Temperatur_Ruecklauf_VKM 255;
BA_ "GenSigSwitchedByIgnition" SG_ 1657 TME_Temperatur_Ruecklauf_VKM 0;
BA_ "GenSigStartValue" SG_ 1657 TME_Temperatur_Ruecklauf_VKM 254;
BA_ "GenSigSendType" SG_ 1657 TME_Temperatur_Ruecklauf_VKM 0;
BA_ "Fehlerwert" SG_ 2463978655 TME_Senkenleistung_verfuegbar 511;
BA_ "GenSigSwitchedByIgnition" SG_ 2463978655 TME_Senkenleistung_verfuegbar 0;
BA_ "GenSigStartValue" SG_ 2463978655 TME_Senkenleistung_verfuegbar 510;
BA_ "GenSigSendType" SG_ 2463978655 TME_Senkenleistung_verfuegbar 0;
BA_ "Fehlerwert" SG_ 2589283463 TME_THMTVLV_Sollstellung 127;
BA_ "GenSigSwitchedByIgnition" SG_ 2589283463 TME_THMTVLV_Sollstellung 0;
BA_ "GenSigStartValue" SG_ 2589283463 TME_THMTVLV_Sollstellung 126;
BA_ "GenSigSendType" SG_ 2589283463 TME_THMTVLV_Sollstellung 0;
BA_ "Fehlerwert" SG_ 2589283463 TME_Mischventil_Heizkreis_Ist 127;
BA_ "GenSigSwitchedByIgnition" SG_ 2589283463 TME_Mischventil_Heizkreis_Ist 0;
BA_ "GenSigStartValue" SG_ 2589283463 TME_Mischventil_Heizkreis_Ist 126;
BA_ "GenSigSendType" SG_ 2589283463 TME_Mischventil_Heizkreis_Ist 0;
BA_ "GenSigSwitchedByIgnition" SG_ 2589283463 TME_Ionenspuelung_aktiv 0;
BA_ "GenSigSendType" SG_ 2589283463 TME_Ionenspuelung_aktiv 0;
BA_ "Fehlerwert" SG_ 2589283463 TME_Temp_KM_v_Pumpe_Heizkreis 255;
BA_ "GenSigSwitchedByIgnition" SG_ 2589283463 TME_Temp_KM_v_Pumpe_Heizkreis 0;
BA_ "GenSigStartValue" SG_ 2589283463 TME_Temp_KM_v_Pumpe_Heizkreis 254;
BA_ "GenSigSendType" SG_ 2589283463 TME_Temp_KM_v_Pumpe_Heizkreis 0;
BA_ "Fehlerwert" SG_ 2589283463 TME_Temp_KM_n_Mischventil_Heizkr 255;
BA_ "GenSigSwitchedByIgnition" SG_ 2589283463 TME_Temp_KM_n_Mischventil_Heizkr 0;
BA_ "GenSigStartValue" SG_ 2589283463 TME_Temp_KM_n_Mischventil_Heizkr 254;
BA_ "GenSigSendType" SG_ 2589283463 TME_Temp_KM_n_Mischventil_Heizkr 0;
BA_ "GenSigSwitchedByIgnition" SG_ 2589283463 TME_Befuellung_aktiv 0;
BA_ "GenSigSendType" SG_ 2589283463 TME_Befuellung_aktiv 0;
BA_ "GenSigSwitchedByIgnition" SG_ 2589283463 TME_Entlueftung_aktiv 0;
BA_ "GenSigSendType" SG_ 2589283463 TME_Entlueftung_aktiv 0;
BA_ "Fehlerwert" SG_ 2589283463 TME_KMP_Solldrehzahl 16383;
BA_ "GenSigSwitchedByIgnition" SG_ 2589283463 TME_KMP_Solldrehzahl 0;
BA_ "GenSigStartValue" SG_ 2589283463 TME_KMP_Solldrehzahl 16382;
BA_ "GenSigSendType" SG_ 2589283463 TME_KMP_Solldrehzahl 0;
BA_ "GenSigSwitchedByIgnition" SG_ 2589283408 SKE1_AOCCT_timer1_count 0;
BA_ "GenSigSendType" SG_ 2589283408 SKE1_AOCCT_timer1_count 0;
BA_ "GenSigSwitchedByIgnition" SG_ 2589283408 SKE1_AOCCT_timer2_count 0;
BA_ "GenSigSendType" SG_ 2589283408 SKE1_AOCCT_timer2_count 0;
BA_ "GenSigSwitchedByIgnition" SG_ 2589283408 SKE1_AOCCT_teststatus 0;
BA_ "GenSigSendType" SG_ 2589283408 SKE1_AOCCT_teststatus 0;
BA_ "GenSigSwitchedByIgnition" SG_ 2589283408 SKE2_AOCCT_timer1_verbaut 0;
BA_ "GenSigSendType" SG_ 2589283408 SKE2_AOCCT_timer1_verbaut 0;
BA_ "GenSigSwitchedByIgnition" SG_ 2589283408 SKE2_AOCCT_timer1_count 0;
BA_ "GenSigSendType" SG_ 2589283408 SKE2_AOCCT_timer1_count 0;
BA_ "GenSigSwitchedByIgnition" SG_ 2589283408 SKE2_AOCCT_timer2_verbaut 0;
BA_ "GenSigSendType" SG_ 2589283408 SKE2_AOCCT_timer2_verbaut 0;
BA_ "GenSigSwitchedByIgnition" SG_ 2589283408 SKE2_AOCCT_timer2_count 0;
BA_ "GenSigSendType" SG_ 2589283408 SKE2_AOCCT_timer2_count 0;
BA_ "GenSigSwitchedByIgnition" SG_ 2589283408 SKE2_AOCCT_fehlerstatus 0;
BA_ "GenSigSendType" SG_ 2589283408 SKE2_AOCCT_fehlerstatus 0;
BA_ "GenSigSwitchedByIgnition" SG_ 2589283408 SKE2_AOCCT_teststatus 0;
BA_ "GenSigSendType" SG_ 2589283408 SKE2_AOCCT_teststatus 0;
BA_ "GenSigSwitchedByIgnition" SG_ 2589283408 SKE1_AOCCT_timer1_verbaut 0;
BA_ "GenSigSendType" SG_ 2589283408 SKE1_AOCCT_timer1_verbaut 0;
BA_ "GenSigSwitchedByIgnition" SG_ 2589283408 SKE1_AOCCT_fehlerstatus 0;
BA_ "GenSigSendType" SG_ 2589283408 SKE1_AOCCT_fehlerstatus 0;
BA_ "GenSigSwitchedByIgnition" SG_ 2589283408 SKE1_AOCCT_timer2_verbaut 0;
BA_ "GenSigSendType" SG_ 2589283408 SKE1_AOCCT_timer2_verbaut 0;
BA_ "Fehlerwert" SG_ 2527679716 TME_ThermoPred_P_dyn_BTL_FP1 511;
BA_ "GenSigSwitchedByIgnition" SG_ 2527679716 TME_ThermoPred_P_dyn_BTL_FP1 0;
BA_ "GenSigStartValue" SG_ 2527679716 TME_ThermoPred_P_dyn_BTL_FP1 510;
BA_ "GenSigSendType" SG_ 2527679716 TME_ThermoPred_P_dyn_BTL_FP1 0;
BA_ "GenSigSwitchedByIgnition" SG_ 2527679716 TME_Pred_BTLSys_Anf_FP1 0;
BA_ "GenSigSendType" SG_ 2527679716 TME_Pred_BTLSys_Anf_FP1 0;
BA_ "GenSigSwitchedByIgnition" SG_ 2527679716 TME_Pred_KlimaSys_Anf_FP1 0;
BA_ "GenSigSendType" SG_ 2527679716 TME_Pred_KlimaSys_Anf_FP1 0;
BA_ "GenSigSwitchedByIgnition" SG_ 2527679716 TME_Pred_KlimaKunde_Anf_FP1 0;
BA_ "GenSigSendType" SG_ 2527679716 TME_Pred_KlimaKunde_Anf_FP1 0;
BA_ "Fehlerwert" SG_ 2527679716 TME_ThermoPred_P_stat_Klima_FP1 2047;
BA_ "GenSigSwitchedByIgnition" SG_ 2527679716 TME_ThermoPred_P_stat_Klima_FP1 0;
BA_ "GenSigStartValue" SG_ 2527679716 TME_ThermoPred_P_stat_Klima_FP1 2046;
BA_ "GenSigSendType" SG_ 2527679716 TME_ThermoPred_P_stat_Klima_FP1 0;
BA_ "Fehlerwert" SG_ 2527679716 TME_ThermoPred_P_dyn_Klima_FP1 2047;
BA_ "GenSigSwitchedByIgnition" SG_ 2527679716 TME_ThermoPred_P_dyn_Klima_FP1 0;
BA_ "GenSigStartValue" SG_ 2527679716 TME_ThermoPred_P_dyn_Klima_FP1 2046;
BA_ "GenSigSendType" SG_ 2527679716 TME_ThermoPred_P_dyn_Klima_FP1 0;
BA_ "Fehlerwert" SG_ 2527679716 TME_ThermoPred_T_dyn_BTL_FP1 255;
BA_ "GenSigSwitchedByIgnition" SG_ 2527679716 TME_ThermoPred_T_dyn_BTL_FP1 0;
BA_ "GenSigStartValue" SG_ 2527679716 TME_ThermoPred_T_dyn_BTL_FP1 254;
BA_ "GenSigSendType" SG_ 2527679716 TME_ThermoPred_T_dyn_BTL_FP1 0;
BA_ "Fehlerwert" SG_ 2527679716 TME_ThermoPred_T_dyn_Klima_FP1 255;
BA_ "GenSigSwitchedByIgnition" SG_ 2527679716 TME_ThermoPred_T_dyn_Klima_FP1 0;
BA_ "GenSigStartValue" SG_ 2527679716 TME_ThermoPred_T_dyn_Klima_FP1 254;
BA_ "GenSigSendType" SG_ 2527679716 TME_ThermoPred_T_dyn_Klima_FP1 0;
BA_ "Fehlerwert" SG_ 2527679717 TME_ThermoPred_P_dyn_BTL_FP2 511;
BA_ "GenSigSwitchedByIgnition" SG_ 2527679717 TME_ThermoPred_P_dyn_BTL_FP2 0;
BA_ "GenSigStartValue" SG_ 2527679717 TME_ThermoPred_P_dyn_BTL_FP2 510;
BA_ "GenSigSendType" SG_ 2527679717 TME_ThermoPred_P_dyn_BTL_FP2 0;
BA_ "GenSigSwitchedByIgnition" SG_ 2527679717 TME_Pred_BTLSys_Anf_FP2 0;
BA_ "GenSigSendType" SG_ 2527679717 TME_Pred_BTLSys_Anf_FP2 0;
BA_ "GenSigSwitchedByIgnition" SG_ 2527679717 TME_Pred_KlimaSys_Anf_FP2 0;
BA_ "GenSigSendType" SG_ 2527679717 TME_Pred_KlimaSys_Anf_FP2 0;
BA_ "GenSigSwitchedByIgnition" SG_ 2527679717 TME_Pred_KlimaKunde_Anf_FP2 0;
BA_ "GenSigSendType" SG_ 2527679717 TME_Pred_KlimaKunde_Anf_FP2 0;
BA_ "Fehlerwert" SG_ 2527679717 TME_ThermoPred_P_stat_Klima_FP2 2047;
BA_ "GenSigSwitchedByIgnition" SG_ 2527679717 TME_ThermoPred_P_stat_Klima_FP2 0;
BA_ "GenSigStartValue" SG_ 2527679717 TME_ThermoPred_P_stat_Klima_FP2 2046;
BA_ "GenSigSendType" SG_ 2527679717 TME_ThermoPred_P_stat_Klima_FP2 0;
BA_ "Fehlerwert" SG_ 2527679717 TME_ThermoPred_P_dyn_Klima_FP2 2047;
BA_ "GenSigSwitchedByIgnition" SG_ 2527679717 TME_ThermoPred_P_dyn_Klima_FP2 0;
BA_ "GenSigStartValue" SG_ 2527679717 TME_ThermoPred_P_dyn_Klima_FP2 2046;
BA_ "GenSigSendType" SG_ 2527679717 TME_ThermoPred_P_dyn_Klima_FP2 0;
BA_ "Fehlerwert" SG_ 2527679717 TME_ThermoPred_T_dyn_BTL_FP2 255;
BA_ "GenSigSwitchedByIgnition" SG_ 2527679717 TME_ThermoPred_T_dyn_BTL_FP2 0;
BA_ "GenSigStartValue" SG_ 2527679717 TME_ThermoPred_T_dyn_BTL_FP2 254;
BA_ "GenSigSendType" SG_ 2527679717 TME_ThermoPred_T_dyn_BTL_FP2 0;
BA_ "Fehlerwert" SG_ 2527679717 TME_ThermoPred_T_dyn_Klima_FP2 255;
BA_ "GenSigSwitchedByIgnition" SG_ 2527679717 TME_ThermoPred_T_dyn_Klima_FP2 0;
BA_ "GenSigStartValue" SG_ 2527679717 TME_ThermoPred_T_dyn_Klima_FP2 254;
BA_ "GenSigSendType" SG_ 2527679717 TME_ThermoPred_T_dyn_Klima_FP2 0;
BA_ "Fehlerwert" SG_ 2527679718 TME_ThermoPred_P_dyn_BTL_FP3 511;
BA_ "GenSigSwitchedByIgnition" SG_ 2527679718 TME_ThermoPred_P_dyn_BTL_FP3 0;
BA_ "GenSigStartValue" SG_ 2527679718 TME_ThermoPred_P_dyn_BTL_FP3 510;
BA_ "GenSigSendType" SG_ 2527679718 TME_ThermoPred_P_dyn_BTL_FP3 0;
BA_ "GenSigSwitchedByIgnition" SG_ 2527679718 TME_Pred_BTLSys_Anf_FP3 0;
BA_ "GenSigSendType" SG_ 2527679718 TME_Pred_BTLSys_Anf_FP3 0;
BA_ "GenSigSwitchedByIgnition" SG_ 2527679718 TME_Pred_KlimaSys_Anf_FP3 0;
BA_ "GenSigSendType" SG_ 2527679718 TME_Pred_KlimaSys_Anf_FP3 0;
BA_ "GenSigSwitchedByIgnition" SG_ 2527679718 TME_Pred_KlimaKunde_Anf_FP3 0;
BA_ "GenSigSendType" SG_ 2527679718 TME_Pred_KlimaKunde_Anf_FP3 0;
BA_ "Fehlerwert" SG_ 2527679718 TME_ThermoPred_P_stat_Klima_FP3 2047;
BA_ "GenSigSwitchedByIgnition" SG_ 2527679718 TME_ThermoPred_P_stat_Klima_FP3 0;
BA_ "GenSigStartValue" SG_ 2527679718 TME_ThermoPred_P_stat_Klima_FP3 2046;
BA_ "GenSigSendType" SG_ 2527679718 TME_ThermoPred_P_stat_Klima_FP3 0;
BA_ "Fehlerwert" SG_ 2527679718 TME_ThermoPred_P_dyn_Klima_FP3 2047;
BA_ "GenSigSwitchedByIgnition" SG_ 2527679718 TME_ThermoPred_P_dyn_Klima_FP3 0;
BA_ "GenSigStartValue" SG_ 2527679718 TME_ThermoPred_P_dyn_Klima_FP3 2046;
BA_ "GenSigSendType" SG_ 2527679718 TME_ThermoPred_P_dyn_Klima_FP3 0;
BA_ "Fehlerwert" SG_ 2527679718 TME_ThermoPred_T_dyn_BTL_FP3 255;
BA_ "GenSigSwitchedByIgnition" SG_ 2527679718 TME_ThermoPred_T_dyn_BTL_FP3 0;
BA_ "GenSigStartValue" SG_ 2527679718 TME_ThermoPred_T_dyn_BTL_FP3 254;
BA_ "GenSigSendType" SG_ 2527679718 TME_ThermoPred_T_dyn_BTL_FP3 0;
BA_ "Fehlerwert" SG_ 2527679718 TME_ThermoPred_T_dyn_Klima_FP3 255;
BA_ "GenSigSwitchedByIgnition" SG_ 2527679718 TME_ThermoPred_T_dyn_Klima_FP3 0;
BA_ "GenSigStartValue" SG_ 2527679718 TME_ThermoPred_T_dyn_Klima_FP3 254;
BA_ "GenSigSendType" SG_ 2527679718 TME_ThermoPred_T_dyn_Klima_FP3 0;
BA_ "GenSigSwitchedByIgnition" SG_ 2463978733 TME_ThermoPred_BTL_System_Anf 0;
BA_ "GenSigSendType" SG_ 2463978733 TME_ThermoPred_BTL_System_Anf 0;
BA_ "Fehlerwert" SG_ 2463978733 TME_ThermoPred_P_dyn_Btl 511;
BA_ "GenSigSwitchedByIgnition" SG_ 2463978733 TME_ThermoPred_P_dyn_Btl 0;
BA_ "GenSigStartValue" SG_ 2463978733 TME_ThermoPred_P_dyn_Btl 510;
BA_ "GenSigSendType" SG_ 2463978733 TME_ThermoPred_P_dyn_Btl 0;
BA_ "Fehlerwert" SG_ 2463978733 TME_ThermoPred_T_dyn_Btl 255;
BA_ "GenSigSwitchedByIgnition" SG_ 2463978733 TME_ThermoPred_T_dyn_Btl 0;
BA_ "GenSigStartValue" SG_ 2463978733 TME_ThermoPred_T_dyn_Btl 254;
BA_ "GenSigSendType" SG_ 2463978733 TME_ThermoPred_T_dyn_Btl 0;
BA_ "GenSigSwitchedByIgnition" SG_ 977 BT_Tuer_geoeffnet 0;
BA_ "GenSigSendType" SG_ 977 BT_Tuer_geoeffnet 3;
BA_ "GenSigSwitchedByIgnition" SG_ 977 BT_verriegelt 0;
BA_ "GenSigSendType" SG_ 977 BT_verriegelt 3;
BA_ "GenSigSwitchedByIgnition" SG_ 977 BT_gesafet 0;
BA_ "GenSigSendType" SG_ 977 BT_gesafet 3;
BA_ "GenSigSwitchedByIgnition" SG_ 977 BT_Schluesselschalter_auf 0;
BA_ "GenSigSendType" SG_ 977 BT_Schluesselschalter_auf 3;
BA_ "GenSigSwitchedByIgnition" SG_ 977 BT_Schluesselschalter_zu 0;
BA_ "GenSigSendType" SG_ 977 BT_Schluesselschalter_zu 3;
BA_ "GenSigSwitchedByIgnition" SG_ 977 BT_Unlock_Taster 0;
BA_ "GenSigSendType" SG_ 977 BT_Unlock_Taster 3;
BA_ "GenSigSwitchedByIgnition" SG_ 977 BT_Lock_Taster 0;
BA_ "GenSigSendType" SG_ 977 BT_Lock_Taster 3;
BA_ "GenSigSwitchedByIgnition" SG_ 977 BT_Sperrklinke 0;
BA_ "GenSigSendType" SG_ 977 BT_Sperrklinke 3;
BA_ "GenSigSwitchedByIgnition" SG_ 977 BT_TAG_betaetigt 0;
BA_ "GenSigSendType" SG_ 977 BT_TAG_betaetigt 3;
BA_ "GenSigSwitchedByIgnition" SG_ 977 BT_TIG_betaetigt 0;
BA_ "GenSigSendType" SG_ 977 BT_TIG_betaetigt 3;
BA_ "GenSigSwitchedByIgnition" SG_ 977 BT_EC_Spiegel_Helligkeit 0;
BA_ "GenSigSendType" SG_ 977 BT_EC_Spiegel_Helligkeit 3;
BA_ "GenSigSwitchedByIgnition" SG_ 977 BT_Sp_Heizung_Anf 0;
BA_ "GenSigSendType" SG_ 977 BT_Sp_Heizung_Anf 0;
BA_ "Fehlerwert" SG_ 977 BT_Tuer_Status 3;
BA_ "GenSigSwitchedByIgnition" SG_ 977 BT_Tuer_Status 0;
BA_ "GenSigSendType" SG_ 977 BT_Tuer_Status 3;
BA_ "GenSigSwitchedByIgnition" SG_ 977 BT_TSG_hinten_verbaut 0;
BA_ "GenSigSendType" SG_ 977 BT_TSG_hinten_verbaut 3;
BA_ "GenSigSwitchedByIgnition" SG_ 977 BT_Sp_Blk_def 0;
BA_ "GenSigSendType" SG_ 977 BT_Sp_Blk_def 3;
BA_ "GenSigSwitchedByIgnition" SG_ 977 BT_FH_S_ManHoch 0;
BA_ "GenSigSendType" SG_ 977 BT_FH_S_ManHoch 3;
BA_ "GenSigSwitchedByIgnition" SG_ 977 BT_FH_S_AutoHoch 0;
BA_ "GenSigSendType" SG_ 977 BT_FH_S_AutoHoch 3;
BA_ "GenSigSwitchedByIgnition" SG_ 977 BT_FH_S_ManTief 0;
BA_ "GenSigSendType" SG_ 977 BT_FH_S_ManTief 3;
BA_ "GenSigSwitchedByIgnition" SG_ 977 BT_FH_S_AutoTief 0;
BA_ "GenSigSendType" SG_ 977 BT_FH_S_AutoTief 3;
BA_ "GenSigSwitchedByIgnition" SG_ 977 BT_FH_Oeffnung 0;
BA_ "GenSigSendType" SG_ 977 BT_FH_Oeffnung 3;
BA_ "GenSigSwitchedByIgnition" SG_ 977 BT_FH_Bew_hoch 0;
BA_ "GenSigSendType" SG_ 977 BT_FH_Bew_hoch 3;
BA_ "GenSigSwitchedByIgnition" SG_ 977 BT_FH_Bew_tief 0;
BA_ "GenSigSendType" SG_ 977 BT_FH_Bew_tief 3;
BA_ "GenSigSwitchedByIgnition" SG_ 977 BT_FH_Fang 0;
BA_ "GenSigSendType" SG_ 977 BT_FH_Fang 3;
BA_ "GenSigSwitchedByIgnition" SG_ 977 BT_FH_Block 0;
BA_ "GenSigSendType" SG_ 977 BT_FH_Block 3;
BA_ "GenSigSwitchedByIgnition" SG_ 977 BT_FH_Thermo 0;
BA_ "GenSigSendType" SG_ 977 BT_FH_Thermo 3;
BA_ "GenSigSwitchedByIgnition" SG_ 977 BT_UEKB_aktiviert 0;
BA_ "GenSigSendType" SG_ 977 BT_UEKB_aktiviert 3;
BA_ "Fehlerwert" SG_ 977 BT_Kisi_Fehler 1;
BA_ "GenSigSwitchedByIgnition" SG_ 977 BT_Kisi_Fehler 0;
BA_ "GenSigSendType" SG_ 977 BT_Kisi_Fehler 3;
BA_ "GenSigSwitchedByIgnition" SG_ 977 BT_FH_normiert 0;
BA_ "GenSigSendType" SG_ 977 BT_FH_normiert 3;
BA_ "GenSigSwitchedByIgnition" SG_ 977 BT_Schliesstaster 0;
BA_ "GenSigSendType" SG_ 977 BT_Schliesstaster 3;
BA_ "GenSigSwitchedByIgnition" SG_ 977 BT_Zuziehhilfe_aktiv 0;
BA_ "GenSigSendType" SG_ 977 BT_Zuziehhilfe_aktiv 3;
BA_ "GenSigSwitchedByIgnition" SG_ 977 BT_SP_ausgerastet 0;
BA_ "GenSigSendType" SG_ 977 BT_SP_ausgerastet 3;
BA_ "GenSigSwitchedByIgnition" SG_ 977 BT_SP_lr_aktiv 0;
BA_ "GenSigSendType" SG_ 977 BT_SP_lr_aktiv 3;
BA_ "GenSigSwitchedByIgnition" SG_ 977 BT_SP_ht_aktiv 0;
BA_ "GenSigSendType" SG_ 977 BT_SP_ht_aktiv 3;
BA_ "GenSigSendType" SG_ 977 BT_SP_Heizung_aktiv 3;
BA_ "GenSigSwitchedByIgnition" SG_ 977 BT_Oben_Block_erw 0;
BA_ "GenSigSendType" SG_ 977 BT_Oben_Block_erw 3;
BA_ "GenSigSwitchedByIgnition" SG_ 977 BT_Unten_Block_erw 0;
BA_ "GenSigSendType" SG_ 977 BT_Unten_Block_erw 3;
BA_ "GenSigSwitchedByIgnition" SG_ 977 BT_Tuer_Status_QBit 0;
BA_ "GenSigSendType" SG_ 977 BT_Tuer_Status_QBit 0;
BA_ "Fehlerwert" SG_ 977 BFS_Status_eTAG 3;
BA_ "GenSigSwitchedByIgnition" SG_ 977 BFS_Status_eTAG 0;
BA_ "GenSigSendType" SG_ 977 BFS_Status_eTAG 0;
BA_ "GenSigSwitchedByIgnition" SG_ 977 BT_TCR_Mode_aktiv 0;
BA_ "GenSigSendType" SG_ 977 BT_TCR_Mode_aktiv 0;
BA_ "GenSigSwitchedByIgnition" SG_ 977 BT_SP_Heizung_Status 0;
BA_ "GenSigSendType" SG_ 977 BT_SP_Heizung_Status 3;
BA_ "GenSigSwitchedByIgnition" SG_ 977 ASW_Warnung_aktiv_BFS 0;
BA_ "GenSigSendType" SG_ 977 ASW_Warnung_aktiv_BFS 3;
BA_ "GenSigSwitchedByIgnition" SG_ 977 BT_FH_Pos_oben 0;
BA_ "GenSigSendType" SG_ 977 BT_FH_Pos_oben 3;
BA_ "GenSigSwitchedByIgnition" SG_ 977 BT_Tuerschloss_defekt 0;
BA_ "GenSigSendType" SG_ 977 BT_Tuerschloss_defekt 0;
BA_ "GenSigSwitchedByIgnition" SG_ 977 BT_Tueroeffnen_Warnung 0;
BA_ "GenSigSendType" SG_ 977 BT_Tueroeffnen_Warnung 3;
BA_ "GenSigSwitchedByIgnition" SG_ 977 BT_Lock_Taster_inv 0;
BA_ "GenSigSendType" SG_ 977 BT_Lock_Taster_inv 3;
BA_ "GenSigSwitchedByIgnition" SG_ 977 BT_Schluesselschalter_zu_inv 0;
BA_ "GenSigSendType" SG_ 977 BT_Schluesselschalter_zu_inv 3;
BA_ "GenSigSwitchedByIgnition" SG_ 977 BT_SWA_HMI_defekt 0;
BA_ "GenSigSendType" SG_ 977 BT_SWA_HMI_defekt 0;
BA_ "GenSigSwitchedByIgnition" SG_ 977 BT_ASW_HMI_defekt 0;
BA_ "GenSigSendType" SG_ 977 BT_ASW_HMI_defekt 0;
BA_ "GenSigSwitchedByIgnition" SG_ 976 FT_Tuer_geoeffnet 0;
BA_ "GenSigSendType" SG_ 976 FT_Tuer_geoeffnet 3;
BA_ "GenSigSwitchedByIgnition" SG_ 976 FT_verriegelt 0;
BA_ "GenSigSendType" SG_ 976 FT_verriegelt 3;
BA_ "GenSigSwitchedByIgnition" SG_ 976 FT_gesafet 0;
BA_ "GenSigSendType" SG_ 976 FT_gesafet 3;
BA_ "GenSigSwitchedByIgnition" SG_ 976 FT_Schluesselschalter_auf 0;
BA_ "GenSigSendType" SG_ 976 FT_Schluesselschalter_auf 3;
BA_ "GenSigSwitchedByIgnition" SG_ 976 FT_Schluesselschalter_zu 0;
BA_ "GenSigSendType" SG_ 976 FT_Schluesselschalter_zu 3;
BA_ "GenSigSwitchedByIgnition" SG_ 976 FT_Unlock_Taster 0;
BA_ "GenSigSendType" SG_ 976 FT_Unlock_Taster 3;
BA_ "GenSigSwitchedByIgnition" SG_ 976 FT_Lock_Taster 0;
BA_ "GenSigSendType" SG_ 976 FT_Lock_Taster 3;
BA_ "GenSigSwitchedByIgnition" SG_ 976 FT_Sperrklinke 0;
BA_ "GenSigSendType" SG_ 976 FT_Sperrklinke 3;
BA_ "GenSigSwitchedByIgnition" SG_ 976 FT_TAG_betaetigt 0;
BA_ "GenSigSendType" SG_ 976 FT_TAG_betaetigt 3;
BA_ "GenSigSwitchedByIgnition" SG_ 976 FT_TIG_betaetigt 0;
BA_ "GenSigSendType" SG_ 976 FT_TIG_betaetigt 3;
BA_ "GenSigSwitchedByIgnition" SG_ 976 FT_IRUE_Taste 0;
BA_ "GenSigSendType" SG_ 976 FT_IRUE_Taste 3;
BA_ "GenSigSwitchedByIgnition" SG_ 976 FT_HD_Taste 0;
BA_ "GenSigSendType" SG_ 976 FT_HD_Taste 3;
BA_ "GenSigSwitchedByIgnition" SG_ 976 FT_TD_Taste_Fehler 0;
BA_ "GenSigSendType" SG_ 976 FT_TD_Taste_Fehler 0;
BA_ "GenSigSwitchedByIgnition" SG_ 976 FT_TD_Taste 0;
BA_ "GenSigSendType" SG_ 976 FT_TD_Taste 3;
BA_ "GenSigSwitchedByIgnition" SG_ 976 SSR_Temp_Freigabe 0;
BA_ "GenSigSendType" SG_ 976 SSR_Temp_Freigabe 0;
BA_ "GenSigSwitchedByIgnition" SG_ 976 FT_Sp_Heizung_Anf 0;
BA_ "GenSigSendType" SG_ 976 FT_Sp_Heizung_Anf 0;
BA_ "GenSigSwitchedByIgnition" SG_ 976 FT_HD_Taste_2 0;
BA_ "GenSigSendType" SG_ 976 FT_HD_Taste_2 3;
BA_ "GenSigSwitchedByIgnition" SG_ 976 FT_TSG_hinten_verbaut 0;
BA_ "GenSigSendType" SG_ 976 FT_TSG_hinten_verbaut 3;
BA_ "GenSigSwitchedByIgnition" SG_ 976 FT_Sp_Blk_def 0;
BA_ "GenSigSendType" SG_ 976 FT_Sp_Blk_def 3;
BA_ "GenSigSwitchedByIgnition" SG_ 976 FT_FH_S_ManHoch 0;
BA_ "GenSigSendType" SG_ 976 FT_FH_S_ManHoch 3;
BA_ "GenSigSwitchedByIgnition" SG_ 976 FT_FH_S_AutoHoch 0;
BA_ "GenSigSendType" SG_ 976 FT_FH_S_AutoHoch 3;
BA_ "GenSigSwitchedByIgnition" SG_ 976 FT_FH_S_ManTief 0;
BA_ "GenSigSendType" SG_ 976 FT_FH_S_ManTief 3;
BA_ "GenSigSwitchedByIgnition" SG_ 976 FT_FH_S_AutoTief 0;
BA_ "GenSigSendType" SG_ 976 FT_FH_S_AutoTief 3;
BA_ "GenSigSwitchedByIgnition" SG_ 976 FT_FH_Oeffnung 0;
BA_ "GenSigSendType" SG_ 976 FT_FH_Oeffnung 3;
BA_ "GenSigSwitchedByIgnition" SG_ 976 FT_FH_Bew_hoch 0;
BA_ "GenSigSendType" SG_ 976 FT_FH_Bew_hoch 3;
BA_ "GenSigSwitchedByIgnition" SG_ 976 FT_FH_Bew_tief 0;
BA_ "GenSigSendType" SG_ 976 FT_FH_Bew_tief 3;
BA_ "GenSigSwitchedByIgnition" SG_ 976 FT_FH_Fang 0;
BA_ "GenSigSendType" SG_ 976 FT_FH_Fang 3;
BA_ "GenSigSwitchedByIgnition" SG_ 976 FT_FH_Block 0;
BA_ "GenSigSendType" SG_ 976 FT_FH_Block 3;
BA_ "GenSigSwitchedByIgnition" SG_ 976 FT_FH_Thermo 0;
BA_ "GenSigSendType" SG_ 976 FT_FH_Thermo 3;
BA_ "GenSigSwitchedByIgnition" SG_ 976 FT_UEKB_aktiviert 0;
BA_ "GenSigSendType" SG_ 976 FT_UEKB_aktiviert 3;
BA_ "GenSigSwitchedByIgnition" SG_ 976 ASW_HMI_defekt 0;
BA_ "GenSigSendType" SG_ 976 ASW_HMI_defekt 0;
BA_ "GenSigSwitchedByIgnition" SG_ 976 FT_FH_normiert 0;
BA_ "GenSigSendType" SG_ 976 FT_FH_normiert 3;
BA_ "GenSigSwitchedByIgnition" SG_ 976 FT_Schliesstaster 0;
BA_ "GenSigSendType" SG_ 976 FT_Schliesstaster 3;
BA_ "GenSigSwitchedByIgnition" SG_ 976 FT_Zuziehhilfe_aktiv 0;
BA_ "GenSigSendType" SG_ 976 FT_Zuziehhilfe_aktiv 3;
BA_ "GenSigSwitchedByIgnition" SG_ 976 FT_SP_ausgerastet 0;
BA_ "GenSigSendType" SG_ 976 FT_SP_ausgerastet 3;
BA_ "GenSigSwitchedByIgnition" SG_ 976 FT_SP_lr_aktiv 0;
BA_ "GenSigSendType" SG_ 976 FT_SP_lr_aktiv 3;
BA_ "GenSigSwitchedByIgnition" SG_ 976 FT_SP_ht_aktiv 0;
BA_ "GenSigSendType" SG_ 976 FT_SP_ht_aktiv 3;
BA_ "GenSigSwitchedByIgnition" SG_ 976 ASW_wakeup 0;
BA_ "GenSigSendType" SG_ 976 ASW_wakeup 3;
BA_ "GenSigSwitchedByIgnition" SG_ 976 FT_Oben_Block_erw 0;
BA_ "GenSigSendType" SG_ 976 FT_Oben_Block_erw 3;
BA_ "GenSigSwitchedByIgnition" SG_ 976 FT_Unten_Block_erw 0;
BA_ "GenSigSendType" SG_ 976 FT_Unten_Block_erw 3;
BA_ "GenSigSwitchedByIgnition" SG_ 976 FT_Kisi_li_aktiv 0;
BA_ "GenSigSendType" SG_ 976 FT_Kisi_li_aktiv 3;
BA_ "GenSigSwitchedByIgnition" SG_ 976 FT_Kisi_re_aktiv 0;
BA_ "GenSigSendType" SG_ 976 FT_Kisi_re_aktiv 3;
BA_ "GenSigSwitchedByIgnition" SG_ 976 FT_Kisi_Taster_li 0;
BA_ "GenSigSendType" SG_ 976 FT_Kisi_Taster_li 3;
BA_ "GenSigSwitchedByIgnition" SG_ 976 FT_Kisi_Taster_re 0;
BA_ "GenSigSendType" SG_ 976 FT_Kisi_Taster_re 3;
BA_ "GenSigSwitchedByIgnition" SG_ 976 FT_BFS_Fond_Freigabe 0;
BA_ "GenSigSendType" SG_ 976 FT_BFS_Fond_Freigabe 3;
BA_ "Fehlerwert" SG_ 976 FT_Kisi_Fehler 1;
BA_ "GenSigSwitchedByIgnition" SG_ 976 FT_Kisi_Fehler 0;
BA_ "GenSigSendType" SG_ 976 FT_Kisi_Fehler 3;
BA_ "GenSigSwitchedByIgnition" SG_ 976 FT_Daemmglas 0;
BA_ "GenSigSendType" SG_ 976 FT_Daemmglas 3;
BA_ "GenSigSwitchedByIgnition" SG_ 976 FT_SP_Heizung_Status 0;
BA_ "GenSigSendType" SG_ 976 FT_SP_Heizung_Status 3;
BA_ "GenSigSwitchedByIgnition" SG_ 976 ASW_Warnung_aktiv_FS 0;
BA_ "GenSigSendType" SG_ 976 ASW_Warnung_aktiv_FS 3;
BA_ "GenSigSwitchedByIgnition" SG_ 976 FT_FH_Pos_oben 0;
BA_ "GenSigSendType" SG_ 976 FT_FH_Pos_oben 3;
BA_ "GenSigSwitchedByIgnition" SG_ 976 FT_Tuerschloss_defekt 0;
BA_ "GenSigSendType" SG_ 976 FT_Tuerschloss_defekt 0;
BA_ "GenSigSwitchedByIgnition" SG_ 976 FT_SWA_Taster 0;
BA_ "GenSigSendType" SG_ 976 FT_SWA_Taster 3;
BA_ "GenSigSwitchedByIgnition" SG_ 976 SWA_HMI_Diagnose 0;
BA_ "GenSigSendType" SG_ 976 SWA_HMI_Diagnose 0;
BA_ "Fehlerwert" SG_ 976 FS_Status_eTAG 3;
BA_ "GenSigSwitchedByIgnition" SG_ 976 FS_Status_eTAG 0;
BA_ "GenSigSendType" SG_ 976 FS_Status_eTAG 3;
BA_ "GenSigSwitchedByIgnition" SG_ 975 HBFS_Tuer_geoeffnet 0;
BA_ "GenSigSendType" SG_ 975 HBFS_Tuer_geoeffnet 3;
BA_ "GenSigSwitchedByIgnition" SG_ 975 HBFS_verriegelt 0;
BA_ "GenSigSendType" SG_ 975 HBFS_verriegelt 3;
BA_ "GenSigSwitchedByIgnition" SG_ 975 HBFS_gesafet 0;
BA_ "GenSigSendType" SG_ 975 HBFS_gesafet 3;
BA_ "GenSigSwitchedByIgnition" SG_ 975 HBFS_Heckrollotaster_betaetigt 0;
BA_ "GenSigSendType" SG_ 975 HBFS_Heckrollotaster_betaetigt 3;
BA_ "GenSigSwitchedByIgnition" SG_ 975 HBFS_Tuerschloss_defekt 0;
BA_ "GenSigSendType" SG_ 975 HBFS_Tuerschloss_defekt 0;
BA_ "GenSigSwitchedByIgnition" SG_ 975 HBFS_Unlock_Taster 0;
BA_ "GenSigSendType" SG_ 975 HBFS_Unlock_Taster 3;
BA_ "GenSigSwitchedByIgnition" SG_ 975 HBFS_Lock_Taster 0;
BA_ "GenSigSendType" SG_ 975 HBFS_Lock_Taster 3;
BA_ "GenSigSwitchedByIgnition" SG_ 975 HBFS_Sperrklinke 0;
BA_ "GenSigSendType" SG_ 975 HBFS_Sperrklinke 3;
BA_ "GenSigSwitchedByIgnition" SG_ 975 HBFS_TAG_betaetigt 0;
BA_ "GenSigSendType" SG_ 975 HBFS_TAG_betaetigt 3;
BA_ "GenSigSwitchedByIgnition" SG_ 975 HBFS_TIG_betaetigt 0;
BA_ "GenSigSendType" SG_ 975 HBFS_TIG_betaetigt 3;
BA_ "GenSigSwitchedByIgnition" SG_ 975 HBFS_FH_S_HFS_AutoHoch 0;
BA_ "GenSigSendType" SG_ 975 HBFS_FH_S_HFS_AutoHoch 3;
BA_ "GenSigSwitchedByIgnition" SG_ 975 HBFS_FH_S_HFS_AutoTief 0;
BA_ "GenSigSendType" SG_ 975 HBFS_FH_S_HFS_AutoTief 3;
BA_ "GenSigSwitchedByIgnition" SG_ 975 HBFS_FH_S_HFS_ManHoch 0;
BA_ "GenSigSendType" SG_ 975 HBFS_FH_S_HFS_ManHoch 3;
BA_ "GenSigSwitchedByIgnition" SG_ 975 HBFS_FH_S_HFS_ManTief 0;
BA_ "GenSigSendType" SG_ 975 HBFS_FH_S_HFS_ManTief 3;
BA_ "Fehlerwert" SG_ 975 HBFS_Tuer_Status 3;
BA_ "GenSigSwitchedByIgnition" SG_ 975 HBFS_Tuer_Status 0;
BA_ "GenSigSendType" SG_ 975 HBFS_Tuer_Status 3;
BA_ "Fehlerwert" SG_ 975 HBFS_SAD_Schalter 15;
BA_ "GenSigSwitchedByIgnition" SG_ 975 HBFS_SAD_Schalter 0;
BA_ "GenSigStartValue" SG_ 975 HBFS_SAD_Schalter 14;
BA_ "GenSigSendType" SG_ 975 HBFS_SAD_Schalter 3;
BA_ "GenSigSwitchedByIgnition" SG_ 975 HBFS_FH_S_ManHoch 0;
BA_ "GenSigSendType" SG_ 975 HBFS_FH_S_ManHoch 3;
BA_ "GenSigSwitchedByIgnition" SG_ 975 HBFS_FH_S_AutoHoch 0;
BA_ "GenSigSendType" SG_ 975 HBFS_FH_S_AutoHoch 3;
BA_ "GenSigSwitchedByIgnition" SG_ 975 HBFS_FH_S_ManTief 0;
BA_ "GenSigSendType" SG_ 975 HBFS_FH_S_ManTief 3;
BA_ "GenSigSwitchedByIgnition" SG_ 975 HBFS_FH_S_AutoTief 0;
BA_ "GenSigSendType" SG_ 975 HBFS_FH_S_AutoTief 3;
BA_ "GenSigSwitchedByIgnition" SG_ 975 HBFS_FH_Oeffnung 0;
BA_ "GenSigSendType" SG_ 975 HBFS_FH_Oeffnung 3;
BA_ "GenSigSwitchedByIgnition" SG_ 975 HBFS_FH_Bew_hoch 0;
BA_ "GenSigSendType" SG_ 975 HBFS_FH_Bew_hoch 3;
BA_ "GenSigSwitchedByIgnition" SG_ 975 HBFS_FH_Bew_tief 0;
BA_ "GenSigSendType" SG_ 975 HBFS_FH_Bew_tief 3;
BA_ "GenSigSwitchedByIgnition" SG_ 975 HBFS_FH_Fang 0;
BA_ "GenSigSendType" SG_ 975 HBFS_FH_Fang 3;
BA_ "GenSigSwitchedByIgnition" SG_ 975 HBFS_FH_Block 0;
BA_ "GenSigSendType" SG_ 975 HBFS_FH_Block 3;
BA_ "GenSigSwitchedByIgnition" SG_ 975 HBFS_FH_Thermo 0;
BA_ "GenSigSendType" SG_ 975 HBFS_FH_Thermo 3;
BA_ "GenSigSwitchedByIgnition" SG_ 975 HBFS_UEKB_aktiviert 0;
BA_ "GenSigSendType" SG_ 975 HBFS_UEKB_aktiviert 3;
BA_ "GenSigSwitchedByIgnition" SG_ 975 HBFS_Tueroeffnen_Warnung 0;
BA_ "GenSigSendType" SG_ 975 HBFS_Tueroeffnen_Warnung 3;
BA_ "GenSigSwitchedByIgnition" SG_ 975 HBFS_FH_normiert 0;
BA_ "GenSigSendType" SG_ 975 HBFS_FH_normiert 3;
BA_ "GenSigSwitchedByIgnition" SG_ 975 ASW_Warnung_aktiv_HBFS 0;
BA_ "GenSigSendType" SG_ 975 ASW_Warnung_aktiv_HBFS 3;
BA_ "GenSigSwitchedByIgnition" SG_ 975 HBFS_Zuziehhilfe_aktiv 0;
BA_ "GenSigSendType" SG_ 975 HBFS_Zuziehhilfe_aktiv 3;
BA_ "GenSigSwitchedByIgnition" SG_ 975 HBFS_Seitenrollo_hoch 0;
BA_ "GenSigSendType" SG_ 975 HBFS_Seitenrollo_hoch 3;
BA_ "GenSigSwitchedByIgnition" SG_ 975 HBFS_Seitenrollo_tief 0;
BA_ "GenSigSendType" SG_ 975 HBFS_Seitenrollo_tief 3;
BA_ "GenSigSwitchedByIgnition" SG_ 975 HBFS_Status_KiSi 0;
BA_ "GenSigSendType" SG_ 975 HBFS_Status_KiSi 3;
BA_ "GenSigSwitchedByIgnition" SG_ 975 SSR_HBFS_Pos_Unten 0;
BA_ "GenSigSendType" SG_ 975 SSR_HBFS_Pos_Unten 0;
BA_ "GenSigSwitchedByIgnition" SG_ 975 HBFS_Oben_Block_erw 0;
BA_ "GenSigSendType" SG_ 975 HBFS_Oben_Block_erw 3;
BA_ "GenSigSwitchedByIgnition" SG_ 975 HBFS_Unten_Block_erw 0;
BA_ "GenSigSendType" SG_ 975 HBFS_Unten_Block_erw 3;
BA_ "GenSigSwitchedByIgnition" SG_ 975 MTHBFS_M_Taste 0;
BA_ "GenSigSendType" SG_ 975 MTHBFS_M_Taste 3;
BA_ "GenSigSwitchedByIgnition" SG_ 975 MTHBFS_Pos1 0;
BA_ "GenSigSendType" SG_ 975 MTHBFS_Pos1 3;
BA_ "GenSigSwitchedByIgnition" SG_ 975 MTHBFS_Pos2 0;
BA_ "GenSigSendType" SG_ 975 MTHBFS_Pos2 3;
BA_ "GenSigSwitchedByIgnition" SG_ 975 MTHBFS_Pos3 0;
BA_ "GenSigSendType" SG_ 975 MTHBFS_Pos3 3;
BA_ "Fehlerwert" SG_ 975 HBFS_MRollo_Schalter 7;
BA_ "GenSigSwitchedByIgnition" SG_ 975 HBFS_MRollo_Schalter 0;
BA_ "GenSigStartValue" SG_ 975 HBFS_MRollo_Schalter 6;
BA_ "GenSigSendType" SG_ 975 HBFS_MRollo_Schalter 3;
BA_ "GenSigSwitchedByIgnition" SG_ 975 HBFS_Lock_Taster_inv 0;
BA_ "GenSigSendType" SG_ 975 HBFS_Lock_Taster_inv 3;
BA_ "GenSigSwitchedByIgnition" SG_ 975 HBFS_Status_KiSi_inv 0;
BA_ "GenSigStartValue" SG_ 975 HBFS_Status_KiSi_inv 1;
BA_ "GenSigSendType" SG_ 975 HBFS_Status_KiSi_inv 0;
BA_ "Fehlerwert" SG_ 975 HBFS_Status_eTAG 3;
BA_ "GenSigSwitchedByIgnition" SG_ 975 HBFS_Status_eTAG 0;
BA_ "GenSigSendType" SG_ 975 HBFS_Status_eTAG 0;
BA_ "GenSigSwitchedByIgnition" SG_ 975 HBFS_Tuer_Status_QBit 0;
BA_ "GenSigSendType" SG_ 975 HBFS_Tuer_Status_QBit 0;
BA_ "GenSigSendType" SG_ 975 HBFS_TIG_betaetigt_schliessen 3;
BA_ "GenSigSwitchedByIgnition" SG_ 974 HFS_Tuer_geoeffnet 0;
BA_ "GenSigSendType" SG_ 974 HFS_Tuer_geoeffnet 3;
BA_ "GenSigSwitchedByIgnition" SG_ 974 HFS_verriegelt 0;
BA_ "GenSigSendType" SG_ 974 HFS_verriegelt 3;
BA_ "GenSigSwitchedByIgnition" SG_ 974 HFS_gesafet 0;
BA_ "GenSigSendType" SG_ 974 HFS_gesafet 3;
BA_ "GenSigSwitchedByIgnition" SG_ 974 HFS_Heckrollotaster_betaetigt 0;
BA_ "GenSigSendType" SG_ 974 HFS_Heckrollotaster_betaetigt 3;
BA_ "GenSigSwitchedByIgnition" SG_ 974 HFS_Tuerschloss_defekt 0;
BA_ "GenSigSendType" SG_ 974 HFS_Tuerschloss_defekt 0;
BA_ "GenSigSwitchedByIgnition" SG_ 974 HFS_Unlock_Taster 0;
BA_ "GenSigSendType" SG_ 974 HFS_Unlock_Taster 3;
BA_ "GenSigSwitchedByIgnition" SG_ 974 HFS_Lock_Taster 0;
BA_ "GenSigSendType" SG_ 974 HFS_Lock_Taster 3;
BA_ "GenSigSwitchedByIgnition" SG_ 974 HFS_Sperrklinke 0;
BA_ "GenSigSendType" SG_ 974 HFS_Sperrklinke 3;
BA_ "GenSigSwitchedByIgnition" SG_ 974 HFS_TAG_betaetigt 0;
BA_ "GenSigSendType" SG_ 974 HFS_TAG_betaetigt 3;
BA_ "GenSigSwitchedByIgnition" SG_ 974 HFS_TIG_betaetigt 0;
BA_ "GenSigSendType" SG_ 974 HFS_TIG_betaetigt 3;
BA_ "GenSigSwitchedByIgnition" SG_ 974 HFS_FH_S_HBFS_AutoHoch 0;
BA_ "GenSigSendType" SG_ 974 HFS_FH_S_HBFS_AutoHoch 3;
BA_ "GenSigSwitchedByIgnition" SG_ 974 HFS_FH_S_HBFS_AutoTief 0;
BA_ "GenSigSendType" SG_ 974 HFS_FH_S_HBFS_AutoTief 3;
BA_ "GenSigSwitchedByIgnition" SG_ 974 HFS_FH_S_HBFS_ManHoch 0;
BA_ "GenSigSendType" SG_ 974 HFS_FH_S_HBFS_ManHoch 3;
BA_ "GenSigSwitchedByIgnition" SG_ 974 HFS_FH_S_HBFS_ManTief 0;
BA_ "GenSigSendType" SG_ 974 HFS_FH_S_HBFS_ManTief 3;
BA_ "Fehlerwert" SG_ 974 HFS_Tuer_Status 3;
BA_ "GenSigSwitchedByIgnition" SG_ 974 HFS_Tuer_Status 0;
BA_ "GenSigSendType" SG_ 974 HFS_Tuer_Status 3;
BA_ "Fehlerwert" SG_ 974 HFS_SAD_Schalter 15;
BA_ "GenSigSwitchedByIgnition" SG_ 974 HFS_SAD_Schalter 0;
BA_ "GenSigStartValue" SG_ 974 HFS_SAD_Schalter 14;
BA_ "GenSigSendType" SG_ 974 HFS_SAD_Schalter 3;
BA_ "GenSigSwitchedByIgnition" SG_ 974 HFS_FH_S_ManHoch 0;
BA_ "GenSigSendType" SG_ 974 HFS_FH_S_ManHoch 3;
BA_ "GenSigSwitchedByIgnition" SG_ 974 HFS_FH_S_AutoHoch 0;
BA_ "GenSigSendType" SG_ 974 HFS_FH_S_AutoHoch 3;
BA_ "GenSigSwitchedByIgnition" SG_ 974 HFS_FH_S_ManTief 0;
BA_ "GenSigSendType" SG_ 974 HFS_FH_S_ManTief 3;
BA_ "GenSigSwitchedByIgnition" SG_ 974 HFS_FH_S_AutoTief 0;
BA_ "GenSigSendType" SG_ 974 HFS_FH_S_AutoTief 3;
BA_ "GenSigSwitchedByIgnition" SG_ 974 HFS_FH_Oeffnung 0;
BA_ "GenSigSendType" SG_ 974 HFS_FH_Oeffnung 3;
BA_ "GenSigSwitchedByIgnition" SG_ 974 HFS_FH_Bew_hoch 0;
BA_ "GenSigSendType" SG_ 974 HFS_FH_Bew_hoch 3;
BA_ "GenSigSwitchedByIgnition" SG_ 974 HFS_FH_Bew_tief 0;
BA_ "GenSigSendType" SG_ 974 HFS_FH_Bew_tief 3;
BA_ "GenSigSwitchedByIgnition" SG_ 974 HFS_FH_Fang 0;
BA_ "GenSigSendType" SG_ 974 HFS_FH_Fang 3;
BA_ "GenSigSwitchedByIgnition" SG_ 974 HFS_FH_Block 0;
BA_ "GenSigSendType" SG_ 974 HFS_FH_Block 3;
BA_ "GenSigSwitchedByIgnition" SG_ 974 HFS_FH_Thermo 0;
BA_ "GenSigSendType" SG_ 974 HFS_FH_Thermo 3;
BA_ "GenSigSwitchedByIgnition" SG_ 974 HFS_UEKB_aktiviert 0;
BA_ "GenSigSendType" SG_ 974 HFS_UEKB_aktiviert 3;
BA_ "GenSigSwitchedByIgnition" SG_ 974 HFS_Tueroeffnen_Warnung 0;
BA_ "GenSigSendType" SG_ 974 HFS_Tueroeffnen_Warnung 3;
BA_ "GenSigSwitchedByIgnition" SG_ 974 HFS_FH_normiert 0;
BA_ "GenSigSendType" SG_ 974 HFS_FH_normiert 3;
BA_ "GenSigSwitchedByIgnition" SG_ 974 ASW_Warnung_aktiv_HFS 0;
BA_ "GenSigSendType" SG_ 974 ASW_Warnung_aktiv_HFS 3;
BA_ "GenSigSwitchedByIgnition" SG_ 974 HFS_Zuziehhilfe_aktiv 0;
BA_ "GenSigSendType" SG_ 974 HFS_Zuziehhilfe_aktiv 3;
BA_ "GenSigSwitchedByIgnition" SG_ 974 HFS_Seitenrollo_hoch 0;
BA_ "GenSigSendType" SG_ 974 HFS_Seitenrollo_hoch 3;
BA_ "GenSigSwitchedByIgnition" SG_ 974 HFS_Seitenrollo_tief 0;
BA_ "GenSigSendType" SG_ 974 HFS_Seitenrollo_tief 3;
BA_ "GenSigSwitchedByIgnition" SG_ 974 HFS_Status_KiSi 0;
BA_ "GenSigSendType" SG_ 974 HFS_Status_KiSi 3;
BA_ "GenSigSwitchedByIgnition" SG_ 974 SSR_HFS_Pos_Unten 0;
BA_ "GenSigSendType" SG_ 974 SSR_HFS_Pos_Unten 0;
BA_ "GenSigSwitchedByIgnition" SG_ 974 HFS_Oben_Block_erw 0;
BA_ "GenSigSendType" SG_ 974 HFS_Oben_Block_erw 3;
BA_ "GenSigSwitchedByIgnition" SG_ 974 HFS_Unten_Block_erw 0;
BA_ "GenSigSendType" SG_ 974 HFS_Unten_Block_erw 3;
BA_ "GenSigSwitchedByIgnition" SG_ 974 MTHFS_M_Taste 0;
BA_ "GenSigSendType" SG_ 974 MTHFS_M_Taste 3;
BA_ "GenSigSwitchedByIgnition" SG_ 974 MTHFS_Pos1 0;
BA_ "GenSigSendType" SG_ 974 MTHFS_Pos1 3;
BA_ "GenSigSwitchedByIgnition" SG_ 974 MTHFS_Pos2 0;
BA_ "GenSigSendType" SG_ 974 MTHFS_Pos2 3;
BA_ "GenSigSwitchedByIgnition" SG_ 974 MTHFS_Pos3 0;
BA_ "GenSigSendType" SG_ 974 MTHFS_Pos3 3;
BA_ "Fehlerwert" SG_ 974 HFS_MRollo_Schalter 7;
BA_ "GenSigSwitchedByIgnition" SG_ 974 HFS_MRollo_Schalter 0;
BA_ "GenSigStartValue" SG_ 974 HFS_MRollo_Schalter 6;
BA_ "GenSigSendType" SG_ 974 HFS_MRollo_Schalter 3;
BA_ "GenSigSwitchedByIgnition" SG_ 974 HFS_Lock_Taster_inv 0;
BA_ "GenSigSendType" SG_ 974 HFS_Lock_Taster_inv 3;
BA_ "Fehlerwert" SG_ 974 HFS_Status_eTAG 3;
BA_ "GenSigSwitchedByIgnition" SG_ 974 HFS_Status_eTAG 0;
BA_ "GenSigSendType" SG_ 974 HFS_Status_eTAG 0;
BA_ "GenSigSwitchedByIgnition" SG_ 974 HFS_Tuer_Status_QBit 0;
BA_ "GenSigSendType" SG_ 974 HFS_Tuer_Status_QBit 0;
BA_ "GenSigSwitchedByIgnition" SG_ 974 HFS_TCR_Mode_aktiv 0;
BA_ "GenSigSendType" SG_ 974 HFS_TCR_Mode_aktiv 3;
BA_ "GenSigSwitchedByIgnition" SG_ 1716 VIN_01_MUX 0;
BA_ "GenSigSendType" SG_ 1716 VIN_01_MUX 0;
BA_ "GenSigSwitchedByIgnition" SG_ 1716 KS_Geheimnis_1 0;
BA_ "GenSigSwitchedByIgnition" SG_ 1716 VIN_4 0;
BA_ "GenSigStartValue" SG_ 1716 VIN_4 45;
BA_ "GenSigSwitchedByIgnition" SG_ 1716 VIN_11 0;
BA_ "GenSigStartValue" SG_ 1716 VIN_11 45;
BA_ "GenSigSwitchedByIgnition" SG_ 1716 KS_Geheimnis_2 0;
BA_ "GenSigSwitchedByIgnition" SG_ 1716 VIN_5 0;
BA_ "GenSigStartValue" SG_ 1716 VIN_5 45;
BA_ "GenSigSwitchedByIgnition" SG_ 1716 VIN_12 0;
BA_ "GenSigStartValue" SG_ 1716 VIN_12 45;
BA_ "GenSigSwitchedByIgnition" SG_ 1716 KS_Geheimnis_3 0;
BA_ "GenSigSwitchedByIgnition" SG_ 1716 VIN_6 0;
BA_ "GenSigStartValue" SG_ 1716 VIN_6 45;
BA_ "GenSigSwitchedByIgnition" SG_ 1716 VIN_13 0;
BA_ "GenSigStartValue" SG_ 1716 VIN_13 45;
BA_ "GenSigSwitchedByIgnition" SG_ 1716 KS_Geheimnis_4 0;
BA_ "GenSigSwitchedByIgnition" SG_ 1716 VIN_7 0;
BA_ "GenSigStartValue" SG_ 1716 VIN_7 45;
BA_ "GenSigSwitchedByIgnition" SG_ 1716 VIN_14 0;
BA_ "GenSigStartValue" SG_ 1716 VIN_14 45;
BA_ "GenSigSwitchedByIgnition" SG_ 1716 VIN_1 0;
BA_ "GenSigStartValue" SG_ 1716 VIN_1 45;
BA_ "GenSigSwitchedByIgnition" SG_ 1716 VIN_8 0;
BA_ "GenSigStartValue" SG_ 1716 VIN_8 45;
BA_ "GenSigSwitchedByIgnition" SG_ 1716 VIN_15 0;
BA_ "GenSigStartValue" SG_ 1716 VIN_15 45;
BA_ "GenSigSwitchedByIgnition" SG_ 1716 VIN_2 0;
BA_ "GenSigStartValue" SG_ 1716 VIN_2 45;
BA_ "GenSigSwitchedByIgnition" SG_ 1716 VIN_9 0;
BA_ "GenSigStartValue" SG_ 1716 VIN_9 45;
BA_ "GenSigSwitchedByIgnition" SG_ 1716 VIN_16 0;
BA_ "GenSigStartValue" SG_ 1716 VIN_16 45;
BA_ "GenSigSwitchedByIgnition" SG_ 1716 VIN_3 0;
BA_ "GenSigStartValue" SG_ 1716 VIN_3 45;
BA_ "GenSigSwitchedByIgnition" SG_ 1716 VIN_10 0;
BA_ "GenSigStartValue" SG_ 1716 VIN_10 45;
BA_ "GenSigSwitchedByIgnition" SG_ 1716 VIN_17 0;
BA_ "GenSigStartValue" SG_ 1716 VIN_17 45;
BA_ "GenSigSwitchedByIgnition" SG_ 916 WBA_03_CRC 0;
BA_ "GenSigFuncType" SG_ 916 WBA_03_CRC 2;
BA_ "GenSigSendType" SG_ 916 WBA_03_CRC 0;
BA_ "GenSigSwitchedByIgnition" SG_ 916 WBA_03_BZ 0;
BA_ "GenSigFuncType" SG_ 916 WBA_03_BZ 1;
BA_ "GenSigSendType" SG_ 916 WBA_03_BZ 0;
BA_ "GenSigSwitchedByIgnition" SG_ 916 WBA_Fahrstufe_02 0;
BA_ "GenSigSendType" SG_ 916 WBA_Fahrstufe_02 3;
BA_ "GenSigSendType" SG_ 916 WBA_ZielFahrstufe 3;
BA_ "GenSigSwitchedByIgnition" SG_ 916 WBA_GE_Warnung_02 0;
BA_ "GenSigSendType" SG_ 916 WBA_GE_Warnung_02 3;
BA_ "GenSigSwitchedByIgnition" SG_ 916 WBA_eing_Gang_02 0;
BA_ "GenSigSendType" SG_ 916 WBA_eing_Gang_02 3;
BA_ "GenSigSwitchedByIgnition" SG_ 916 WBA_GE_Texte 0;
BA_ "GenSigSendType" SG_ 916 WBA_GE_Texte 3;
BA_ "GenSigSwitchedByIgnition" SG_ 916 WBA_Segeln_aktiv 0;
BA_ "GenSigSendType" SG_ 916 WBA_Segeln_aktiv 3;
BA_ "GenSigSendType" SG_ 916 WBA_Schaltschema 3;
BA_ "GenSigSwitchedByIgnition" SG_ 916 WBA_GE_Zusatzwarnungen 0;
BA_ "GenSigSendType" SG_ 916 WBA_GE_Zusatzwarnungen 3;
BA_ "GenSigSwitchedByIgnition" SG_ 916 GE_Sollgang 0;
BA_ "GenSigSendType" SG_ 916 GE_Sollgang 3;
BA_ "GenSigSwitchedByIgnition" SG_ 916 GE_Tipschaltempf_verfuegbar 0;
BA_ "GenSigFuncType" SG_ 916 GE_Tipschaltempf_verfuegbar 8;
BA_ "GenSigSendType" SG_ 916 GE_Tipschaltempf_verfuegbar 3;
BA_ "GenSigSwitchedByIgnition" SG_ 916 WBA_GE_Texte_02 0;
BA_ "GenSigSendType" SG_ 916 WBA_GE_Texte_02 3;
BA_ "Fehlerwert" SG_ 916 WBA_GE_Texte_03 15;
BA_ "GenSigSwitchedByIgnition" SG_ 916 WBA_GE_Texte_03 0;
BA_ "GenSigSendType" SG_ 916 WBA_GE_Texte_03 0;
BA_ "GenSigSwitchedByIgnition" SG_ 916 WBA_Blinken 0;
BA_ "GenSigSendType" SG_ 916 WBA_Blinken 3;
BA_ "GenSigSwitchedByIgnition" SG_ 916 GE_Wiederstart_Anz_Std 0;
BA_ "GenSigSendType" SG_ 916 GE_Wiederstart_Anz_Std 3;
BA_ "GenSigSwitchedByIgnition" SG_ 916 GE_Stoppverbot_Anz_01 0;
BA_ "GenSigSendType" SG_ 916 GE_Stoppverbot_Anz_01 3;
BA_ "GenSigSwitchedByIgnition" SG_ 916 GE_Stoppverbot_Anz_02 0;
BA_ "GenSigSendType" SG_ 916 GE_Stoppverbot_Anz_02 3;
BA_ "GenSigSwitchedByIgnition" SG_ 916 GE_Stoppverbot_Anz_03 0;
BA_ "GenSigSendType" SG_ 916 GE_Stoppverbot_Anz_03 3;
BA_ "GenSigSwitchedByIgnition" SG_ 916 GE_Stoppverbot_Anz_04 0;
BA_ "GenSigSendType" SG_ 916 GE_Stoppverbot_Anz_04 3;
BA_ "GenSigSwitchedByIgnition" SG_ 916 GE_Stoppverbot_Anz_05 0;
BA_ "GenSigSendType" SG_ 916 GE_Stoppverbot_Anz_05 3;
BA_ "GenSigSwitchedByIgnition" SG_ 916 GE_Stoppverbot_Anz_06 0;
BA_ "GenSigSendType" SG_ 916 GE_Stoppverbot_Anz_06 3;
BA_ "GenSigSwitchedByIgnition" SG_ 916 GE_Stoppverbot_Anz_07 0;
BA_ "GenSigSendType" SG_ 916 GE_Stoppverbot_Anz_07 3;
BA_ "GenSigSwitchedByIgnition" SG_ 916 GE_Stoppverbot_Anz_Std 0;
BA_ "GenSigSendType" SG_ 916 GE_Stoppverbot_Anz_Std 3;
BA_ "GenSigSwitchedByIgnition" SG_ 1702 Wischer_vorne_aktiv 0;
BA_ "GenSigSendType" SG_ 1702 Wischer_vorne_aktiv 3;
BA_ "GenSigSwitchedByIgnition" SG_ 1702 Waschen_vorne_aktiv 0;
BA_ "GenSigSendType" SG_ 1702 Waschen_vorne_aktiv 3;
BA_ "GenSigSwitchedByIgnition" SG_ 1702 Wischer_vorne_Normal 0;
BA_ "GenSigSendType" SG_ 1702 Wischer_vorne_Normal 3;
BA_ "GenSigSwitchedByIgnition" SG_ 1702 Wischer_vorne_Schnell 0;
BA_ "GenSigSendType" SG_ 1702 Wischer_vorne_Schnell 3;
BA_ "GenSigStartValue" SG_ 1702 Wischer_vorne_Parklage 1;
BA_ "GenSigSendType" SG_ 1702 Wischer_vorne_Parklage 3;
BA_ "GenSigSwitchedByIgnition" SG_ 1702 Wischer_vorne_defekt 0;
BA_ "GenSigSendType" SG_ 1702 Wischer_vorne_defekt 3;
BA_ "GenSigSendType" SG_ 1702 Wischer_vorne_blockiert 3;
BA_ "GenSigSwitchedByIgnition" SG_ 1702 Wischer1_Wischgeschwindigkeit 0;
BA_ "GenSigStartValue" SG_ 1702 Wischer1_Wischgeschwindigkeit 62;
BA_ "GenSigSendType" SG_ 1702 Wischer1_Wischgeschwindigkeit 0;
BA_ "GenSigSwitchedByIgnition" SG_ 1702 BCM1_SRA_aktiv 0;
BA_ "GenSigSendType" SG_ 1702 BCM1_SRA_aktiv 3;
BA_ "GenSigSwitchedByIgnition" SG_ 1702 Heckwischer_Anforderung 0;
BA_ "GenSigSendType" SG_ 1702 Heckwischer_Anforderung 4;
BA_ "GenSigActiveRepetitions" SG_ 1702 Heckwischer_Anforderung 3;
BA_ "GenSigSwitchedByIgnition" SG_ 1702 WWSs_01_upd 0;
BA_ "GenSigFuncType" SG_ 1702 WWSs_01_upd 5;
BA_ "GenSigSendType" SG_ 1702 WWSs_01_upd 0;
BA_ "GenSigSwitchedByIgnition" SG_ 1702 Wischer_Anzeigetext 0;
BA_ "GenSigSendType" SG_ 1702 Wischer_Anzeigetext 3;
BA_ "GenSigSwitchedByIgnition" SG_ 2617016064 XCP_AWC_CRO_01_Data 0;
BA_ "GenSigSwitchedByIgnition" SG_ 2617016065 XCP_AWC_DTO_01_Data 0;
BA_ "GenSigSwitchedByIgnition" SG_ 2617079552 XCP_BattRegelung_CRO_01_Data 0;
BA_ "GenSigFuncType" SG_ 2617079552 XCP_BattRegelung_CRO_01_Data 9;
BA_ "GenSigSwitchedByIgnition" SG_ 2617079553 XCP_BattRegelung_DTO_01_Data 0;
BA_ "GenSigFuncType" SG_ 2617079553 XCP_BattRegelung_DTO_01_Data 9;
BA_ "GenSigSwitchedByIgnition" SG_ 2617042689 XCP_BMS_MV_DTO_01_Data 0;
BA_ "GenSigFuncType" SG_ 2617042689 XCP_BMS_MV_DTO_01_Data 9;
BA_ "GenSigSwitchedByIgnition" SG_ 2617118208 XCP_DCDC_CRO_01_Data 0;
BA_ "GenSigSwitchedByIgnition" SG_ 2617118209 XCP_DCDC_DTO_01_Data 0;
BA_ "GenSigSwitchedByIgnition" SG_ 2617097984 XCP_DCDC_HV_CRO_01_Data 0;
BA_ "GenSigSwitchedByIgnition" SG_ 2617097985 XCP_DCDC_HV_DTO_01_Data 0;
BA_ "GenSigSwitchedByIgnition" SG_ 2617093888 XCP_FCU_CRO_01_Data 0;
BA_ "GenSigSwitchedByIgnition" SG_ 2617093889 XCP_FCU_DTO_01_Data 0;
BA_ "GenSigSwitchedByIgnition" SG_ 2617120256 XCP_TME_CRO_01_Data 0;
BA_ "GenSigSwitchedByIgnition" SG_ 2617120257 XCP_TME_DTO_01_Data 0;
BA_ "GenSigSwitchedByIgnition" SG_ 1140 ZR_State_DU_1 0;
BA_ "GenSigSendType" SG_ 1140 ZR_State_DU_1 3;
BA_ "GenSigSwitchedByIgnition" SG_ 1140 ZR_State_DU_2 0;
BA_ "GenSigSendType" SG_ 1140 ZR_State_DU_2 3;
BA_ "GenSigSwitchedByIgnition" SG_ 1140 ZR_State_DU_3 0;
BA_ "GenSigSendType" SG_ 1140 ZR_State_DU_3 3;
BA_ "GenSigSwitchedByIgnition" SG_ 1140 ZR_WecktGesp 0;
BA_ "GenSigSendType" SG_ 1140 ZR_WecktGesp 3;
BA_ "GenSigSwitchedByIgnition" SG_ 1140 MMI_State 0;
BA_ "GenSigSendType" SG_ 1140 MMI_State 3;
BA_ "GenSigSwitchedByIgnition" SG_ 1140 ZR_DimOffs_DU_1 0;
BA_ "GenSigStartValue" SG_ 1140 ZR_DimOffs_DU_1 14;
BA_ "GenSigSendType" SG_ 1140 ZR_DimOffs_DU_1 3;
BA_ "GenSigSwitchedByIgnition" SG_ 1140 ZR_DimOffs_DU_2 0;
BA_ "GenSigStartValue" SG_ 1140 ZR_DimOffs_DU_2 14;
BA_ "GenSigSendType" SG_ 1140 ZR_DimOffs_DU_2 3;
BA_ "GenSigSwitchedByIgnition" SG_ 1140 ZR_DimOffs_DU_3 0;
BA_ "GenSigStartValue" SG_ 1140 ZR_DimOffs_DU_3 14;
BA_ "GenSigSendType" SG_ 1140 ZR_DimOffs_DU_3 3;
BA_ "GenSigSwitchedByIgnition" SG_ 1140 SI_ICAN 0;
BA_ "GenSigStartValue" SG_ 1140 SI_ICAN 1;
BA_ "GenSigSendType" SG_ 1140 SI_ICAN 3;
BA_ "GenSigSwitchedByIgnition" SG_ 1140 ZR_Lenkerposition 0;
BA_ "GenSigSendType" SG_ 1140 ZR_Lenkerposition 0;
BA_ "GenSigSwitchedByIgnition" SG_ 1140 WLC1_Systemzustand 0;
BA_ "GenSigSendType" SG_ 1140 WLC1_Systemzustand 3;
BA_ "GenSigSwitchedByIgnition" SG_ 1140 WLC2_Systemzustand 0;
BA_ "GenSigSendType" SG_ 1140 WLC2_Systemzustand 3;
BA_ "GenSigSwitchedByIgnition" SG_ 1140 ZR_SpannungSaeule 0;
BA_ "GenSigSendType" SG_ 1140 ZR_SpannungSaeule 3;
BA_ "GenSigSwitchedByIgnition" SG_ 1140 ZR_LeistungSaeule 0;
BA_ "GenSigSendType" SG_ 1140 ZR_LeistungSaeule 3;
BA_ "GenSigSwitchedByIgnition" SG_ 1140 ZR_t_naechsteLadung 0;
BA_ "GenSigSendType" SG_ 1140 ZR_t_naechsteLadung 3;
BA_ "GenSigFuncType" SG_ 388 ZV_01_CRC 2;
BA_ "GenSigSendType" SG_ 388 ZV_01_CRC 0;
BA_ "GenSigFuncType" SG_ 388 ZV_01_BZ 1;
BA_ "GenSigSendType" SG_ 388 ZV_01_BZ 0;
BA_ "GenSigSwitchedByIgnition" SG_ 388 ZV_FT_verriegeln 0;
BA_ "GenSigSendType" SG_ 388 ZV_FT_verriegeln 6;
BA_ "GenSigActiveRepetitions" SG_ 388 ZV_FT_verriegeln 11;
BA_ "GenSigSwitchedByIgnition" SG_ 388 ZV_FT_entriegeln 0;
BA_ "GenSigSendType" SG_ 388 ZV_FT_entriegeln 6;
BA_ "GenSigActiveRepetitions" SG_ 388 ZV_FT_entriegeln 11;
BA_ "GenSigSwitchedByIgnition" SG_ 388 ZV_BT_verriegeln 0;
BA_ "GenSigSendType" SG_ 388 ZV_BT_verriegeln 6;
BA_ "GenSigActiveRepetitions" SG_ 388 ZV_BT_verriegeln 11;
BA_ "GenSigSwitchedByIgnition" SG_ 388 ZV_BT_entriegeln 0;
BA_ "GenSigSendType" SG_ 388 ZV_BT_entriegeln 6;
BA_ "GenSigActiveRepetitions" SG_ 388 ZV_BT_entriegeln 11;
BA_ "GenSigSwitchedByIgnition" SG_ 388 ZV_HFS_verriegeln 0;
BA_ "GenSigSendType" SG_ 388 ZV_HFS_verriegeln 6;
BA_ "GenSigActiveRepetitions" SG_ 388 ZV_HFS_verriegeln 11;
BA_ "GenSigSwitchedByIgnition" SG_ 388 ZV_HFS_entriegeln 0;
BA_ "GenSigSendType" SG_ 388 ZV_HFS_entriegeln 6;
BA_ "GenSigActiveRepetitions" SG_ 388 ZV_HFS_entriegeln 11;
BA_ "GenSigSwitchedByIgnition" SG_ 388 ZV_HBFS_verriegeln 0;
BA_ "GenSigSendType" SG_ 388 ZV_HBFS_verriegeln 6;
BA_ "GenSigActiveRepetitions" SG_ 388 ZV_HBFS_verriegeln 11;
BA_ "GenSigSwitchedByIgnition" SG_ 388 ZV_HBFS_entriegeln 0;
BA_ "GenSigSendType" SG_ 388 ZV_HBFS_entriegeln 6;
BA_ "GenSigActiveRepetitions" SG_ 388 ZV_HBFS_entriegeln 11;
BA_ "GenSigSwitchedByIgnition" SG_ 388 ZV_zentral_safen 0;
BA_ "GenSigSendType" SG_ 388 ZV_zentral_safen 6;
BA_ "GenSigActiveRepetitions" SG_ 388 ZV_zentral_safen 11;
BA_ "GenSigSwitchedByIgnition" SG_ 388 ZV_zentral_entsafen 0;
BA_ "GenSigSendType" SG_ 388 ZV_zentral_entsafen 6;
BA_ "GenSigActiveRepetitions" SG_ 388 ZV_zentral_entsafen 11;
BA_ "GenSigSwitchedByIgnition" SG_ 388 ZV_Spg_Anklappen 0;
BA_ "GenSigSendType" SG_ 388 ZV_Spg_Anklappen 6;
BA_ "GenSigActiveRepetitions" SG_ 388 ZV_Spg_Anklappen 11;
BA_ "GenSigSwitchedByIgnition" SG_ 388 ZV_Softtouch_betaetigt 0;
BA_ "GenSigSendType" SG_ 388 ZV_Softtouch_betaetigt 6;
BA_ "GenSigActiveRepetitions" SG_ 388 ZV_Softtouch_betaetigt 11;
BA_ "GenSigSwitchedByIgnition" SG_ 388 ZV_LED_Steuerung 0;
BA_ "GenSigSendType" SG_ 388 ZV_LED_Steuerung 6;
BA_ "GenSigActiveRepetitions" SG_ 388 ZV_LED_Steuerung 11;
BA_ "GenSigSwitchedByIgnition" SG_ 388 ZV_LED_Uebernahme 0;
BA_ "GenSigSendType" SG_ 388 ZV_LED_Uebernahme 6;
BA_ "GenSigActiveRepetitions" SG_ 388 ZV_LED_Uebernahme 11;
BA_ "GenSigSwitchedByIgnition" SG_ 388 ZV_auf_FT 0;
BA_ "GenSigSendType" SG_ 388 ZV_auf_FT 6;
BA_ "GenSigActiveRepetitions" SG_ 388 ZV_auf_FT 11;
BA_ "GenSigSwitchedByIgnition" SG_ 388 ZV_zu_FT 0;
BA_ "GenSigSendType" SG_ 388 ZV_zu_FT 6;
BA_ "GenSigActiveRepetitions" SG_ 388 ZV_zu_FT 11;
BA_ "GenSigSwitchedByIgnition" SG_ 388 ZV_auf_BT 0;
BA_ "GenSigSendType" SG_ 388 ZV_auf_BT 6;
BA_ "GenSigActiveRepetitions" SG_ 388 ZV_auf_BT 11;
BA_ "GenSigSwitchedByIgnition" SG_ 388 ZV_zu_BT 0;
BA_ "GenSigSendType" SG_ 388 ZV_zu_BT 6;
BA_ "GenSigActiveRepetitions" SG_ 388 ZV_zu_BT 11;
BA_ "GenSigSwitchedByIgnition" SG_ 388 ZV_auf_Kessy 0;
BA_ "GenSigSendType" SG_ 388 ZV_auf_Kessy 6;
BA_ "GenSigActiveRepetitions" SG_ 388 ZV_auf_Kessy 11;
BA_ "GenSigSwitchedByIgnition" SG_ 388 ZV_zu_Kessy 0;
BA_ "GenSigSendType" SG_ 388 ZV_zu_Kessy 6;
BA_ "GenSigActiveRepetitions" SG_ 388 ZV_zu_Kessy 11;
BA_ "GenSigSwitchedByIgnition" SG_ 388 ZV_auf_Funk 0;
BA_ "GenSigSendType" SG_ 388 ZV_auf_Funk 6;
BA_ "GenSigActiveRepetitions" SG_ 388 ZV_auf_Funk 11;
BA_ "GenSigSwitchedByIgnition" SG_ 388 ZV_zu_Funk 0;
BA_ "GenSigSendType" SG_ 388 ZV_zu_Funk 6;
BA_ "GenSigActiveRepetitions" SG_ 388 ZV_zu_Funk 11;
BA_ "GenSigSwitchedByIgnition" SG_ 388 VIP_Sensor_betaetigt 0;
BA_ "GenSigSendType" SG_ 388 VIP_Sensor_betaetigt 6;
BA_ "GenSigActiveRepetitions" SG_ 388 VIP_Sensor_betaetigt 11;
BA_ "GenSigSwitchedByIgnition" SG_ 388 VIP_Freigabe 0;
BA_ "GenSigSendType" SG_ 388 VIP_Freigabe 0;
BA_ "GenSigSwitchedByIgnition" SG_ 388 ZV_zu_Zeitl_Nachverr 0;
BA_ "GenSigSendType" SG_ 388 ZV_zu_Zeitl_Nachverr 6;
BA_ "GenSigActiveRepetitions" SG_ 388 ZV_zu_Zeitl_Nachverr 11;
BA_ "GenSigSwitchedByIgnition" SG_ 388 ZV_HSK_entriegeln 0;
BA_ "GenSigSendType" SG_ 388 ZV_HSK_entriegeln 6;
BA_ "GenSigActiveRepetitions" SG_ 388 ZV_HSK_entriegeln 11;
BA_ "GenSigSwitchedByIgnition" SG_ 388 ZV_HSK_verriegeln 0;
BA_ "GenSigSendType" SG_ 388 ZV_HSK_verriegeln 6;
BA_ "GenSigActiveRepetitions" SG_ 388 ZV_HSK_verriegeln 11;
BA_ "GenSigSwitchedByIgnition" SG_ 388 ZV_Verdeck_zu 0;
BA_ "GenSigSendType" SG_ 388 ZV_Verdeck_zu 6;
BA_ "GenSigActiveRepetitions" SG_ 388 ZV_Verdeck_zu 11;
BA_ "GenSigSwitchedByIgnition" SG_ 388 ZV_Verdeck_auf 0;
BA_ "GenSigSendType" SG_ 388 ZV_Verdeck_auf 6;
BA_ "GenSigActiveRepetitions" SG_ 388 ZV_Verdeck_auf 11;
BA_ "GenSigSwitchedByIgnition" SG_ 388 FH_FT_hoch 0;
BA_ "GenSigSendType" SG_ 388 FH_FT_hoch 6;
BA_ "GenSigActiveRepetitions" SG_ 388 FH_FT_hoch 11;
BA_ "GenSigSwitchedByIgnition" SG_ 388 FH_FT_tief 0;
BA_ "GenSigSendType" SG_ 388 FH_FT_tief 6;
BA_ "GenSigActiveRepetitions" SG_ 388 FH_FT_tief 11;
BA_ "GenSigSwitchedByIgnition" SG_ 388 FH_BT_hoch 0;
BA_ "GenSigSendType" SG_ 388 FH_BT_hoch 6;
BA_ "GenSigActiveRepetitions" SG_ 388 FH_BT_hoch 11;
BA_ "GenSigSwitchedByIgnition" SG_ 388 FH_BT_tief 0;
BA_ "GenSigSendType" SG_ 388 FH_BT_tief 6;
BA_ "GenSigActiveRepetitions" SG_ 388 FH_BT_tief 11;
BA_ "GenSigSwitchedByIgnition" SG_ 388 FH_HFS_hoch 0;
BA_ "GenSigSendType" SG_ 388 FH_HFS_hoch 6;
BA_ "GenSigActiveRepetitions" SG_ 388 FH_HFS_hoch 11;
BA_ "GenSigSwitchedByIgnition" SG_ 388 FH_HFS_tief 0;
BA_ "GenSigSendType" SG_ 388 FH_HFS_tief 6;
BA_ "GenSigActiveRepetitions" SG_ 388 FH_HFS_tief 11;
BA_ "GenSigSwitchedByIgnition" SG_ 388 FH_HBFS_hoch 0;
BA_ "GenSigSendType" SG_ 388 FH_HBFS_hoch 6;
BA_ "GenSigActiveRepetitions" SG_ 388 FH_HBFS_hoch 11;
BA_ "GenSigSwitchedByIgnition" SG_ 388 FH_HBFS_tief 0;
BA_ "GenSigSendType" SG_ 388 FH_HBFS_tief 6;
BA_ "GenSigActiveRepetitions" SG_ 388 FH_HBFS_tief 11;
BA_ "GenSigSwitchedByIgnition" SG_ 388 BCM_Spg_Synchron 0;
BA_ "GenSigSendType" SG_ 388 BCM_Spg_Synchron 0;
BA_ "GenSigSwitchedByIgnition" SG_ 388 BCM_BF_Spg_Absenkung 0;
BA_ "GenSigSendType" SG_ 388 BCM_BF_Spg_Absenkung 0;
BA_ "GenSigSwitchedByIgnition" SG_ 388 ZV_Signatur 0;
BA_ "GenSigSendType" SG_ 388 ZV_Signatur 6;
BA_ "GenSigActiveRepetitions" SG_ 388 ZV_Signatur 11;
BA_ "GenSigSendType" SG_ 388 ZV_entriegeln_Anf 6;
BA_ "GenSigActiveRepetitions" SG_ 388 ZV_entriegeln_Anf 11;
BA_ "GenSigSwitchedByIgnition" SG_ 388 ZV_auto_Ansteuerung 0;
BA_ "GenSigSendType" SG_ 388 ZV_auto_Ansteuerung 6;
BA_ "GenSigActiveRepetitions" SG_ 388 ZV_auto_Ansteuerung 11;
BA_ "GenSigSwitchedByIgnition" SG_ 1411 BCM_FH_Freigabe 0;
BA_ "GenSigSendType" SG_ 1411 BCM_FH_Freigabe 3;
BA_ "GenSigSwitchedByIgnition" SG_ 1411 BCM_Komfortfkt_Freigabe 0;
BA_ "GenSigSendType" SG_ 1411 BCM_Komfortfkt_Freigabe 3;
BA_ "GenSigSendType" SG_ 1411 BCM_HSK_Freigabe 3;
BA_ "GenSigSwitchedByIgnition" SG_ 1411 BCM_Verdeck_Freigabe 0;
BA_ "GenSigSendType" SG_ 1411 BCM_Verdeck_Freigabe 3;
BA_ "GenSigSwitchedByIgnition" SG_ 1411 ZV_verriegelt_intern_ist 0;
BA_ "GenSigSendType" SG_ 1411 ZV_verriegelt_intern_ist 3;
BA_ "GenSigSwitchedByIgnition" SG_ 1411 ZV_verriegelt_extern_ist 0;
BA_ "GenSigSendType" SG_ 1411 ZV_verriegelt_extern_ist 3;
BA_ "GenSigSwitchedByIgnition" SG_ 1411 ZV_verriegelt_intern_soll 0;
BA_ "GenSigSendType" SG_ 1411 ZV_verriegelt_intern_soll 3;
BA_ "GenSigSwitchedByIgnition" SG_ 1411 ZV_verriegelt_extern_soll 0;
BA_ "GenSigSendType" SG_ 1411 ZV_verriegelt_extern_soll 3;
BA_ "GenSigSwitchedByIgnition" SG_ 1411 ZV_gesafet_extern_ist 0;
BA_ "GenSigSendType" SG_ 1411 ZV_gesafet_extern_ist 3;
BA_ "GenSigSwitchedByIgnition" SG_ 1411 ZV_gesafet_extern_soll 0;
BA_ "GenSigSendType" SG_ 1411 ZV_gesafet_extern_soll 3;
BA_ "GenSigSendType" SG_ 1411 ZV_Einzeltuerentriegelung 3;
BA_ "GenSigSwitchedByIgnition" SG_ 1411 ZV_Heckeinzelentriegelung 0;
BA_ "GenSigSendType" SG_ 1411 ZV_Heckeinzelentriegelung 3;
BA_ "GenSigSwitchedByIgnition" SG_ 1411 ZV_FT_offen 0;
BA_ "GenSigSendType" SG_ 1411 ZV_FT_offen 3;
BA_ "GenSigSwitchedByIgnition" SG_ 1411 ZV_BT_offen 0;
BA_ "GenSigSendType" SG_ 1411 ZV_BT_offen 3;
BA_ "GenSigSwitchedByIgnition" SG_ 1411 ZV_HFS_offen 0;
BA_ "GenSigSendType" SG_ 1411 ZV_HFS_offen 3;
BA_ "GenSigSwitchedByIgnition" SG_ 1411 ZV_HBFS_offen 0;
BA_ "GenSigSendType" SG_ 1411 ZV_HBFS_offen 3;
BA_ "GenSigSwitchedByIgnition" SG_ 1411 ZV_HD_offen 0;
BA_ "GenSigSendType" SG_ 1411 ZV_HD_offen 3;
BA_ "GenSigSwitchedByIgnition" SG_ 1411 ZV_HS_offen 0;
BA_ "GenSigSendType" SG_ 1411 ZV_HS_offen 3;
BA_ "GenSigSwitchedByIgnition" SG_ 1411 IRUE_aktiv 0;
BA_ "GenSigSendType" SG_ 1411 IRUE_aktiv 3;
BA_ "GenSigSwitchedByIgnition" SG_ 1411 DWA_aktiv 0;
BA_ "GenSigSendType" SG_ 1411 DWA_aktiv 3;
BA_ "GenSigSwitchedByIgnition" SG_ 1411 HD_Hauptraste 0;
BA_ "GenSigSendType" SG_ 1411 HD_Hauptraste 3;
BA_ "GenSigSwitchedByIgnition" SG_ 1411 HD_Vorraste 0;
BA_ "GenSigSendType" SG_ 1411 HD_Vorraste 3;
BA_ "GenSigSendType" SG_ 1411 FFB_CarFinder 2;
BA_ "GenSigActiveRepetitions" SG_ 1411 FFB_CarFinder 5;
BA_ "GenSigSendType" SG_ 1411 FFB_Komfortoeffnen 2;
BA_ "GenSigActiveRepetitions" SG_ 1411 FFB_Komfortoeffnen 5;
BA_ "GenSigSendType" SG_ 1411 FFB_Komfortschliessen 2;
BA_ "GenSigActiveRepetitions" SG_ 1411 FFB_Komfortschliessen 5;
BA_ "GenSigSwitchedByIgnition" SG_ 1411 ZV_Schluessel_Zugang 0;
BA_ "GenSigSendType" SG_ 1411 ZV_Schluessel_Zugang 4;
BA_ "GenSigActiveRepetitions" SG_ 1411 ZV_Schluessel_Zugang 5;
BA_ "GenSigSwitchedByIgnition" SG_ 1411 ZV_SafeFunktion_aktiv 0;
BA_ "GenSigSendType" SG_ 1411 ZV_SafeFunktion_aktiv 3;
BA_ "GenSigSwitchedByIgnition" SG_ 1411 FBS_Warn_Schluessel_Batt 0;
BA_ "GenSigSendType" SG_ 1411 FBS_Warn_Schluessel_Batt 3;
BA_ "GenSigSendType" SG_ 1411 ZV_Oeffnungsmodus 3;
BA_ "GenSigSwitchedByIgnition" SG_ 1411 HFS_verriegelt 0;
BA_ "GenSigSendType" SG_ 1411 HFS_verriegelt 3;
BA_ "GenSigSwitchedByIgnition" SG_ 1411 HFS_gesafet 0;
BA_ "GenSigSendType" SG_ 1411 HFS_gesafet 3;
BA_ "GenSigSwitchedByIgnition" SG_ 1411 HBFS_verriegelt 0;
BA_ "GenSigSendType" SG_ 1411 HBFS_verriegelt 3;
BA_ "GenSigSwitchedByIgnition" SG_ 1411 HBFS_gesafet 0;
BA_ "GenSigSendType" SG_ 1411 HBFS_gesafet 3;
BA_ "GenSigSwitchedByIgnition" SG_ 1411 ZV_ist_Zustand_verfuegbar 0;
BA_ "GenSigSendType" SG_ 1411 ZV_ist_Zustand_verfuegbar 3;
BA_ "GenSigSwitchedByIgnition" SG_ 1411 IRUE_Taster_Fkts_LED 0;
BA_ "GenSigSendType" SG_ 1411 IRUE_Taster_Fkts_LED 3;
BA_ "GenSigSwitchedByIgnition" SG_ 1411 ZV_Tankklappe_offen 0;
BA_ "GenSigSendType" SG_ 1411 ZV_Tankklappe_offen 0;
BA_ "GenSigSwitchedByIgnition" SG_ 1411 ZV_Rollo_auf 0;
BA_ "GenSigSendType" SG_ 1411 ZV_Rollo_auf 3;
BA_ "GenSigSwitchedByIgnition" SG_ 1411 ZV_Rollo_zu 0;
BA_ "GenSigSendType" SG_ 1411 ZV_Rollo_zu 3;
BA_ "GenSigSwitchedByIgnition" SG_ 1411 ZV_SAD_auf 0;
BA_ "GenSigSendType" SG_ 1411 ZV_SAD_auf 3;
BA_ "GenSigSwitchedByIgnition" SG_ 1411 ZV_SAD_zu 0;
BA_ "GenSigSendType" SG_ 1411 ZV_SAD_zu 3;
BA_ "Fehlerwert" SG_ 1411 BCM_Tankklappensteller_Fehler 1;
BA_ "GenSigSwitchedByIgnition" SG_ 1411 BCM_Tankklappensteller_Fehler 0;
BA_ "GenSigSendType" SG_ 1411 BCM_Tankklappensteller_Fehler 0;
BA_ "GenSigSendType" SG_ 1411 ZV_verriegelt_soll 3;
BA_REL_ "GenSigTimeoutTime" BU_SG_REL_ Ladegeraet_Konzern SG_ 1399 TME_Leistung_Komfort_HV_stat 3200;
BA_REL_ "GenSigTimeoutTime" BU_SG_REL_ Ladegeraet_Konzern SG_ 1399 TME_Leistung_Thermo_HV_stat 3200;
BA_REL_ "GenSigTimeoutTime" BU_SG_REL_ Ladegeraet_Konzern SG_ 1399 TME_Energie_Komfort_NV 3200;
BA_REL_ "GenSigTimeoutTime" BU_SG_REL_ Ladegeraet_Konzern SG_ 1399 TME_Energie_Thermo_NV 3200;
BA_REL_ "GenSigTimeoutTime" BU_SG_REL_ Ladegeraet_Konzern SG_ 1399 TME_Leistung_Komfort_NV_stat 3200;
BA_REL_ "GenSigTimeoutTime" BU_SG_REL_ Ladegeraet_Konzern SG_ 1399 TME_Leistung_Thermo_NV_stat 3200;
BA_REL_ "GenSigTimeoutTime" BU_SG_REL_ Ladegeraet_Konzern SG_ 1375 TME_VoKo_Strategie_Anzeige 5000;
BA_REL_ "GenSigTimeoutTime" BU_SG_REL_ Ladegeraet_Konzern SG_ 1375 TME_Heizstrategie 5000;
BA_REL_ "GenSigTimeoutTime" BU_SG_REL_ Ladegeraet_Konzern SG_ 1375 TME_Freigabe_Vorkond 5000;
BA_REL_ "GenSigTimeoutTime" BU_SG_REL_ BMC_MLBevo SG_ 1375 TME_Kuehlmittel_Sensor 5000;
BA_REL_ "GenSigTimeoutTime" BU_SG_REL_ FCU_MLBevo_FCEV SG_ 1375 TME_Heizungspumpen_Anst 5000;
BA_REL_ "GenSigTimeoutTime" BU_SG_REL_ Ladegeraet_Konzern SG_ 1373 TME_Kond_Innen_Betrieb 5000;
BA_REL_ "GenSigTimeoutTime" BU_SG_REL_ Ladegeraet_Konzern SG_ 1373 TME_STH_Status 5000;
BA_REL_ "GenSigTimeoutTime" BU_SG_REL_ Ladegeraet_Konzern SG_ 1373 TME_Kond_Innen_Betriebsdauer 5000;
BA_REL_ "GenSigTimeoutTime" BU_SG_REL_ Ladegeraet_Konzern SG_ 1373 TME_Kond_Innen_Status 5000;
BA_REL_ "GenSigTimeoutTime" BU_SG_REL_ LE1 SG_ 1373 TME_Temp_KM_vor_LE 5000;
BA_REL_ "GenSigTimeoutTime" BU_SG_REL_ LE2 SG_ 1373 TME_Temp_KM_vor_LE 5000;
BA_REL_ "GenSigTimeoutTime" BU_SG_REL_ LE_MLBevo SG_ 1373 TME_Temp_KM_vor_LE 5000;
BA_REL_ "GenSigTimeoutTime" BU_SG_REL_ BMC_MLBevo SG_ 1373 TME_Kuehlmittel_Temp_Pumpe1_tNT 5000;
BA_REL_ "GenSigTimeoutTime" BU_SG_REL_ BMC_MLBevo SG_ 1373 TME_IstSpannung_EKK_HV 5000;
BA_REL_ "GenSigTimeoutTime" BU_SG_REL_ DCDC_800V_PAG SG_ 1373 TME_IstSpannung_EKK_HV 5000;
BA_REL_ "GenSigTimeoutTime" BU_SG_REL_ Gateway SG_ 1373 TME_IstSpannung_EKK_HV 5000;
BA_REL_ "GenSigTimeoutTime" BU_SG_REL_ Gateway_PAG SG_ 1373 TME_IstSpannung_EKK_HV 5000;
BA_REL_ "GenSigTimeoutTime" BU_SG_REL_ FCU_MLBevo_FCEV SG_ 2463978655 TME_Senkenleistung_verfuegbar 1000;
BA_REL_ "GenSigTimeoutTime" BU_SG_REL_ FCU_MLBevo_FCEV SG_ 2589283463 TME_THMTVLV_Sollstellung 5000;
BA_REL_ "GenSigTimeoutTime" BU_SG_REL_ FCU_MLBevo_FCEV SG_ 2589283463 TME_Mischventil_Heizkreis_Ist 5000;
BA_REL_ "GenSigTimeoutTime" BU_SG_REL_ FCU_MLBevo_FCEV SG_ 2589283463 TME_Ionenspuelung_aktiv 5000;
BA_REL_ "GenSigTimeoutTime" BU_SG_REL_ FCU_MLBevo_FCEV SG_ 2589283463 TME_Temp_KM_v_Pumpe_Heizkreis 5000;
BA_REL_ "GenSigTimeoutTime" BU_SG_REL_ FCU_MLBevo_FCEV SG_ 2589283463 TME_Temp_KM_n_Mischventil_Heizkr 5000;
BA_REL_ "GenSigTimeoutTime" BU_SG_REL_ FCU_MLBevo_FCEV SG_ 2589283463 TME_Befuellung_aktiv 5000;
BA_REL_ "GenSigTimeoutTime" BU_SG_REL_ FCU_MLBevo_FCEV SG_ 2589283463 TME_Entlueftung_aktiv 5000;
BA_REL_ "GenSigTimeoutTime" BU_SG_REL_ FCU_MLBevo_FCEV SG_ 2589283463 TME_KMP_Solldrehzahl 5000;
BA_REL_ "GenSigTimeoutTime" BU_SG_REL_ Gateway SG_ 2527679716 TME_ThermoPred_P_dyn_BTL_FP1 2000;
BA_REL_ "GenSigTimeoutTime" BU_SG_REL_ Gateway_PAG SG_ 2527679716 TME_ThermoPred_P_dyn_BTL_FP1 2000;
BA_REL_ "GenSigTimeoutTime" BU_SG_REL_ Gateway SG_ 2527679716 TME_Pred_BTLSys_Anf_FP1 2000;
BA_REL_ "GenSigTimeoutTime" BU_SG_REL_ Gateway_PAG SG_ 2527679716 TME_Pred_BTLSys_Anf_FP1 2000;
BA_REL_ "GenSigTimeoutTime" BU_SG_REL_ Gateway SG_ 2527679716 TME_Pred_KlimaSys_Anf_FP1 2000;
BA_REL_ "GenSigTimeoutTime" BU_SG_REL_ Gateway_PAG SG_ 2527679716 TME_Pred_KlimaSys_Anf_FP1 2000;
BA_REL_ "GenSigTimeoutTime" BU_SG_REL_ Gateway SG_ 2527679716 TME_Pred_KlimaKunde_Anf_FP1 2000;
BA_REL_ "GenSigTimeoutTime" BU_SG_REL_ Gateway_PAG SG_ 2527679716 TME_Pred_KlimaKunde_Anf_FP1 2000;
BA_REL_ "GenSigTimeoutTime" BU_SG_REL_ Gateway SG_ 2527679716 TME_ThermoPred_P_stat_Klima_FP1 2000;
BA_REL_ "GenSigTimeoutTime" BU_SG_REL_ Gateway_PAG SG_ 2527679716 TME_ThermoPred_P_stat_Klima_FP1 2000;
BA_REL_ "GenSigTimeoutTime" BU_SG_REL_ Gateway SG_ 2527679716 TME_ThermoPred_P_dyn_Klima_FP1 2000;
BA_REL_ "GenSigTimeoutTime" BU_SG_REL_ Gateway_PAG SG_ 2527679716 TME_ThermoPred_P_dyn_Klima_FP1 2000;
BA_REL_ "GenSigTimeoutTime" BU_SG_REL_ Gateway SG_ 2527679716 TME_ThermoPred_T_dyn_BTL_FP1 2000;
BA_REL_ "GenSigTimeoutTime" BU_SG_REL_ Gateway_PAG SG_ 2527679716 TME_ThermoPred_T_dyn_BTL_FP1 2000;
BA_REL_ "GenSigTimeoutTime" BU_SG_REL_ Gateway SG_ 2527679716 TME_ThermoPred_T_dyn_Klima_FP1 2000;
BA_REL_ "GenSigTimeoutTime" BU_SG_REL_ Gateway_PAG SG_ 2527679716 TME_ThermoPred_T_dyn_Klima_FP1 2000;
BA_REL_ "GenSigTimeoutTime" BU_SG_REL_ Gateway SG_ 2527679717 TME_ThermoPred_P_dyn_BTL_FP2 2000;
BA_REL_ "GenSigTimeoutTime" BU_SG_REL_ Gateway_PAG SG_ 2527679717 TME_ThermoPred_P_dyn_BTL_FP2 2000;
BA_REL_ "GenSigTimeoutTime" BU_SG_REL_ Gateway SG_ 2527679717 TME_Pred_BTLSys_Anf_FP2 2000;
BA_REL_ "GenSigTimeoutTime" BU_SG_REL_ Gateway_PAG SG_ 2527679717 TME_Pred_BTLSys_Anf_FP2 2000;
BA_REL_ "GenSigTimeoutTime" BU_SG_REL_ Gateway SG_ 2527679717 TME_Pred_KlimaSys_Anf_FP2 2000;
BA_REL_ "GenSigTimeoutTime" BU_SG_REL_ Gateway_PAG SG_ 2527679717 TME_Pred_KlimaSys_Anf_FP2 2000;
BA_REL_ "GenSigTimeoutTime" BU_SG_REL_ Gateway SG_ 2527679717 TME_Pred_KlimaKunde_Anf_FP2 2000;
BA_REL_ "GenSigTimeoutTime" BU_SG_REL_ Gateway_PAG SG_ 2527679717 TME_Pred_KlimaKunde_Anf_FP2 2000;
BA_REL_ "GenSigTimeoutTime" BU_SG_REL_ Gateway SG_ 2527679717 TME_ThermoPred_P_stat_Klima_FP2 2000;
BA_REL_ "GenSigTimeoutTime" BU_SG_REL_ Gateway_PAG SG_ 2527679717 TME_ThermoPred_P_stat_Klima_FP2 2000;
BA_REL_ "GenSigTimeoutTime" BU_SG_REL_ Gateway SG_ 2527679717 TME_ThermoPred_P_dyn_Klima_FP2 2000;
BA_REL_ "GenSigTimeoutTime" BU_SG_REL_ Gateway_PAG SG_ 2527679717 TME_ThermoPred_P_dyn_Klima_FP2 2000;
BA_REL_ "GenSigTimeoutTime" BU_SG_REL_ Gateway SG_ 2527679717 TME_ThermoPred_T_dyn_BTL_FP2 2000;
BA_REL_ "GenSigTimeoutTime" BU_SG_REL_ Gateway_PAG SG_ 2527679717 TME_ThermoPred_T_dyn_BTL_FP2 2000;
BA_REL_ "GenSigTimeoutTime" BU_SG_REL_ Gateway SG_ 2527679717 TME_ThermoPred_T_dyn_Klima_FP2 2000;
BA_REL_ "GenSigTimeoutTime" BU_SG_REL_ Gateway_PAG SG_ 2527679717 TME_ThermoPred_T_dyn_Klima_FP2 2000;
BA_REL_ "GenSigTimeoutTime" BU_SG_REL_ Gateway SG_ 2527679718 TME_ThermoPred_P_dyn_BTL_FP3 2000;
BA_REL_ "GenSigTimeoutTime" BU_SG_REL_ Gateway_PAG SG_ 2527679718 TME_ThermoPred_P_dyn_BTL_FP3 2000;
BA_REL_ "GenSigTimeoutTime" BU_SG_REL_ Gateway SG_ 2527679718 TME_Pred_BTLSys_Anf_FP3 2000;
BA_REL_ "GenSigTimeoutTime" BU_SG_REL_ Gateway_PAG SG_ 2527679718 TME_Pred_BTLSys_Anf_FP3 2000;
BA_REL_ "GenSigTimeoutTime" BU_SG_REL_ Gateway SG_ 2527679718 TME_Pred_KlimaSys_Anf_FP3 2000;
BA_REL_ "GenSigTimeoutTime" BU_SG_REL_ Gateway_PAG SG_ 2527679718 TME_Pred_KlimaSys_Anf_FP3 2000;
BA_REL_ "GenSigTimeoutTime" BU_SG_REL_ Gateway SG_ 2527679718 TME_Pred_KlimaKunde_Anf_FP3 2000;
BA_REL_ "GenSigTimeoutTime" BU_SG_REL_ Gateway_PAG SG_ 2527679718 TME_Pred_KlimaKunde_Anf_FP3 2000;
BA_REL_ "GenSigTimeoutTime" BU_SG_REL_ Gateway SG_ 2527679718 TME_ThermoPred_P_stat_Klima_FP3 2000;
BA_REL_ "GenSigTimeoutTime" BU_SG_REL_ Gateway_PAG SG_ 2527679718 TME_ThermoPred_P_stat_Klima_FP3 2000;
BA_REL_ "GenSigTimeoutTime" BU_SG_REL_ Gateway SG_ 2527679718 TME_ThermoPred_P_dyn_Klima_FP3 2000;
BA_REL_ "GenSigTimeoutTime" BU_SG_REL_ Gateway_PAG SG_ 2527679718 TME_ThermoPred_P_dyn_Klima_FP3 2000;
BA_REL_ "GenSigTimeoutTime" BU_SG_REL_ Gateway SG_ 2527679718 TME_ThermoPred_T_dyn_BTL_FP3 2000;
BA_REL_ "GenSigTimeoutTime" BU_SG_REL_ Gateway_PAG SG_ 2527679718 TME_ThermoPred_T_dyn_BTL_FP3 2000;
BA_REL_ "GenSigTimeoutTime" BU_SG_REL_ Gateway SG_ 2527679718 TME_ThermoPred_T_dyn_Klima_FP3 2000;
BA_REL_ "GenSigTimeoutTime" BU_SG_REL_ Gateway_PAG SG_ 2527679718 TME_ThermoPred_T_dyn_Klima_FP3 2000;
BA_REL_ "GenSigTimeoutTime" BU_SG_REL_ Gateway SG_ 2463978733 TME_ThermoPred_BTL_System_Anf 1000;
BA_REL_ "GenSigTimeoutTime" BU_SG_REL_ Gateway_PAG SG_ 2463978733 TME_ThermoPred_BTL_System_Anf 1000;
BA_REL_ "GenSigTimeoutTime" BU_SG_REL_ Gateway SG_ 2463978733 TME_ThermoPred_P_dyn_Btl 1000;
BA_REL_ "GenSigTimeoutTime" BU_SG_REL_ Gateway_PAG SG_ 2463978733 TME_ThermoPred_P_dyn_Btl 1000;
BA_REL_ "GenSigTimeoutTime" BU_SG_REL_ Gateway SG_ 2463978733 TME_ThermoPred_T_dyn_Btl 1000;
BA_REL_ "GenSigTimeoutTime" BU_SG_REL_ Gateway_PAG SG_ 2463978733 TME_ThermoPred_T_dyn_Btl 1000;
BA_REL_ "GenSigTimeoutTime" BU_SG_REL_ Ladegeraet_Konzern SG_ 977 BT_Tuer_geoeffnet 1000;
BA_REL_ "GenSigTimeoutTime" BU_SG_REL_ TME SG_ 977 BT_Tuer_geoeffnet 1000;
BA_REL_ "GenSigTimeoutTime" BU_SG_REL_ TME SG_ 977 BT_FH_Oeffnung 1000;
BA_REL_ "GenSigTimeoutTime" BU_SG_REL_ Ladegeraet_Konzern SG_ 976 FT_Tuer_geoeffnet 1000;
BA_REL_ "GenSigTimeoutTime" BU_SG_REL_ TME SG_ 976 FT_Tuer_geoeffnet 1000;
BA_REL_ "GenSigTimeoutTime" BU_SG_REL_ FCU_MLBevo_FCEV SG_ 976 FT_Schluesselschalter_auf 1000;
BA_REL_ "GenSigTimeoutTime" BU_SG_REL_ FCU_MLBevo_FCEV SG_ 976 FT_Schluesselschalter_zu 1000;
BA_REL_ "GenSigTimeoutTime" BU_SG_REL_ Ladegeraet_Konzern SG_ 976 FT_TD_Taste_Fehler 1000;
BA_REL_ "GenSigTimeoutTime" BU_SG_REL_ FCU_MLBevo_FCEV SG_ 976 FT_TD_Taste 1000;
BA_REL_ "GenSigTimeoutTime" BU_SG_REL_ Ladegeraet_Konzern SG_ 976 FT_TD_Taste 1000;
BA_REL_ "GenSigTimeoutTime" BU_SG_REL_ TME SG_ 976 FT_FH_Oeffnung 1000;
BA_REL_ "GenSigTimeoutTime" BU_SG_REL_ TME SG_ 975 HBFS_Seitenrollo_hoch 1000;
BA_REL_ "GenSigTimeoutTime" BU_SG_REL_ TME SG_ 975 HBFS_Seitenrollo_tief 1000;
BA_REL_ "GenSigTimeoutTime" BU_SG_REL_ TME SG_ 974 HFS_Seitenrollo_hoch 1000;
BA_REL_ "GenSigTimeoutTime" BU_SG_REL_ TME SG_ 974 HFS_Seitenrollo_tief 1000;
BA_REL_ "GenSigTimeoutTime" BU_SG_REL_ AWC SG_ 1716 VIN_01_MUX 2000;
BA_REL_ "GenSigTimeoutTime" BU_SG_REL_ Ladegeraet_Konzern SG_ 1716 VIN_01_MUX 2000;
BA_REL_ "GenSigTimeoutTime" BU_SG_REL_ TME SG_ 1716 VIN_01_MUX 2000;
BA_REL_ "GenSigTimeoutTime" BU_SG_REL_ AWC SG_ 1716 VIN_4 2000;
BA_REL_ "GenSigTimeoutTime" BU_SG_REL_ Ladegeraet_Konzern SG_ 1716 VIN_4 2000;
BA_REL_ "GenSigTimeoutTime" BU_SG_REL_ TME SG_ 1716 VIN_4 2000;
BA_REL_ "GenSigTimeoutTime" BU_SG_REL_ AWC SG_ 1716 VIN_11 2000;
BA_REL_ "GenSigTimeoutTime" BU_SG_REL_ Ladegeraet_Konzern SG_ 1716 VIN_11 2000;
BA_REL_ "GenSigTimeoutTime" BU_SG_REL_ TME SG_ 1716 VIN_11 2000;
BA_REL_ "GenSigTimeoutTime" BU_SG_REL_ AWC SG_ 1716 VIN_5 2000;
BA_REL_ "GenSigTimeoutTime" BU_SG_REL_ Ladegeraet_Konzern SG_ 1716 VIN_5 2000;
BA_REL_ "GenSigTimeoutTime" BU_SG_REL_ TME SG_ 1716 VIN_5 2000;
BA_REL_ "GenSigTimeoutTime" BU_SG_REL_ AWC SG_ 1716 VIN_12 2000;
BA_REL_ "GenSigTimeoutTime" BU_SG_REL_ Ladegeraet_Konzern SG_ 1716 VIN_12 2000;
BA_REL_ "GenSigTimeoutTime" BU_SG_REL_ TME SG_ 1716 VIN_12 2000;
BA_REL_ "GenSigTimeoutTime" BU_SG_REL_ AWC SG_ 1716 VIN_6 2000;
BA_REL_ "GenSigTimeoutTime" BU_SG_REL_ Ladegeraet_Konzern SG_ 1716 VIN_6 2000;
BA_REL_ "GenSigTimeoutTime" BU_SG_REL_ TME SG_ 1716 VIN_6 2000;
BA_REL_ "GenSigTimeoutTime" BU_SG_REL_ AWC SG_ 1716 VIN_13 2000;
BA_REL_ "GenSigTimeoutTime" BU_SG_REL_ Ladegeraet_Konzern SG_ 1716 VIN_13 2000;
BA_REL_ "GenSigTimeoutTime" BU_SG_REL_ TME SG_ 1716 VIN_13 2000;
BA_REL_ "GenSigTimeoutTime" BU_SG_REL_ AWC SG_ 1716 VIN_7 2000;
BA_REL_ "GenSigTimeoutTime" BU_SG_REL_ Ladegeraet_Konzern SG_ 1716 VIN_7 2000;
BA_REL_ "GenSigTimeoutTime" BU_SG_REL_ TME SG_ 1716 VIN_7 2000;
BA_REL_ "GenSigTimeoutTime" BU_SG_REL_ AWC SG_ 1716 VIN_14 2000;
BA_REL_ "GenSigTimeoutTime" BU_SG_REL_ Ladegeraet_Konzern SG_ 1716 VIN_14 2000;
BA_REL_ "GenSigTimeoutTime" BU_SG_REL_ TME SG_ 1716 VIN_14 2000;
BA_REL_ "GenSigTimeoutTime" BU_SG_REL_ AWC SG_ 1716 VIN_1 2000;
BA_REL_ "GenSigTimeoutTime" BU_SG_REL_ Ladegeraet_Konzern SG_ 1716 VIN_1 2000;
BA_REL_ "GenSigTimeoutTime" BU_SG_REL_ TME SG_ 1716 VIN_1 2000;
BA_REL_ "GenSigTimeoutTime" BU_SG_REL_ AWC SG_ 1716 VIN_8 2000;
BA_REL_ "GenSigTimeoutTime" BU_SG_REL_ Ladegeraet_Konzern SG_ 1716 VIN_8 2000;
BA_REL_ "GenSigTimeoutTime" BU_SG_REL_ TME SG_ 1716 VIN_8 2000;
BA_REL_ "GenSigTimeoutTime" BU_SG_REL_ AWC SG_ 1716 VIN_15 2000;
BA_REL_ "GenSigTimeoutTime" BU_SG_REL_ Ladegeraet_Konzern SG_ 1716 VIN_15 2000;
BA_REL_ "GenSigTimeoutTime" BU_SG_REL_ TME SG_ 1716 VIN_15 2000;
BA_REL_ "GenSigTimeoutTime" BU_SG_REL_ AWC SG_ 1716 VIN_2 2000;
BA_REL_ "GenSigTimeoutTime" BU_SG_REL_ Ladegeraet_Konzern SG_ 1716 VIN_2 2000;
BA_REL_ "GenSigTimeoutTime" BU_SG_REL_ TME SG_ 1716 VIN_2 2000;
BA_REL_ "GenSigTimeoutTime" BU_SG_REL_ AWC SG_ 1716 VIN_9 2000;
BA_REL_ "GenSigTimeoutTime" BU_SG_REL_ Ladegeraet_Konzern SG_ 1716 VIN_9 2000;
BA_REL_ "GenSigTimeoutTime" BU_SG_REL_ TME SG_ 1716 VIN_9 2000;
BA_REL_ "GenSigTimeoutTime" BU_SG_REL_ AWC SG_ 1716 VIN_16 2000;
BA_REL_ "GenSigTimeoutTime" BU_SG_REL_ Ladegeraet_Konzern SG_ 1716 VIN_16 2000;
BA_REL_ "GenSigTimeoutTime" BU_SG_REL_ TME SG_ 1716 VIN_16 2000;
BA_REL_ "GenSigTimeoutTime" BU_SG_REL_ AWC SG_ 1716 VIN_3 2000;
BA_REL_ "GenSigTimeoutTime" BU_SG_REL_ Ladegeraet_Konzern SG_ 1716 VIN_3 2000;
BA_REL_ "GenSigTimeoutTime" BU_SG_REL_ TME SG_ 1716 VIN_3 2000;
BA_REL_ "GenSigTimeoutTime" BU_SG_REL_ AWC SG_ 1716 VIN_10 2000;
BA_REL_ "GenSigTimeoutTime" BU_SG_REL_ Ladegeraet_Konzern SG_ 1716 VIN_10 2000;
BA_REL_ "GenSigTimeoutTime" BU_SG_REL_ TME SG_ 1716 VIN_10 2000;
BA_REL_ "GenSigTimeoutTime" BU_SG_REL_ AWC SG_ 1716 VIN_17 2000;
BA_REL_ "GenSigTimeoutTime" BU_SG_REL_ Ladegeraet_Konzern SG_ 1716 VIN_17 2000;
BA_REL_ "GenSigTimeoutTime" BU_SG_REL_ TME SG_ 1716 VIN_17 2000;
BA_REL_ "GenSigTimeoutTime" BU_SG_REL_ TME SG_ 1702 Wischer_vorne_aktiv 5000;
BA_REL_ "GenSigTimeoutTime" BU_SG_REL_ TME SG_ 1702 Waschen_vorne_aktiv 5000;
BA_REL_ "GenSigTimeoutTime" BU_SG_REL_ TME SG_ 1140 ZR_SpannungSaeule 5000;
BA_REL_ "GenSigTimeoutTime" BU_SG_REL_ TME SG_ 1140 ZR_LeistungSaeule 5000;
BA_REL_ "GenSigTimeoutTime" BU_SG_REL_ TME SG_ 1140 ZR_t_naechsteLadung 5000;
BA_REL_ "GenSigTimeoutTime" BU_SG_REL_ Ladegeraet_Konzern SG_ 388 ZV_FT_verriegeln 5000;
BA_REL_ "GenSigTimeoutTime" BU_SG_REL_ FCU_MLBevo_FCEV SG_ 388 ZV_FT_entriegeln 5000;
BA_REL_ "GenSigTimeoutTime" BU_SG_REL_ Ladegeraet_Konzern SG_ 388 ZV_FT_entriegeln 5000;
BA_REL_ "GenSigTimeoutTime" BU_SG_REL_ Ladegeraet_Konzern SG_ 388 ZV_BT_verriegeln 5000;
BA_REL_ "GenSigTimeoutTime" BU_SG_REL_ Ladegeraet_Konzern SG_ 388 ZV_BT_entriegeln 5000;
BA_REL_ "GenSigTimeoutTime" BU_SG_REL_ Ladegeraet_Konzern SG_ 1411 ZV_verriegelt_intern_ist 2000;
BA_REL_ "GenSigTimeoutTime" BU_SG_REL_ Ladegeraet_Konzern SG_ 1411 ZV_verriegelt_extern_ist 2000;
BA_REL_ "GenSigTimeoutTime" BU_SG_REL_ Ladegeraet_Konzern SG_ 1411 ZV_verriegelt_intern_soll 2000;
BA_REL_ "GenSigTimeoutTime" BU_SG_REL_ Ladegeraet_Konzern SG_ 1411 ZV_verriegelt_extern_soll 2000;
VAL_ 1399 TME_Leistung_Komfort_HV_stat 254 "Init" 255 "Fehler" ;
VAL_ 1399 TME_Leistung_Thermo_HV_stat 254 "Init" 255 "Fehler" ;
VAL_ 1399 TME_Energie_Komfort_NV 16382 "Init" 16383 "Fehler" ;
VAL_ 1399 TME_Energie_Thermo_NV 16382 "Init" 16383 "Fehler" ;
VAL_ 1399 TME_Leistung_Komfort_NV_stat 254 "Init" 255 "Fehler" ;
VAL_ 1399 TME_Leistung_Thermo_NV_stat 254 "Init" 255 "Fehler" ;
VAL_ 1375 TME_VoKo_Strategie_Anzeige 0 "Inaktiv" 1 "Standby" 2 "Lueften_elektrisch" 3 "Lueften_konventionell" 4 "Kuehlen_elektrisch" 5 "Reheat_elektrisch" 6 "Heizen_elektrisch" 7 "Heizen_verbrennungstechnisch" 8 "Reserve" 14 "Init" 15 "Fehler" ;
VAL_ 1375 TME_Zuheizer_Freigabe 0 "keine_Freigabe" 1 "Freigabe" ;
VAL_ 1375 TME_AC_LED 0 "LED_aus" 1 "LED_ein" ;
VAL_ 1375 TME_Heizstrategie 0 "Init" 1 "Aus" 2 "Spuelen" 3 "Kanalkuehlung" 4 "Kuehhlwasserzirkulation" 5 "aktive_Kuehlung" 6 "Heizen" 7 "Reheat" 8 "Heizen_elektrisch" 9 "Heizen_verbrennungstechnisch" 10 "Konditionierung_n_moeglich" 11 "Heizstrategie_11" 12 "Heizstrategie_12" 13 "Heizstrategie_13" 14 "Heizstrategie_14" 15 "Fehler" ;
VAL_ 1375 TME_Systemstatus 0 "System_IO" 1 "System_reduziert__Akkustik" 2 "System_reduziert__HV_Management" 3 "Fehler" ;
VAL_ 1375 TME_Kbr_Innenraum 0 "nicht_verfuegbar" 1 "verfuegbar" ;
VAL_ 1375 TME_Freigabe_Vorkond 0 "keine_Freigabe" 1 "Freigabe" ;
VAL_ 1375 TME_Verdampfer_Status 0 "inaktiv" 1 "aktiv" ;
VAL_ 1375 TME_Kuehlmittel_Sensor 0 "Kuehlkreis_OK" 1 "Kuehlmittelmangel_Pumpenfehler" ;
VAL_ 1375 TME_AC_Rueckmeldung 0 "EKK_laeuft_nicht" 1 "EKK_laeuft_reduziert" 2 "EKK_laeuft" 3 "Fehler" ;
VAL_ 1375 TME_Heizungspumpen_Anst 13 "Fehler" 14 "Init" 15 "nicht_verbaut" ;
VAL_ 1375 TME_Frischluftklappe_Soll 126 "Init" 127 "Fehler" ;
VAL_ 1375 TME_Freigabe_Luft_PTC 0 "keine_Freigabe" 1 "Freigabe" ;
VAL_ 1375 TME_Umluftklappe_Soll 126 "Init" 127 "Fehler" ;
VAL_ 1375 TME_Waermepumpe_aktiv 0 "inaktiv" 1 "aktiv" ;
VAL_ 1375 TME_Absperrventil1_oeffnen 0 "nicht_verfuegbar" 1 "Ansteuerung_Ventil_zulaessig" 2 "Ventil_oeffnen_oder_geoeffnet" 3 "Ventil_schliessen_oder_geschlossen" ;
VAL_ 1375 TME_Klima_Defizit 254 "Init" 255 "Fehler" ;
VAL_ 1375 TME_Temp_KM_vor_HWT 254 "Init" 255 "Fehler" ;
VAL_ 1373 TME_Geblaese 0 "Geblaese_aus_INIT" 1 "Geblaese_Regelung" 2 "Geblaese_Notlauf" ;
VAL_ 1373 TME_Kond_Innen_Betrieb 0 "INIT" 1 "Voko_aktiv" 2 "Voko_inaktiv" 3 "Systemfehler_Standheizung" 4 "Systemfehler_HV_Komponente" 5 "Systemfehler_Sthzg_und_HV_Komp" 6 "Systemeinschr_Kraftstoff_Reserve" 7 "Systemeinschr_HV_Batt_low" 8 "Systemeinschr_LV_Batt_low" ;
VAL_ 1373 TME_Klimadefizit 0 "Kein_Leistungsdefizit" 1 "Leistungsdefizit_erkannt" ;
VAL_ 1373 TME_STH_Status 0 "INIT" 1 "Sthzg_iO" 2 "Tankwarnung" 3 "BEM_Einschraenkung" 4 "Systemstoerung" 5 "__" 6 "__" 7 "Fehler" ;
VAL_ 1373 TME_Kond_Innen_Status 0 "INIT" 1 "Kond_Innen_moeglich" 2 "Systemfehler_Standheizung" 3 "Systemfehler_HV_Komp" 4 "Systemfehler_Sthzg_und_HV_Komp" 5 "Systemeinschr_Kraftstoff_Reserve" 6 "Systemeinschr_HV_Batt_low" 7 "Systemeinschr_LV_Batt_low" 8 "Reserve" 9 "Reserve" 10 "Reserve" 11 "Reserve" 12 "Reserve" 13 "Reserve" 14 "Reserve" 15 "Reserve" ;
VAL_ 1373 TME_STH_Ansteuerung 0 "AUS" 1 "EIN" ;
VAL_ 1373 TME_Verdampfertemperatur 1022 "Init" 1023 "Fehler" ;
VAL_ 1373 TME_Temp_KM_vor_LE 254 "Init" 255 "Fehler" ;
VAL_ 1373 TME_Kuehlmittel_Temp_Pumpe1_tNT 254 "Init" 255 "Fehler" ;
VAL_ 1373 TME_STH_aktiv 0 "INIT" 1 "Standheizung_aktiv" 2 "Standheizung_nicht_aktiv" 3 "Fehler" ;
VAL_ 1373 TME_SKE_Status_2 0 "Init" 1 "geschlossen" 2 "offen" 3 "Fehler" ;
VAL_ 1373 TME_STL_aktiv 0 "INIT" 1 "Standlueften_aktiv" 2 "Standlueften_nicht_aktiv" 3 "Fehler" ;
VAL_ 1373 TME_Thermomanagement 0 "keine_Freigabe_TMM__max_Heizbedarf" 1 "kleine_Freigabe_TMM" 2 "mittlere_Freigabe_TMM" 3 "volle_Freigabe_TMM__kein_Heizbedarf" ;
VAL_ 1373 TME_IstSpannung_EKK_HV 255 "Init/ Not Avail" ;
VAL_ 1657 TME_Temp_KM_nach_EM 253 "Nicht_verbaut" 254 "Init" 255 "Fehler" ;
VAL_ 1657 TME_EKK_ProtectionMode 0 "ProtectionMode_inactive" 1 "ProtectionMode_active" ;
VAL_ 1657 TME_Klimaanforderung 0 "keine_Anforderung_durch_TME" 1 "Klimaleistungspraediktion_aktiv" 2 "berechnung_Vorkonditionierung_aktiv" 3 "Vorkonditionierung_aktiv" ;
VAL_ 1657 TME_SKE_Pos_Summe 14 "Init" ;
VAL_ 1657 TME_Waermebilanz_Status 0 "kein_Fehler" 1 "TP_TC_OBDI" 2 "TP_TC_OBDII" 3 "Fehler" ;
VAL_ 1657 TME_Waermebilanz 0 "kein_Waermestrom" 1 "kleiner_Waermestrom" 2 "mittlerer_Waermestrom" 3 "hoher_Waermestrom" ;
VAL_ 1657 TME_Klimaleistung 126 "Init" ;
VAL_ 1657 TME_SKE_PosResp 0 "SKE_Soll_nicht_erreicht" 1 "SKE_Soll_erreicht" ;
VAL_ 1657 TME_SKE_Position_1 0 "Geoeffnet" 1 "Teilgeschlossen" 2 "Geschlossen" 3 "Init" ;
VAL_ 1657 TME_Systemtemp 254 "Init" 255 "Fehler" ;
VAL_ 1657 TME_Eingriff_SKE_Oeffnung 0 "Init" 1 "offen" 2 "teilgeschlossen" 3 "geschlossen" ;
VAL_ 1657 TME_SKE_Status 0 "Init" 1 "geschlossen" 2 "offen" 3 "Fehler" ;
VAL_ 1657 TME_Status_Kuehlmittel_Tmp_CrChk 0 "Pruefung_nicht_erfolgt" 1 "kein_Fehler_Kuehlmittel_Temp" 2 "Fehler_Kuehlmittel_Temp" ;
VAL_ 1657 TME_Temperatur_Ruecklauf_VKM 254 "Init" 255 "Fehler" ;
VAL_ 2463978655 TME_Senkenleistung_verfuegbar 510 "Init" 511 "Fehler" ;
VAL_ 2589283463 TME_THMTVLV_Sollstellung 126 "Init" 127 "Fehler" ;
VAL_ 2589283463 TME_Mischventil_Heizkreis_Ist 126 "Init" 127 "Fehler" ;
VAL_ 2589283463 TME_Ionenspuelung_aktiv 0 "Inaktiv" 1 "Aktiv" ;
VAL_ 2589283463 TME_Temp_KM_v_Pumpe_Heizkreis 254 "Init" 255 "Fehler" ;
VAL_ 2589283463 TME_Temp_KM_n_Mischventil_Heizkr 254 "Init" 255 "Fehler" ;
VAL_ 2589283463 TME_Befuellung_aktiv 0 "Inaktiv" 1 "Aktiv" ;
VAL_ 2589283463 TME_Entlueftung_aktiv 0 "Inaktiv" 1 "Aktiv" ;
VAL_ 2589283463 TME_KMP_Solldrehzahl 16382 "Init" 16383 "Fehler" ;
VAL_ 2589283408 SKE1_AOCCT_timer1_count 0 "inactive" 1 "active" ;
VAL_ 2589283408 SKE1_AOCCT_timer2_count 0 "inactiv" 1 "active" ;
VAL_ 2589283408 SKE1_AOCCT_teststatus 0 "diag_incomplete" 1 "diag_complete" ;
VAL_ 2589283408 SKE2_AOCCT_timer1_verbaut 0 "not_current" 1 "installed_and_coded" ;
VAL_ 2589283408 SKE2_AOCCT_timer1_count 0 "inactive" 1 "active" ;
VAL_ 2589283408 SKE2_AOCCT_timer2_verbaut 0 "not_current" 1 "installed_and_coded" ;
VAL_ 2589283408 SKE2_AOCCT_timer2_count 0 "inactive" 1 "active" ;
VAL_ 2589283408 SKE2_AOCCT_fehlerstatus 0 "no_failure" 1 "failure" ;
VAL_ 2589283408 SKE2_AOCCT_teststatus 0 "diag_incomplete" 1 "diag_complete" ;
VAL_ 2589283408 SKE1_AOCCT_timer1_verbaut 0 "not_current" 1 "installed_and_coded" ;
VAL_ 2589283408 SKE1_AOCCT_fehlerstatus 0 "no_failure" 1 "failure" ;
VAL_ 2589283408 SKE1_AOCCT_timer2_verbaut 0 "not_current" 1 "installed_and_coded" ;
VAL_ 2527679716 TME_ThermoPred_P_dyn_BTL_FP1 510 "Init" 511 "Fehler" ;
VAL_ 2527679716 TME_ThermoPred_P_stat_Klima_FP1 2046 "Init" 2047 "Fehler" ;
VAL_ 2527679716 TME_ThermoPred_P_dyn_Klima_FP1 2046 "Init" 2047 "Fehler" ;
VAL_ 2527679716 TME_ThermoPred_T_dyn_BTL_FP1 254 "Init" 255 "Fehler" ;
VAL_ 2527679716 TME_ThermoPred_T_dyn_Klima_FP1 254 "Init" 255 "Fehler" ;
VAL_ 2527679717 TME_ThermoPred_P_dyn_BTL_FP2 510 "Init" 511 "Fehler" ;
VAL_ 2527679717 TME_ThermoPred_P_stat_Klima_FP2 2046 "Init" 2047 "Fehler" ;
VAL_ 2527679717 TME_ThermoPred_P_dyn_Klima_FP2 2046 "Init" 2047 "Fehler" ;
VAL_ 2527679717 TME_ThermoPred_T_dyn_BTL_FP2 254 "Init" 255 "Fehler" ;
VAL_ 2527679717 TME_ThermoPred_T_dyn_Klima_FP2 254 "Init" 255 "Fehler" ;
VAL_ 2527679718 TME_ThermoPred_P_dyn_BTL_FP3 510 "Init" 511 "Fehler" ;
VAL_ 2527679718 TME_ThermoPred_P_stat_Klima_FP3 2046 "Init" 2047 "Fehler" ;
VAL_ 2527679718 TME_ThermoPred_P_dyn_Klima_FP3 2046 "Init" 2047 "Fehler" ;
VAL_ 2527679718 TME_ThermoPred_T_dyn_BTL_FP3 254 "Init" 255 "Fehler" ;
VAL_ 2527679718 TME_ThermoPred_T_dyn_Klima_FP3 254 "Init" 255 "Fehler" ;
VAL_ 2463978733 TME_ThermoPred_P_dyn_Btl 510 "Init" 511 "Fehler" ;
VAL_ 2463978733 TME_ThermoPred_T_dyn_Btl 254 "Init" 255 "Fehler" ;
VAL_ 977 BT_Tuer_geoeffnet 0 "geschlossen" 1 "offen" ;
VAL_ 977 BT_verriegelt 1 "verriegelt" ;
VAL_ 977 BT_gesafet 1 "gesafet" ;
VAL_ 977 BT_Schluesselschalter_auf 1 "Schluesselschalter auf betaetigt" ;
VAL_ 977 BT_Schluesselschalter_zu 1 "Schluesselschalter zu betaetigt" ;
VAL_ 977 BT_Unlock_Taster 1 "Unlock Taster betaetigt" ;
VAL_ 977 BT_Lock_Taster 1 "Lock Taster betaetigt" ;
VAL_ 977 BT_Sperrklinke 0 "Schloss_in_Vorraste_und_Hauptraste" 1 "Tuer_auf_oder_Tuer_Position_zwischen_Vor_und_Hauptraste" ;
VAL_ 977 BT_TAG_betaetigt 1 "Tuerinnengriff_betaetigt" ;
VAL_ 977 BT_TIG_betaetigt 0 "Init" 1 "Tuerinnengriff_betaetigt" ;
VAL_ 977 BT_Tuer_Status 0 "Init" 1 "Tuer geschlossen" 2 "Tuer offen" 3 "Fehler" ;
VAL_ 977 BT_TSG_hinten_verbaut 0 "nicht verbaut" 1 "verbaut" ;
VAL_ 977 BT_Sp_Blk_def 0 "iO" 1 "Spiegel Blinker defekt" ;
VAL_ 977 BT_FH_S_ManHoch 0 "Init" 1 "FH_Schalter_man_hoch_gedrueckt" ;
VAL_ 977 BT_FH_S_AutoHoch 0 "Init" 1 "FH_Schalter_auto_hoch_gedrueckt" ;
VAL_ 977 BT_FH_S_ManTief 0 "Init" 1 "FH_Schalter_man_tief_gedrueckt" ;
VAL_ 977 BT_FH_S_AutoTief 0 "Init" 1 "FH_Schalter_auto_tief_gedrueckt" ;
VAL_ 977 BT_FH_Bew_hoch 0 "Init" 1 "FH_ist_in_Bewegung_hoch" ;
VAL_ 977 BT_FH_Bew_tief 0 "Init" 1 "FH_ist_in_Bewegung_tief" ;
VAL_ 977 BT_FH_Fang 0 "ausserhalb_Fangbereich" 1 "innerhalb_Fangbereich" ;
VAL_ 977 BT_FH_Block 0 "Init" 1 "Fensterheber_Block" ;
VAL_ 977 BT_FH_Thermo 0 "Init" 1 "Thermoschutz_aktiv" ;
VAL_ 977 BT_UEKB_aktiviert 0 "Init" 1 "aktiv" ;
VAL_ 977 BT_Kisi_Fehler 0 "kein_Fehler" 1 "Fehler" ;
VAL_ 977 BT_FH_normiert 1 "Fenster_normiert" ;
VAL_ 977 BT_Schliesstaster 1 "betaetigt" ;
VAL_ 977 BT_Zuziehhilfe_aktiv 1 "Zuziehhilfe_aktiv" ;
VAL_ 977 BT_SP_ausgerastet 1 "Spiegel ausgerastet" ;
VAL_ 977 BT_SP_lr_aktiv 0 "Init" 1 "Spiegel_xAchse_aktiv" ;
VAL_ 977 BT_SP_ht_aktiv 0 "Init" 1 "Spiegel_yAchse_aktiv" ;
VAL_ 977 BT_SP_Heizung_aktiv 1 "BF Spiegelheizung ein" ;
VAL_ 977 BT_Oben_Block_erw 0 "Fensterheber nicht in Blockerwartung oben" 1 "Fensterheber in Blockerwartung oben" ;
VAL_ 977 BT_Unten_Block_erw 0 "Fensterheber_nicht_in_Blockerwar" 1 "Fensterheber_in_Blockerwartung_u" ;
VAL_ 977 BT_Tuer_Status_QBit 0 "Status_Tuerkontakt_sicher" 1 "Status_Tuerkontakt_unsicher" ;
VAL_ 977 BFS_Status_eTAG 0 "Init" 1 "Griff_ausgefahren" 2 "Griff_eingefahren" 3 "Fehler" ;
VAL_ 977 BT_TCR_Mode_aktiv 0 "TCR_Mode_deaktiv" 1 "TCR_Mode_aktiv" ;
VAL_ 977 BT_SP_Heizung_Status 0 "Init" 1 "Status_Spiegelheizung_ein" ;
VAL_ 977 ASW_Warnung_aktiv_BFS 0 "nicht_angefordert" 1 "angefordert" ;
VAL_ 977 BT_FH_Pos_oben 1 "Scheibe oben (nach Absenken auf Position) " ;
VAL_ 977 BT_Tuerschloss_defekt 0 "Tuerschloss funktionsfähig" 1 "Tuerschloss defekt" ;
VAL_ 977 BT_Tueroeffnen_Warnung 0 "Tuerwarnung_nicht_aktiv" 1 "Tuerwarnung_aktiv" ;
VAL_ 977 BT_Lock_Taster_inv 0 "Lock Taster betätigt" 1 "Lock Taster nicht betätigt" ;
VAL_ 977 BT_Schluesselschalter_zu_inv 0 "Schlüsselschalter betätigt" 1 "Schlüsselschalter nicht betätigt" ;
VAL_ 977 BT_SWA_HMI_defekt 0 "SWA_kein_Fehler" 1 "SWA_Fehler" ;
VAL_ 977 BT_ASW_HMI_defekt 0 "ASW_kein_Fehler" 1 "ASW_Fehler" ;
VAL_ 976 FT_Tuer_geoeffnet 0 "Init" 1 "Tuer offen" ;
VAL_ 976 FT_verriegelt 1 "verriegelt" ;
VAL_ 976 FT_gesafet 1 "gesafet" ;
VAL_ 976 FT_Schluesselschalter_auf 1 "Schluesselschalter auf betaetigt" ;
VAL_ 976 FT_Schluesselschalter_zu 1 "Schluesselschalter zu betaetigt" ;
VAL_ 976 FT_Unlock_Taster 1 "Unlock Taster betaetigt" ;
VAL_ 976 FT_Lock_Taster 1 "Lock Taster betaetigt" ;
VAL_ 976 FT_Sperrklinke 0 "Schloss_in_Vorraste_und_Hauptraste" 1 "Tuer_auf_oder_Tuer_Position_zwischen_Vor_und_Hauptraste" ;
VAL_ 976 FT_TAG_betaetigt 0 "nicht_betaetigt" 1 "betaetigt" ;
VAL_ 976 FT_TIG_betaetigt 0 "nicht_betaetigt" 1 "betaetigt" ;
VAL_ 976 FT_IRUE_Taste 0 "Init" 1 "IRUE_Taste_betaetigt" ;
VAL_ 976 FT_HD_Taste 1 "Heckdeckel oeffnen" ;
VAL_ 976 FT_TD_Taste_Fehler 0 "iO" 1 "defekt" ;
VAL_ 976 FT_TD_Taste 1 "Tankdeckelentriegelungs Taster gedrückt" ;
VAL_ 976 SSR_Temp_Freigabe 0 "SSR_Deaktiviert" 1 "SSR_Freigegeben" ;
VAL_ 976 FT_HD_Taste_2 0 "Taste_nicht_gedrueckt" 1 "Taste_gedrueckt" ;
VAL_ 976 FT_TSG_hinten_verbaut 0 "nicht verbaut" 1 "verbaut" ;
VAL_ 976 FT_Sp_Blk_def 0 "iO" 1 "defekt" ;
VAL_ 976 FT_FH_S_ManHoch 0 "Init" 1 "FH_Schalter_man_hoch_betaetigt" ;
VAL_ 976 FT_FH_S_AutoHoch 0 "Init" 1 "FH_Schalter_auto_hoch_betaetigt" ;
VAL_ 976 FT_FH_S_ManTief 0 "Init" 1 "FH_Schalter_man_tief_betaetigt" ;
VAL_ 976 FT_FH_S_AutoTief 0 "Init" 1 "FH_Schalter_auto_tief_betaetigt" ;
VAL_ 976 FT_FH_Bew_hoch 0 "Init" 1 "FH_in_Bewegung_hoch" ;
VAL_ 976 FT_FH_Bew_tief 0 "Init" 1 "FH_in_Bewegung_tief" ;
VAL_ 976 FT_FH_Fang 0 "ausserhalb_Fangbereich" 1 "innerhalb_Fangbereich" ;
VAL_ 976 FT_FH_Block 0 "Init" 1 "Fenster_Block" ;
VAL_ 976 FT_FH_Thermo 0 "Init" 1 "Thermoschutz_aktiv" ;
VAL_ 976 FT_UEKB_aktiviert 0 "Init" 1 "UEKB_aktiv" ;
VAL_ 976 ASW_HMI_defekt 0 "iO" 1 "defekt" ;
VAL_ 976 FT_FH_normiert 1 "Fenster_normiert" ;
VAL_ 976 FT_Schliesstaster 1 "Schliesstaster_betaetigt" ;
VAL_ 976 FT_Zuziehhilfe_aktiv 0 "Init" 1 "Zuziehilfe_aktiv" ;
VAL_ 976 FT_SP_ausgerastet 1 "Spiegel ausgerastet" ;
VAL_ 976 FT_SP_lr_aktiv 0 "Init" 1 "Spiegel_xAchse_aktiv" ;
VAL_ 976 FT_SP_ht_aktiv 0 "Init" 1 "Spiegel_yAchse_aktiv" ;
VAL_ 976 ASW_wakeup 0 "Sleep" 1 "Wakeup" ;
VAL_ 976 FT_Oben_Block_erw 0 "Fensterheber nicht in Blockerwartung oben" 1 "Fensterheber in Blockerwartung oben" ;
VAL_ 976 FT_Unten_Block_erw 0 "Fensterheber nicht in Blockerwartung unten" 1 "Fensterheber in Blockerwartung unten" ;
VAL_ 976 FT_Kisi_li_aktiv 0 "inaktiv" 1 "aktiv" ;
VAL_ 976 FT_Kisi_re_aktiv 0 "inaktiv" 1 "aktiv" ;
VAL_ 976 FT_Kisi_Taster_li 0 "nicht_betaetigt" 1 "betaetigt" ;
VAL_ 976 FT_Kisi_Taster_re 0 "nicht_betaetigt" 1 "betaetigt" ;
VAL_ 976 FT_BFS_Fond_Freigabe 0 "Init" 1 "Freigabe_fuer_Fondbedienung_BFS" ;
VAL_ 976 FT_Kisi_Fehler 0 "kein_Fehler" 1 "Fehler" ;
VAL_ 976 FT_Daemmglas 0 "Normalglas_verbaut" 1 "Daemmglas_verbaut" ;
VAL_ 976 FT_SP_Heizung_Status 0 "Init" 1 "Status_Spiegelheizung_ein" ;
VAL_ 976 ASW_Warnung_aktiv_FS 0 "nicht_angefordert" 1 "angefordert" ;
VAL_ 976 FT_FH_Pos_oben 1 "Scheibe oben (nach Absenken auf Position) " ;
VAL_ 976 FT_Tuerschloss_defekt 0 "Tuerschloss_funktionsfaehig" 1 "Tuerschloss_defekt" ;
VAL_ 976 FT_SWA_Taster 0 "Taster_nicht_betaetigt" 1 "Taster_betaetigt" ;
VAL_ 976 SWA_HMI_Diagnose 0 "kein_Fehler_erkannt" 1 "Fehler_Taster_erkannt" 2 "Fehler_LED_erkannt" 3 "Fehler_LED_und_Taster_erkannt" ;
VAL_ 976 FS_Status_eTAG 0 "Init" 1 "Griff_ausgefahren" 2 "Griff_eingefahren" 3 "Fehler" ;
VAL_ 975 HBFS_Tuer_geoeffnet 0 "geschlossen" 1 "offen" ;
VAL_ 975 HBFS_verriegelt 0 "nicht_verriegelt" 1 "verriegelt" ;
VAL_ 975 HBFS_gesafet 0 "nicht_gesafet" 1 "gesafet" ;
VAL_ 975 HBFS_Heckrollotaster_betaetigt 0 "keine_Verfahranweisung_in_Richtung_Hoch" 1 "In_Richtung_Hoch_Verfahren" ;
VAL_ 975 HBFS_Tuerschloss_defekt 0 "Tuerschloss funktionsfähig" 1 "Tuerschloss defekt" ;
VAL_ 975 HBFS_Unlock_Taster 0 "nicht_betaetigt" 1 "betaetigt" ;
VAL_ 975 HBFS_Lock_Taster 0 "nicht_betaetigt" 1 "betaetigt" ;
VAL_ 975 HBFS_Sperrklinke 0 "Schloss_in_Vorraste_und_Hauptraste" 1 "Tuer_auf_oder_Tuer_Position_zwischen_Vor_und_Hauptraste" ;
VAL_ 975 HBFS_TAG_betaetigt 0 "nicht_betaetigt" 1 "betaetigt" ;
VAL_ 975 HBFS_TIG_betaetigt 0 "nicht_betaetigt" 1 "betaetigt" ;
VAL_ 975 HBFS_FH_S_HFS_AutoHoch 0 "keine_Bedienung" 1 "Automatiklauf_Angefordert" ;
VAL_ 975 HBFS_FH_S_HFS_AutoTief 0 "keine_Bedienung" 1 "Automatiklauf_Angefordert" ;
VAL_ 975 HBFS_FH_S_HFS_ManHoch 0 "keine_Bedienung" 1 "Manueller_Lauf_Angefordert" ;
VAL_ 975 HBFS_FH_S_HFS_ManTief 0 "keine_Bedienung" 1 "Manueller_Lauf_Angefordert" ;
VAL_ 975 HBFS_Tuer_Status 0 "Init" 1 "Tuer geschlossen" 2 "Tuer offen" 3 "Fehler" ;
VAL_ 975 HBFS_SAD_Schalter 0 "nicht_betaetigt" 5 "AUF_manuell" 6 "AUF_automatik" 7 "ZU_manuell" 8 "ZU_automatik" 13 "nicht_verfuegbar" 14 "Init" 15 "Fehler" ;
VAL_ 975 HBFS_FH_S_ManHoch 0 "nicht_betaetigt" 1 "betaetigt" ;
VAL_ 975 HBFS_FH_S_AutoHoch 0 "nicht_betaetigt" 1 "betaetigt" ;
VAL_ 975 HBFS_FH_S_ManTief 0 "nicht_betaetigt" 1 "betaetigt" ;
VAL_ 975 HBFS_FH_S_AutoTief 0 "nicht_betaetigt" 1 "betaetigt" ;
VAL_ 975 HBFS_FH_Bew_hoch 0 "inaktiv" 1 "aktiv" ;
VAL_ 975 HBFS_FH_Bew_tief 0 "inaktiv" 1 "aktiv" ;
VAL_ 975 HBFS_FH_Fang 0 "ausserhalb_Fangbereich" 1 "innerhalb_Fangbereich" ;
VAL_ 975 HBFS_FH_Block 0 "inaktiv" 1 "aktiv" ;
VAL_ 975 HBFS_FH_Thermo 0 "inaktiv" 1 "aktiv" ;
VAL_ 975 HBFS_UEKB_aktiviert 0 "inaktiv" 1 "aktiv" ;
VAL_ 975 HBFS_Tueroeffnen_Warnung 0 "Tuerwarnung_nicht_aktiv" 1 "Tuerwarnung_aktiv" ;
VAL_ 975 HBFS_FH_normiert 0 "inaktiv" 1 "aktiv" ;
VAL_ 975 ASW_Warnung_aktiv_HBFS 0 "nicht_angefordert" 1 "angefordert" ;
VAL_ 975 HBFS_Zuziehhilfe_aktiv 0 "Init" 1 "Zuziehhilfe_aktiv" ;
VAL_ 975 HBFS_Seitenrollo_hoch 1 "Seitenrollo_in_Bewegung_hoch" ;
VAL_ 975 HBFS_Seitenrollo_tief 1 "Seitenrollo_in_Bewegung_tief" ;
VAL_ 975 HBFS_Status_KiSi 0 "inaktiv" 1 "aktiv" ;
VAL_ 975 SSR_HBFS_Pos_Unten 0 "SSR_Oben" 1 "SSR_Unten" ;
VAL_ 975 HBFS_Oben_Block_erw 0 "Fensterheber_nicht_in_Blockerwartung_oben" 1 "Fensterheber in Blockerwartung oben" ;
VAL_ 975 HBFS_Unten_Block_erw 0 "Fensterheber_nicht_in_Blockerwartung_unten" 1 "Fensterheber in Blockerwartung unten" ;
VAL_ 975 MTHBFS_M_Taste 0 "nicht_betaetigt" 1 "betaetigt" ;
VAL_ 975 MTHBFS_Pos1 0 "nicht_betaetigt" 1 "betaetigt" ;
VAL_ 975 MTHBFS_Pos2 0 "nicht_betaetigt" 1 "betaetigt" ;
VAL_ 975 MTHBFS_Pos3 0 "nicht_betaetigt" 1 "betaetigt" ;
VAL_ 975 HBFS_MRollo_Schalter 0 "nicht_betaetigt" 1 "ZU_manuell" 2 "ZU_automatik" 3 "AUF_manuell" 4 "AUF_automatik" 5 "nicht_verfuegbar" 6 "Init" 7 "Fehler" ;
VAL_ 975 HBFS_Lock_Taster_inv 0 "Lock Taster betätgit" 1 "Lock Taster nicht betätigt" ;
VAL_ 975 HBFS_Status_KiSi_inv 0 "aktiv" 1 "inaktiv" ;
VAL_ 975 HBFS_Status_eTAG 0 "Init" 1 "Griff_ausgefahren" 2 "Griff_eingefahren" 3 "Fehler" ;
VAL_ 975 HBFS_Tuer_Status_QBit 0 "Status_Tuerkontakt_sicher" 1 "Status_Tuerkontakt_unsicher" ;
VAL_ 975 HBFS_TIG_betaetigt_schliessen 0 "nicht_betaetigt" 1 "betaetigt" ;
VAL_ 974 HFS_Tuer_geoeffnet 0 "geschlossen" 1 "offen" ;
VAL_ 974 HFS_verriegelt 0 "nicht_verriegelt" 1 "verriegelt" ;
VAL_ 974 HFS_gesafet 0 "nicht_gesafet" 1 "gesafet" ;
VAL_ 974 HFS_Heckrollotaster_betaetigt 0 "keine_Verfahranweisung_in_Richtung_Hoch" 1 "In_Richtung_Hoch_Verfahren" ;
VAL_ 974 HFS_Tuerschloss_defekt 0 "Tuerschloss funktionsfähig" 1 "Tuerschloss defekt" ;
VAL_ 974 HFS_Unlock_Taster 0 "nicht_betaetigt" 1 "betaetigt" ;
VAL_ 974 HFS_Lock_Taster 0 "nicht_betaetigt" 1 "betaetigt" ;
VAL_ 974 HFS_Sperrklinke 0 "Schloss_in_Vorraste_und_Hauptraste" 1 "Tuer_auf_oder_Tuer_Position_zwischen_Vor_und_Hauptraste" ;
VAL_ 974 HFS_TAG_betaetigt 0 "nicht_betaetigt" 1 "betaetigt" ;
VAL_ 974 HFS_TIG_betaetigt 0 "nicht_betaetigt" 1 "betaetigt" ;
VAL_ 974 HFS_FH_S_HBFS_AutoHoch 0 "keine_Bedienung" 1 "Automatiklauf_Angefordert" ;
VAL_ 974 HFS_FH_S_HBFS_AutoTief 0 "keine_Bedienung" 1 "Automatiklauf_Angefordert" ;
VAL_ 974 HFS_FH_S_HBFS_ManHoch 0 "keine_Bedienung" 1 "Manueller_Lauf_Angefordert" ;
VAL_ 974 HFS_FH_S_HBFS_ManTief 0 "keine_Bedienung" 1 "Manueller_Lauf_Angefordert" ;
VAL_ 974 HFS_Tuer_Status 0 "Init" 1 "Tuer geschlossen" 2 "Tuer offen" 3 "Fehler" ;
VAL_ 974 HFS_SAD_Schalter 0 "nicht_betaetigt" 5 "AUF_manuell" 6 "AUF_automatik" 7 "ZU_manuell" 8 "ZU_automatik" 13 "nicht_verfuegbar" 14 "Init" 15 "Fehler" ;
VAL_ 974 HFS_FH_S_ManHoch 0 "nicht_betaetigt" 1 "betaetigt" ;
VAL_ 974 HFS_FH_S_AutoHoch 0 "nicht_betaetigt" 1 "betaetigt" ;
VAL_ 974 HFS_FH_S_ManTief 0 "nicht_betaetigt" 1 "betaetigt" ;
VAL_ 974 HFS_FH_S_AutoTief 0 "nicht_betaetigt" 1 "betaetigt" ;
VAL_ 974 HFS_FH_Bew_hoch 0 "inaktiv" 1 "aktiv" ;
VAL_ 974 HFS_FH_Bew_tief 0 "inaktiv" 1 "aktiv" ;
VAL_ 974 HFS_FH_Fang 0 "ausserhalb_Fangbereich" 1 "innerhalb_Fangbereich" ;
VAL_ 974 HFS_FH_Block 0 "inaktiv" 1 "aktiv" ;
VAL_ 974 HFS_FH_Thermo 0 "inaktiv" 1 "aktiv" ;
VAL_ 974 HFS_UEKB_aktiviert 0 "inaktiv" 1 "aktiv" ;
VAL_ 974 HFS_Tueroeffnen_Warnung 0 "Tuerwarnung_nicht_aktiv" 1 "Tuerwarnung_aktiv" ;
VAL_ 974 HFS_FH_normiert 0 "inaktiv" 1 "aktiv" ;
VAL_ 974 ASW_Warnung_aktiv_HFS 0 "nicht_angefordert" 1 "angefordert" ;
VAL_ 974 HFS_Zuziehhilfe_aktiv 0 "Init" 1 "Zuziehhilfe_aktiv" ;
VAL_ 974 HFS_Seitenrollo_hoch 1 "Seitenrollo_in_Bewegung_hoch" ;
VAL_ 974 HFS_Seitenrollo_tief 1 "Seitenrollo_in_Bewegung_tief" ;
VAL_ 974 HFS_Status_KiSi 0 "inaktiv" 1 "aktiv" ;
VAL_ 974 SSR_HFS_Pos_Unten 0 "SSR_Oben" 1 "SSR_Unten" ;
VAL_ 974 HFS_Oben_Block_erw 0 "Fensterheber_nicht_in_Blockerwartung_oben" 1 "Fensterheber in Blockerwartung oben" ;
VAL_ 974 HFS_Unten_Block_erw 0 "Fensterheber_nicht_in_Blockerwartung_unten" 1 "Fensterheber in Blockerwartung unten" ;
VAL_ 974 MTHFS_M_Taste 0 "nicht_betaetigt" 1 "betaetigt" ;
VAL_ 974 MTHFS_Pos1 0 "nicht_betaetigt" 1 "betaetigt" ;
VAL_ 974 MTHFS_Pos2 0 "nicht_betaetigt" 1 "betaetigt" ;
VAL_ 974 MTHFS_Pos3 0 "nicht_betaetigt" 1 "betaetigt" ;
VAL_ 974 HFS_MRollo_Schalter 0 "nicht_betaetigt" 1 "ZU_manuell" 2 "ZU_automatik" 3 "AUF_manuell" 4 "AUF_automatik" 5 "nicht_verfuegbar" 6 "Init" 7 "Fehler" ;
VAL_ 974 HFS_Lock_Taster_inv 0 "Lock Taster betätgit" 1 "Lock Taster nicht betätigt" ;
VAL_ 974 HFS_Status_eTAG 0 "Init" 1 "Griff_ausgefahren" 2 "Griff_eingefahren" 3 "Fehler" ;
VAL_ 974 HFS_Tuer_Status_QBit 0 "Status_Tuerkontakt_sicher" 1 "Status_Tuerkontakt_unsicher" ;
VAL_ 974 HFS_TCR_Mode_aktiv 0 "TCR_Mode_deaktiv" 1 "TCR_Mode_aktiv" ;
VAL_ 916 WBA_Fahrstufe_02 0 "Zwischenstellung_keine_Position" 1 "Position_P" 2 "Position_R" 3 "Position_N" 4 "Position_D" 5 "Position_S" 6 "Position_M_Tippfunktion" 7 "Kurzzeit_M" 8 "Position_E" 9 "Position_MS" 10 "Position_S_Plus" 11 "Position_MS_Plus" 12 "Position_Offroad" 13 "Position_B" ;
VAL_ 916 WBA_ZielFahrstufe 0 "keine_Gangempfehlung_kein_Gang_eingelegt" 1 "Pfeil_nach_S" 2 "Pfeil_nach_D" 3 "Pfeil_nach_M" 4 "Pfeil_nach_E" ;
VAL_ 916 WBA_GE_Warnung_02 0 "keine_Anzeige" 1 "Fehlereskalationsstufe_I" 2 "Fehlereskalationsstufe_II" 3 "Weiterfahrt_nur_eingeschraenkt_moeglich__Kein_R_Gang" 4 "Getriebefehler_Weiterfahrt_nur_in_D_moeglich__P_bei_Motor_aus" 5 "Wegrollgefahr__P_nicht_moeglich" 6 "Paddlenotbetrieb_Schema+Warnung" 7 "Paddlenotbetrieb_Schema" 8 "Geschwindigkeitsbegrenzung_Notlauf" 9 "Fehlereskalationsst_o_Einschr" 10 "Fehlereskalationsstufe_v_Limit" 11 "Parksperre_Infostufe" 12 "Parksperre_Warnstufe_I" 13 "Parksperre_Warnstufe_II" ;
VAL_ 916 WBA_eing_Gang_02 0 "keine_Ganganzeige" 1 "Gang_1" 2 "Gang_2" 3 "Gang_3" 4 "Gang_4" 5 "Gang_5" 6 "Gang_6" 7 "Gang_7" 8 "Gang_8" 9 "Gang_9" 10 "Funktion_Ganganzeigeunterdrueckung" 11 "Gang_10" ;
VAL_ 916 WBA_GE_Texte 0 "keine_Anzeige" 1 "zum_Einlegen_einer_Fahrstufe_Fussbremse_betaetigen__ShiftLock_Information" 2 "zum_Einlegen_von_R_N_D_Fussbremse_betaetigen_und_Motor_starten" 3 "Wegrollgefahr_bitte_P_einlegen" 4 "Achtung_Zeitueberschreitung_P_wird_eingelegt" 5 "Wiederanmeldeprozedur_Bremse_betaetigen" 6 "P_nur_im_Stillstand_moeglich" 7 "Rennstart_aktiv" ;
VAL_ 916 WBA_Segeln_aktiv 0 "inaktiv" 1 "aktiv" ;
VAL_ 916 WBA_Schaltschema 0 "kein_Schaltschema" 1 "xxxD(S)" 2 "xxxD_S" 3 "xxxS(D)" 4 "xxxS_D" 5 "xxxM(D)" 6 "xxxM_D" 7 "xxxM(S)" 8 "xxxM_S" 9 "xxxE(D)" 10 "xxxE_D" 11 "xxxE(S)" 12 "xxxE_S" 13 "xxxE(M)" 14 "xxxE_M" ;
VAL_ 916 WBA_GE_Zusatzwarnungen 0 "keine_Anzeige" 1 "Getriebeueberhitzung_Warnstufe_I" 2 "Getriebeueberhitzung_Warnstufe_II" 3 "Getriebefehler_Bitte_anhalten_und_P_einlegen" ;
VAL_ 916 GE_Sollgang 0 "keine_Empfehlung" 1 "Gang_1" 2 "Gang_2" 3 "Gang_3" 4 "Gang_4" 5 "Gang_5" 6 "Gang_6" 7 "Gang_7" 8 "Gang_8" 9 "Gang_9" 11 "Gang_10" ;
VAL_ 916 GE_Tipschaltempf_verfuegbar 0 "nicht_verfuegbar" 1 "verfuegbar" ;
VAL_ 916 WBA_GE_Texte_02 0 "Keine_Anzeige" 1 "Fahrtrichtungswechsel_nur_nach_Stillstandt" 2 "Ladestecker_gesteckt" 3 "zusaetzlicher_Service_erforderlich" 4 "eLaunch_Aktiv" 5 "eLaunch_nicht_moeglich" 6 "WH_S_nicht_moeglich_Offroad" 7 "WH_S_nicht_moeglich_RangeMode" ;
VAL_ 916 WBA_GE_Texte_03 0 "init" 1 "LC_not_available" 2 "LCperformance_not_possible" 3 "LCperformance_possible" 4 "LCperformance_armed" 5 "LCperformance_preparation" 6 "LCperformance_launch" 7 "LCperformance_aborted" 8 "LCsmoke_not_possible" 9 "LCsmoke_possible" 10 "LCsmoke_armed" 11 "LCsmoke_launch" 12 "LCsmoke_aborted" 15 "Fehler" ;
VAL_ 916 WBA_Blinken 0 "kein_WBA_Blinken" 1 "WBA_Blinken" ;
VAL_ 916 GE_Wiederstart_Anz_Std 0 "keine_Anzeige" 1 "Standard_Wiederstartgrund" ;
VAL_ 916 GE_Stoppverbot_Anz_01 0 "keine_Anzeige" 1 "Temperaturbedingung" ;
VAL_ 916 GE_Stoppverbot_Anz_02 0 "keine_Anzeige" 1 "Drucksensorausfall" ;
VAL_ 916 GE_Stoppverbot_Anz_03 0 "keine_Anzeige" 1 "Grundeinstellung" ;
VAL_ 916 GE_Stoppverbot_Anz_04 0 "keine_Anzeige" 1 "Demontagestellung" ;
VAL_ 916 GE_Stoppverbot_Anz_05 0 "keine_Anzeige" 1 "Eingeschraenkte_Fahrfunktion_Notlauf_Liegenbleiber" ;
VAL_ 916 GE_Stoppverbot_Anz_06 0 "keine_Anzeige" 1 "Stoppverbot_ueber_Applikation" ;
VAL_ 916 GE_Stoppverbot_Anz_07 0 "keine_Anzeige" 1 "Schaltung_aktiv" ;
VAL_ 916 GE_Stoppverbot_Anz_Std 0 "keine_Anzeige" 1 "Standard_Stoppvetogrund" ;
VAL_ 1702 Wischer_vorne_aktiv 1 "Wischer vorne läuft" ;
VAL_ 1702 Waschen_vorne_aktiv 1 "Waschen aktiv" ;
VAL_ 1702 Wischer_vorne_Normal 1 "Wischer Front normal aktiv" ;
VAL_ 1702 Wischer_vorne_Schnell 1 "Wischer vorne schnell aktiv" ;
VAL_ 1702 Wischer_vorne_Parklage 0 "Wischer_Front_nicht_in_Parklage" 1 "Wischer_Front_in_Parklage__Initialzustand" ;
VAL_ 1702 Wischer_vorne_defekt 1 "Wischer vorne defekt" ;
VAL_ 1702 Wischer_vorne_blockiert 1 "Wischer vorne blockiert" ;
VAL_ 1702 Wischer1_Wischgeschwindigkeit 0 "0 U/min" 62 "Init" 63 "Fehler" ;
VAL_ 1702 BCM1_SRA_aktiv 0 "nicht aktiv" 1 "aktiv" ;
VAL_ 1702 Heckwischer_Anforderung 0 "Aus" 1 "Ein" ;
VAL_ 1702 WWSs_01_upd 0 "nicht_aktuell" 1 "aktuell" ;
VAL_ 1702 Wischer_Anzeigetext 0 "keine_Anzeige" 1 "Hinweis_Service_Position" 2 "void" 3 "void" ;
VAL_ 1140 ZR_State_DU_1 0 "Disp_Off" 1 "Disp_On" 2 "LowPow" ;
VAL_ 1140 ZR_State_DU_2 0 "Disp_Off" 1 "Disp_On" 2 "LowPow" ;
VAL_ 1140 ZR_State_DU_3 0 "Disp_Off" 1 "Disp_On" 2 "LowPow" ;
VAL_ 1140 ZR_WecktGesp 0 "entsperrt" 1 "gesperrt" ;
VAL_ 1140 MMI_State 0 "MMI_OFF" 1 "MMI_IOC" 2 "MMI_STDBY" 3 "MMI_ON" 4 "MMI_STDBY_PWR_SAVE" 5 "MMI_STDBY_RESTR" 6 "MMI_ON_DIAG" 7 "MMI_ON_TEL" 8 "MMI_ON_SWDL" 9 "MMI_ON_CUST_SWDL" 10 "MMI_STDBY_PWR_SAVE_1" 11 "MMI_STDBY_PWR_SAVE_2" 12 "MMI_STANDBY_CUST_SWDL" 13 "MMI_ONLINE_IOC" 14 "MMI_ONLINE" 15 "MMI_PHONE_IOC" 16 "MMI_PHONE" 17 "MMI_RTC" 18 "MMI_DCI" ;
VAL_ 1140 ZR_DimOffs_DU_1 14 "Init" ;
VAL_ 1140 ZR_DimOffs_DU_2 14 "Init" ;
VAL_ 1140 ZR_DimOffs_DU_3 14 "Init" ;
VAL_ 1140 SI_ICAN 0 "keine_Busruhe" 1 "Busruhe" ;
VAL_ 1140 ZR_Lenkerposition 0 "links" 1 "rechts" ;
VAL_ 1140 WLC1_Systemzustand 0 "Wireless_Charger_off" 1 "Wireless_Charger_on" ;
VAL_ 1140 WLC2_Systemzustand 0 "Wireless_Charger_off" 1 "Wireless_Charger_on" ;
VAL_ 1140 ZR_SpannungSaeule 0 "Spannung_800V" 1 "Spannung_400V" ;
VAL_ 1140 ZR_LeistungSaeule 0 "Leistung_0_bis_50kW" 1 "Leistung_50_bis_100kW" 2 "Leistung_100_bis_150kW" 3 "Leistung_groesser_150kW" ;
VAL_ 388 ZV_FT_verriegeln 0 "FT nicht verriegeln" 1 "FT verriegeln" ;
VAL_ 388 ZV_FT_entriegeln 0 "FT nicht entriegeln" 1 "FT entriegeln" ;
VAL_ 388 ZV_BT_verriegeln 0 "BT nicht verriegeln" 1 "BT verriegeln" ;
VAL_ 388 ZV_BT_entriegeln 0 "BT nicht entriegeln" 1 "BT ist zu entriegeln" ;
VAL_ 388 ZV_HFS_verriegeln 0 "inaktiv" 1 "aktiv" ;
VAL_ 388 ZV_HFS_entriegeln 0 "inaktiv" 1 "aktiv" ;
VAL_ 388 ZV_HBFS_verriegeln 0 "inaktiv" 1 "aktiv" ;
VAL_ 388 ZV_HBFS_entriegeln 0 "inaktiv" 1 "aktiv" ;
VAL_ 388 ZV_zentral_safen 0 "nicht safen" 1 "Befehl zentral safen" ;
VAL_ 388 ZV_zentral_entsafen 1 "Befehl zentral entsafen" ;
VAL_ 388 ZV_Spg_Anklappen 0 "inaktiv" 1 "aktiv" ;
VAL_ 388 ZV_Softtouch_betaetigt 0 "Softtouch_nicht_betaetigt" 1 "Softtouch betaetigt" ;
VAL_ 388 ZV_LED_Steuerung 0 "LED_aus" 1 "LED_ein" ;
VAL_ 388 ZV_LED_Uebernahme 1 "TSG uebernimmt LED Steuerung" ;
VAL_ 388 ZV_auf_FT 0 "nicht_betaetigt" 1 "betaetigt" ;
VAL_ 388 ZV_zu_FT 0 "nicht_betaetigt" 1 "betaetigt" ;
VAL_ 388 ZV_auf_BT 0 "nicht_betaetigt" 1 "betaetigt" ;
VAL_ 388 ZV_zu_BT 0 "nicht_betaetigt" 1 "betaetigt" ;
VAL_ 388 ZV_auf_Funk 0 "nicht_betaetigt" 1 "betaetigt" ;
VAL_ 388 ZV_zu_Funk 0 "nicht_betaetigt" 1 "betaetigt" ;
VAL_ 388 VIP_Sensor_betaetigt 0 "keine_Heckentriegelung_durch_VIP_Sensor_angefordert" 1 "Heckentriegelung_durch_VIP_Sensor_angefordert" ;
VAL_ 388 VIP_Freigabe 0 "keine_Freigabe" 1 "Freigabe" ;
VAL_ 388 ZV_zu_Zeitl_Nachverr 1 "Nachverriegeln" ;
VAL_ 388 ZV_HSK_entriegeln 0 "Handschuhkasten nicht entriegeln" 1 "Handschuhkasten entriegeln" ;
VAL_ 388 ZV_HSK_verriegeln 0 "Handschuhkasten nicht verriegeln" 1 "Handschuhkasten_verriegelt" ;
VAL_ 388 ZV_Verdeck_zu 0 "inaktiv" 1 "aktiv" ;
VAL_ 388 ZV_Verdeck_auf 0 "inaktiv" 1 "aktiv" ;
VAL_ 388 FH_FT_hoch 0 "keine_Anforderung" 1 "FT_hoch" ;
VAL_ 388 FH_FT_tief 0 "keine_Anforderung" 1 "FT_tief" ;
VAL_ 388 FH_BT_hoch 0 "keine_Anforderung" 1 "BT_hoch" ;
VAL_ 388 FH_BT_tief 0 "keine_Anforderung" 1 "BT_tief" ;
VAL_ 388 FH_HFS_hoch 0 "inaktiv" 1 "aktiv" ;
VAL_ 388 FH_HFS_tief 0 "inaktiv" 1 "aktiv" ;
VAL_ 388 FH_HBFS_hoch 0 "inaktiv" 1 "aktiv" ;
VAL_ 388 FH_HBFS_tief 0 "inaktiv" 1 "aktiv" ;
VAL_ 388 BCM_Spg_Synchron 0 "inaktiv" 1 "aktiv" ;
VAL_ 388 BCM_BF_Spg_Absenkung 0 "inaktiv" 1 "aktiv" ;
VAL_ 388 ZV_entriegeln_Anf 0 "nicht_betaetigt" 1 "betaetigt" ;
VAL_ 388 ZV_auto_Ansteuerung 0 "Kein_Autolock_Unlock" 1 "Autolock_Unlock" ;
VAL_ 1411 BCM_FH_Freigabe 1 "Funktionsfreigabe Fensterheber" ;
VAL_ 1411 BCM_Komfortfkt_Freigabe 0 "Komfortfunktion gesperrt" 1 "globale Freigabe der Komfortfunktion erteilt" ;
VAL_ 1411 BCM_HSK_Freigabe 0 "erlauben" 1 "sperren" ;
VAL_ 1411 BCM_Verdeck_Freigabe 0 "Verdeckbetrieb nicht erlaubt" 1 "Verdeckbetrieb erlaubt" ;
VAL_ 1411 ZV_verriegelt_intern_ist 1 "Fahrzeug innen verriegelt; Istzustand" ;
VAL_ 1411 ZV_verriegelt_extern_ist 1 "Fahrzeug_aussen_verriegelt_Istzustand" ;
VAL_ 1411 ZV_verriegelt_intern_soll 1 "Fahrzeug verriegelt intern; Sollzusstand" ;
VAL_ 1411 ZV_verriegelt_extern_soll 1 "Fahrzeug verriegelt extern; Sollzusstand" ;
VAL_ 1411 ZV_gesafet_extern_ist 1 "Fahrzeug aussen gesafet; Istzustand" ;
VAL_ 1411 ZV_gesafet_extern_soll 1 "Fahrzeug_aussen_gesafet_Sollzustand" ;
VAL_ 1411 ZV_Einzeltuerentriegelung 1 "Fahrzeug an Einzeltuer entriegelt" ;
VAL_ 1411 ZV_Heckeinzelentriegelung 1 "Heckdeckeleinzelentriegelung" ;
VAL_ 1411 ZV_FT_offen 1 "FT_geoeffnet" ;
VAL_ 1411 ZV_BT_offen 1 "BT_geoeffnet" ;
VAL_ 1411 ZV_HFS_offen 0 "geschlossen" 1 "offen" ;
VAL_ 1411 ZV_HBFS_offen 0 "geschlossen" 1 "offen" ;
VAL_ 1411 ZV_HD_offen 1 "Heckdeckel_auf" ;
VAL_ 1411 ZV_HS_offen 0 "Heckscheibe_geschlossen" 1 "Heckscheibe auf" ;
VAL_ 1411 IRUE_aktiv 0 "unscharf" 1 "scharf" ;
VAL_ 1411 DWA_aktiv 0 "unscharf" 1 "scharf" ;
VAL_ 1411 HD_Hauptraste 0 "geschlossen" 1 "offen" ;
VAL_ 1411 HD_Vorraste 0 "geschlossen" 1 "offen" ;
VAL_ 1411 FFB_CarFinder 0 "nicht aktiv" 1 "aktiv" ;
VAL_ 1411 FFB_Komfortoeffnen 0 "kein_Komfortoeffnen_empfangen" 1 "Komfortoeffnen ueber Funk empfangen" ;
VAL_ 1411 FFB_Komfortschliessen 0 "kein_Komfortschliessen_empfangen" 1 "Komfortschliessen ueber Funk empfangen" ;
VAL_ 1411 ZV_Schluessel_Zugang 0 "kein authorisierter Schluessel erkannt " 1 "aktive_Funkschluessel_Nr_01" 2 "aktive_Funkschluessel_Nr_02" 3 "aktive_Funkschluessel_Nr_03" 4 "aktive_Funkschluessel_Nr_04" 5 "aktive_Funkschluessel_Nr_05" 6 "aktive_Funkschluessel_Nr_06" 7 "aktive_Funkschluessel_Nr_07" 8 "aktive_Funkschluessel_Nr_08" 9 "ungueltig_09" 10 "ungueltig_10" 11 "ungueltig_11" 12 "ungueltig_12" 13 "ungueltig_13" 14 "ungueltig_14" 15 "ungueltig_15" ;
VAL_ 1411 ZV_SafeFunktion_aktiv 0 "inaktiv" 1 "aktiv" ;
VAL_ 1411 FBS_Warn_Schluessel_Batt 0 "i.O." 1 "defekt" ;
VAL_ 1411 ZV_Oeffnungsmodus 0 "globale_Oeffnung" 1 "ZV_mit_Einzeltuerentr" 2 "ZV_individuell_selektiv" 3 "ZV_seitenselektiv" ;
VAL_ 1411 HFS_verriegelt 0 "nicht_verriegelt" 1 "verriegelt" ;
VAL_ 1411 HFS_gesafet 0 "nicht_gesafet" 1 "gesafet" ;
VAL_ 1411 HBFS_verriegelt 0 "nicht_verriegelt" 1 "verriegelt" ;
VAL_ 1411 HBFS_gesafet 0 "nicht_gesafet" 1 "gesafet" ;
VAL_ 1411 ZV_ist_Zustand_verfuegbar 0 "nicht_verfuegbar" 1 "verfuegbar_alle_TSGs_am_Bus" ;
VAL_ 1411 IRUE_Taster_Fkts_LED 0 "LED_aus" 1 "LED_ein" ;
VAL_ 1411 ZV_Tankklappe_offen 0 "Tankklappe_geschlossen" 1 "Tankklappe_offen" ;
VAL_ 1411 ZV_Rollo_auf 0 "inaktiv" 1 "aktiv" ;
VAL_ 1411 ZV_Rollo_zu 0 "inaktiv" 1 "aktiv" ;
VAL_ 1411 ZV_SAD_auf 0 "inaktiv" 1 "aktiv" ;
VAL_ 1411 ZV_SAD_zu 0 "inaktiv" 1 "aktiv" ;
VAL_ 1411 BCM_Tankklappensteller_Fehler 0 "kein_Fehler" 1 "Fehler" ;
VAL_ 1411 ZV_verriegelt_soll 0 "Init" 1 "nicht_verriegelt" 2 "verriegelt" ;
